VERSION "created by canmatrix"

NS_ :

BS_:

BU_: IPD

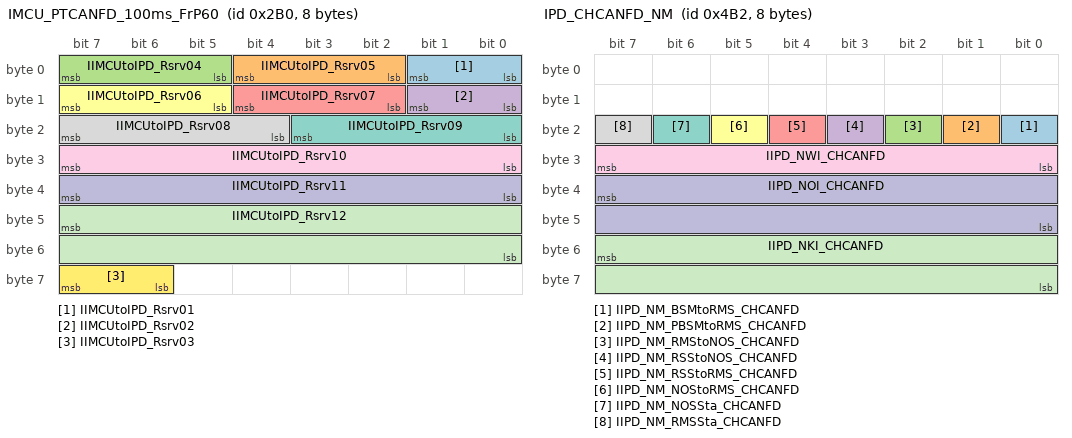
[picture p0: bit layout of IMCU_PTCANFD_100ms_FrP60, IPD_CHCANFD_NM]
BO_ 688 IMCU_PTCANFD_100ms_FrP60: 8 Vector__XXX
 SG_ IIMCUtoIPD_Rsrv01 : 1|2@0+ (1,0) [0|3] "null" IPD
 SG_ IIMCUtoIPD_Rsrv05 : 4|3@0+ (1,0) [0|7] "null" IPD
 SG_ IIMCUtoIPD_Rsrv04 : 7|3@0+ (1,0) [0|7] "null" IPD
 SG_ IIMCUtoIPD_Rsrv02 : 9|2@0+ (1,0) [0|3] "null" IPD
 SG_ IIMCUtoIPD_Rsrv07 : 12|3@0+ (1,0) [0|7] "null" IPD
 SG_ IIMCUtoIPD_Rsrv06 : 15|3@0+ (1,0) [0|7] "null" IPD
 SG_ IIMCUtoIPD_Rsrv09 : 19|4@0+ (1,0) [0|15] "null" IPD
 SG_ IIMCUtoIPD_Rsrv08 : 23|4@0+ (1,0) [0|15] "null" IPD
 SG_ IIMCUtoIPD_Rsrv10 : 31|8@0+ (1,0) [0|255] "null" IPD
 SG_ IIMCUtoIPD_Rsrv11 : 39|8@0+ (1,0) [0|255] "null" IPD
 SG_ IIMCUtoIPD_Rsrv12 : 47|16@0+ (1,0) [0|65535] "null" IPD
 SG_ IIMCUtoIPD_Rsrv03 : 63|2@0+ (1,0) [0|3] "null" IPD

BO_ 337 IPD_BKPCANFD_20ms_FrP60: 20 IPD
 SG_ IIPD_20ms_Group60_CRC : 7|8@0+ (1,0) [0|255] "null" Vector__XXX
 SG_ IIPD_20ms_Group60_RC : 11|4@0+ (1,0) [0|15] "null" Vector__XXX
 SG_ IAutoLaneChngRLaneSts : 15|4@0+ (1,0) [0|15] "null" Vector__XXX
 SG_ IIPD_20ms_Group60_Reserved1 : 23|8@0+ (1,0) [0|255] "null" Vector__XXX
 SG_ IIPD_20ms_Group60_Reserved2 : 31|8@0+ (1,0) [0|255] "null" Vector__XXX
 SG_ IAPASCSToqReqVal : 39|16@0+ (1,0) [0|65535] "Nm" Vector__XXX
 SG_ IAPAVehCrdnatPosY : 55|10@0+ (1,-512) [-512|511] "cm" Vector__XXX
 SG_ IAPAVehCrdnatAzmth : 56|9@0+ (1,0) [0|511] "degree" Vector__XXX
 SG_ IESSDirInd : 58|2@0+ (1,0) [0|3] "null" Vector__XXX
 SG_ IIPD_20ms_Group60_Reserved3 : 61|3@0+ (1,0) [0|7] "null" Vector__XXX
 SG_ IPilotTkovMsgReq : 75|4@0+ (1,0) [0|15] "null" Vector__XXX
 SG_ INOPSysSts_ZPD : 79|4@0+ (1,0) [0|15] "null" Vector__XXX
 SG_ IPrkgDstCtrlSwResp : 81|2@0+ (1,0) [0|3] "null" Vector__XXX
 SG_ IALCSysSts : 84|3@0+ (1,0) [0|7] "null" Vector__XXX
 SG_ IALCSysFltSts : 87|3@0+ (1,0) [0|7] "null" Vector__XXX
 SG_ IAPAVehCrdnatPosX : 95|12@0+ (1,-2048) [-2048|2047] "cm" Vector__XXX
 SG_ IAutoLaneChngLLaneSts : 99|4@0+ (1,0) [0|15] "null" Vector__XXX
 SG_ IIPD_20ms_Group60_Reserved4 : 105|2@0+ (1,0) [0|3] "null" Vector__XXX
 SG_ IESSSysSts : 108|3@0+ (1,0) [0|7] "null" Vector__XXX
 SG_ IESSSysFltSts : 111|3@0+ (1,0) [0|7] "null" Vector__XXX
 SG_ IIPD_20ms_Group60_Reserved5 : 112|1@0+ (1,0) [0|1] "null" Vector__XXX
 SG_ IESSDrvrTkovReq : 113|1@0+ (1,0) [0|1] "null" Vector__XXX
 SG_ ISLIFSysFltSts : 116|3@0+ (1,0) [0|7] "null" Vector__XXX
 SG_ IParkngslottype : 119|3@0+ (1,0) [0|7] "null" Vector__XXX
 SG_ IIPD_20ms_Group60_Reserved6 : 124|5@0+ (1,0) [0|31] "null" Vector__XXX
 SG_ INOPSysFltSts : 127|3@0+ (1,0) [0|7] "null" Vector__XXX
 SG_ IIPD_20ms_Group60_Reserved7 : 135|8@0+ (1,0) [0|255] "null" Vector__XXX
 SG_ IIPD_20ms_Group60_Reserved8 : 143|8@0+ (1,0) [0|255] "null" Vector__XXX
 SG_ IIPD_20ms_Group60_Reserved9 : 151|8@0+ (1,0) [0|255] "null" Vector__XXX
 SG_ IIPD_20ms_Group60_Reserved10 : 159|8@0+ (1,0) [0|255] "null" Vector__XXX

BO_ 590 IPD_BKPCANFD_50ms_FrP62: 32 IPD
 SG_ IRoadProfileShockDistL1 : 23|10@0+ (0.05,0) [0.00|51.15] "null" Vector__XXX
 SG_ IRoadProfileShockDistL2 : 25|10@0+ (0.05,0) [0.00|51.15] "null" Vector__XXX
 SG_ IRoadProfileShockDetectedL1 : 29|4@0+ (1,0) [0|15] "null" Vector__XXX
 SG_ IRoadProfileShockDistL3 : 47|10@0+ (0.05,0) [0.00|51.15] "null" Vector__XXX
 SG_ IRoadProfileShockDistR1 : 49|10@0+ (0.05,0) [0.00|51.15] "null" Vector__XXX
 SG_ IRoadProfileShockDetectedL2 : 53|4@0+ (1,0) [0|15] "null" Vector__XXX
 SG_ IRoadProfileShockDistR2 : 71|10@0+ (0.05,0) [0.00|51.15] "null" Vector__XXX
 SG_ IRoadProfileShockDistR3 : 73|10@0+ (0.05,0) [0.00|51.15] "null" Vector__XXX
 SG_ IRoadProfileShockDetectedL3 : 77|4@0+ (1,0) [0|15] "null" Vector__XXX
 SG_ IRoadProfileShockHeightL1 : 95|9@0- (0.002,0) [-0.512|0.510] "null" Vector__XXX
 SG_ IRoadProfileShockConfidenceL1 : 102|7@0+ (0.01,0) [0.00|1.27] "null" Vector__XXX
 SG_ IRoadProfileShockHeightL2 : 111|9@0- (0.002,0) [-0.512|0.510] "null" Vector__XXX
 SG_ IRoadProfileShockConfidenceL2 : 118|7@0+ (0.01,0) [0.00|1.27] "null" Vector__XXX
 SG_ IRoadProfileShockHeightL3 : 127|9@0- (0.002,0) [-0.512|0.510] "null" Vector__XXX
 SG_ IRoadProfileShockConfidenceL3 : 134|7@0+ (0.01,0) [0.00|1.27] "null" Vector__XXX
 SG_ IRoadProfileShockHeightR1 : 143|9@0- (0.002,0) [-0.512|0.510] "null" Vector__XXX
 SG_ IRoadProfileShockConfidenceR1 : 150|7@0+ (0.01,0) [0.00|1.27] "null" Vector__XXX
 SG_ IRoadProfileShockHeightR2 : 159|9@0- (0.002,0) [-0.512|0.510] "null" Vector__XXX
 SG_ IRoadProfileShockConfidenceR2 : 166|7@0+ (0.01,0) [0.00|1.27] "null" Vector__XXX
 SG_ IRoadProfileShockHeightR3 : 175|9@0- (0.002,0) [-0.512|0.510] "null" Vector__XXX
 SG_ IRoadProfileShockConfidenceR3 : 182|7@0+ (0.01,0) [0.00|1.27] "null" Vector__XXX
 SG_ IRoadHeightL : 191|9@0- (0.002,0) [-0.512|0.510] "null" Vector__XXX
 SG_ IPrvOutSts : 194|2@0+ (1,0) [0|3] "null" Vector__XXX
 SG_ IRoadProfileShockDetectedR1 : 198|4@0+ (1,0) [0|15] "null" Vector__XXX
 SG_ IRoadHeightR : 207|9@0- (0.002,0) [-0.512|0.510] "null" Vector__XXX
 SG_ IRoadProfileShockDetectedR3 : 219|4@0+ (1,0) [0|15] "null" Vector__XXX
 SG_ IRoadProfileShockDetectedR2 : 223|4@0+ (1,0) [0|15] "null" Vector__XXX

BO_ 1202 IPD_CHCANFD_NM: 8 IPD
 SG_ IIPD_NM_BSMtoRMS_CHCANFD : 16|1@0+ (1,0) [0|1] "null" Vector__XXX
 SG_ IIPD_NM_PBSMtoRMS_CHCANFD : 17|1@0+ (1,0) [0|1] "null" Vector__XXX
 SG_ IIPD_NM_RMStoNOS_CHCANFD : 18|1@0+ (1,0) [0|1] "null" Vector__XXX
 SG_ IIPD_NM_RSStoNOS_CHCANFD : 19|1@0+ (1,0) [0|1] "null" Vector__XXX
 SG_ IIPD_NM_RSStoRMS_CHCANFD : 20|1@0+ (1,0) [0|1] "null" Vector__XXX
 SG_ IIPD_NM_NOStoRMS_CHCANFD : 21|1@0+ (1,0) [0|1] "null" Vector__XXX
 SG_ IIPD_NM_NOSSta_CHCANFD : 22|1@0+ (1,0) [0|1] "null" Vector__XXX
 SG_ IIPD_NM_RMSSta_CHCANFD : 23|1@0+ (1,0) [0|1] "null" Vector__XXX
 SG_ IIPD_NWI_CHCANFD : 31|8@0+ (1,0) [0|255] "null" Vector__XXX
 SG_ IIPD_NOI_CHCANFD : 39|16@0+ (1,0) [0|65535] "null" Vector__XXX
 SG_ IIPD_NKI_CHCANFD : 55|16@0+ (1,0) [0|65535] "null" Vector__XXX

BO_ 157 LHZCU_LHBKBCANFD_10ms_FrP01: 8 Vector__XXX
 SG_ ILHZCU_10ms_Group01_CRC : 7|8@0+ (1,0) [0|255] "null" IPD
 SG_ ILHZCU_10ms_Group01_RC : 11|4@0+ (1,0) [0|15] "null" IPD
 SG_ ISCUFltLvlWarn : 13|2@0+ (1,0) [0|3] "null" IPD
 SG_ ISCUDrvMd : 15|2@0+ (1,0) [0|3] "null" IPD
 SG_ ISCUExtdShiftrFlr : 19|4@0+ (1,0) [0|15] "null" IPD
 SG_ ISCUShiftrOpngRmndr : 23|4@0+ (1,0) [0|15] "null" IPD
 SG_ IKeyAuthResp : 24|1@0+ (1,0) [0|1] "null" IPD
 SG_ ISCUParkLckReq : 26|2@0+ (1,0) [0|3] "null" IPD
 SG_ ISCUParkLckReqV : 27|1@0+ (1,0) [0|1] "null" IPD
 SG_ ILHZCU_10ms_Group01_Reserved1 : 30|3@0+ (1,0) [0|7] "null" IPD
 SG_ IDigKeyAuthReq : 31|1@0+ (1,0) [0|1] "null" IPD
 SG_ ISCUShiftrLvrRawPosn : 34|3@0+ (1,0) [0|7] "null" IPD
 SG_ ISCUParkLckReqVEPMCU : 35|1@0+ (1,0) [0|1] "null" IPD
 SG_ IScurtKeyInvd : 36|1@0+ (1,0) [0|1] "null" IPD
 SG_ ILHZCU_10ms_Group01_Reserved2 : 37|1@0+ (1,0) [0|1] "null" IPD
 SG_ ISCUParkLckReqEPMCU : 39|2@0+ (1,0) [0|3] "null" IPD
 SG_ ISCUShiftrPosnInvsn : 43|4@0+ (1,0) [0|15] "null" IPD
 SG_ ISCUShiftrLvrPosn : 47|4@0+ (1,0) [0|15] "null" IPD
 SG_ IDrvrReqParkBtn : 49|2@0+ (1,0) [0|3] "null" IPD
 SG_ ISCUShiftrLvrPosnLtchActv : 50|1@0+ (1,0) [0|1] "null" IPD
 SG_ ISecuKeyVldSts : 51|1@0+ (1,0) [0|1] "null" IPD
 SG_ ISCUDrvrIntrvnActv : 52|1@0+ (1,0) [0|1] "null" IPD
 SG_ ISCUAPAUnderCtrlActv : 55|3@0+ (1,0) [0|7] "null" IPD
 SG_ IDigKeyPEValidReq : 63|8@0+ (1,0) [0|255] "null" IPD

BO_ 546 LHZCU_LHBKBCANFD_50ms_FrP07: 16 Vector__XXX
 SG_ ILHZCU_50ms_Group07_CRC : 7|8@0+ (1,0) [0|255] "null" IPD
 SG_ ILHZCU_50ms_Group07_RC : 11|4@0+ (1,0) [0|15] "null" IPD
 SG_ ILHZCU_50ms_Group07_Reserved1 : 15|4@0+ (1,0) [0|15] "null" IPD
 SG_ IHODTchZone3Val : 23|8@0+ (1,0) [0|255] "null" IPD
 SG_ IHODTchZone1Val : 31|8@0+ (1,0) [0|255] "null" IPD
 SG_ IHODdiagSts : 35|4@0+ (1,0) [0|15] "null" IPD
 SG_ ILHZCU_50ms_Group07_Reserved2 : 39|4@0+ (1,0) [0|15] "null" IPD
 SG_ IHODDetnSts : 41|4@0+ (1,0) [0|15] "null" IPD
 SG_ IHODTchZone1Sts : 44|3@0+ (1,0) [0|7] "null" IPD
 SG_ IHODSysSts : 47|3@0+ (1,0) [0|7] "null" IPD
 SG_ IHODTchZone3Sts : 50|3@0+ (1,0) [0|7] "null" IPD
 SG_ IHODTchZone2Sts : 53|3@0+ (1,0) [0|7] "null" IPD
 SG_ IHODTchZone2Val : 63|8@0+ (1,0) [0|255] "null" IPD
 SG_ ILHZCU_50ms_Group07_Reserved3 : 71|8@0+ (1,0) [0|255] "null" IPD
 SG_ ILHZCU_50ms_Group07_Reserved4 : 79|8@0+ (1,0) [0|255] "null" IPD
 SG_ ILHZCU_50ms_Group07_Reserved5 : 87|8@0+ (1,0) [0|255] "null" IPD
 SG_ ILHZCU_50ms_Group07_Reserved6 : 95|8@0+ (1,0) [0|255] "null" IPD

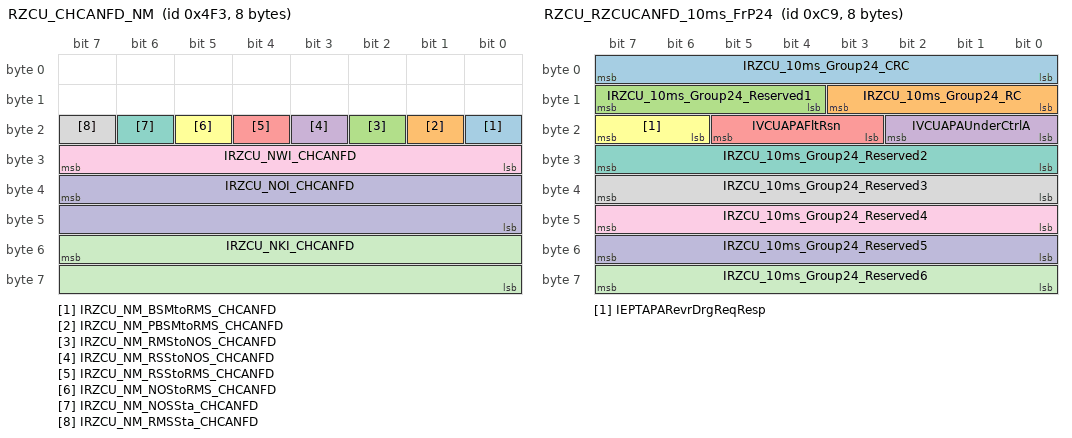
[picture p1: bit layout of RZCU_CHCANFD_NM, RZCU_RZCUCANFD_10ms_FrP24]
BO_ 1267 RZCU_CHCANFD_NM: 8 Vector__XXX
 SG_ IRZCU_NM_BSMtoRMS_CHCANFD : 16|1@0+ (1,0) [0|1] "null" Vector__XXX
 SG_ IRZCU_NM_PBSMtoRMS_CHCANFD : 17|1@0+ (1,0) [0|1] "null" Vector__XXX
 SG_ IRZCU_NM_RMStoNOS_CHCANFD : 18|1@0+ (1,0) [0|1] "null" Vector__XXX
 SG_ IRZCU_NM_RSStoNOS_CHCANFD : 19|1@0+ (1,0) [0|1] "null" Vector__XXX
 SG_ IRZCU_NM_RSStoRMS_CHCANFD : 20|1@0+ (1,0) [0|1] "null" Vector__XXX
 SG_ IRZCU_NM_NOStoRMS_CHCANFD : 21|1@0+ (1,0) [0|1] "null" Vector__XXX
 SG_ IRZCU_NM_NOSSta_CHCANFD : 22|1@0+ (1,0) [0|1] "null" Vector__XXX
 SG_ IRZCU_NM_RMSSta_CHCANFD : 23|1@0+ (1,0) [0|1] "null" Vector__XXX
 SG_ IRZCU_NWI_CHCANFD : 31|8@0+ (1,0) [0|255] "null" Vector__XXX
 SG_ IRZCU_NOI_CHCANFD : 39|16@0+ (1,0) [0|65535] "null" Vector__XXX
 SG_ IRZCU_NKI_CHCANFD : 55|16@0+ (1,0) [0|65535] "null" Vector__XXX

BO_ 1611 RZCU_RZCUCANFD_1000ms_FrP67: 16 Vector__XXX
 SG_ IIMU_SN : 16|96@1- (1,0) [-3.961408125713216879677197517E+028|3.961408125713216879677197517E+028] "null" IPD

BO_ 247 RZCU_RZCUCANFD_10ms_FrP22: 16 Vector__XXX
 SG_ IRZCU_10ms_Group22_CRC : 7|8@0+ (1,0) [0|255] "null" IPD
 SG_ IRZCU_10ms_Group22_RC : 11|4@0+ (1,0) [0|15] "null" IPD
 SG_ IRZCU_10ms_Group22_Reserved1 : 13|2@0+ (1,0) [0|3] "null" IPD
 SG_ IEPTTrOtptShaftTotMinAvlblToqV : 14|1@0+ (1,0) [0|1] "null" IPD
 SG_ IEPTTrOtptShaftTotMaxAvlblToqV : 15|1@0+ (1,0) [0|1] "null" IPD
 SG_ IEPTTrOtptShaftTotMaxAvlblToq : 23|12@0+ (0.5,-848) [-848|1199.5] "Nm" IPD
 SG_ IEPTTrOtptShaftTotMinAvlblToq : 27|12@0+ (0.5,-848) [-848|1199.5] "Nm" IPD
 SG_ IEPTTrOtptShaftTotToq : 43|12@0+ (0.5,-848) [-848|1199.5] "Nm" IPD
 SG_ IEPTTrOtptShaftTotToqV : 44|1@0+ (1,0) [0|1] "null" IPD
 SG_ IRZCU_10ms_Group22_Reserved2 : 47|3@0+ (1,0) [0|7] "null" IPD
 SG_ IRZCU_10ms_Group22_Reserved3 : 63|8@0+ (1,0) [0|255] "null" IPD
 SG_ IRZCU_10ms_Group22_Reserved4 : 71|8@0+ (1,0) [0|255] "null" IPD
 SG_ IRZCU_10ms_Group22_Reserved5 : 79|8@0+ (1,0) [0|255] "null" IPD
 SG_ IRZCU_10ms_Group22_Reserved6 : 87|8@0+ (1,0) [0|255] "null" IPD
 SG_ IRZCU_10ms_Group22_Reserved7 : 95|8@0+ (1,0) [0|255] "null" IPD

BO_ 201 RZCU_RZCUCANFD_10ms_FrP24: 8 Vector__XXX
 SG_ IRZCU_10ms_Group24_CRC : 7|8@0+ (1,0) [0|255] "null" IPD
 SG_ IRZCU_10ms_Group24_RC : 11|4@0+ (1,0) [0|15] "null" IPD
 SG_ IRZCU_10ms_Group24_Reserved1 : 15|4@0+ (1,0) [0|15] "null" IPD
 SG_ IVCUAPAUnderCtrlA : 18|3@0+ (1,0) [0|7] "null" IPD
 SG_ IVCUAPAFltRsn : 21|3@0+ (1,0) [0|7] "null" IPD
 SG_ IEPTAPARevrDrgReqResp : 23|2@0+ (1,0) [0|3] "null" IPD
 SG_ IRZCU_10ms_Group24_Reserved2 : 31|8@0+ (1,0) [0|255] "null" IPD
 SG_ IRZCU_10ms_Group24_Reserved3 : 39|8@0+ (1,0) [0|255] "null" IPD
 SG_ IRZCU_10ms_Group24_Reserved4 : 47|8@0+ (1,0) [0|255] "null" IPD
 SG_ IRZCU_10ms_Group24_Reserved5 : 55|8@0+ (1,0) [0|255] "null" IPD
 SG_ IRZCU_10ms_Group24_Reserved6 : 63|8@0+ (1,0) [0|255] "null" IPD

BO_ 143 RZCU_RZCUCANFD_10ms_FrP64: 32 Vector__XXX
 SG_ IRZCU_ZONE_10ms_Group64_CRC : 7|8@0+ (1,0) [0|255] "null" IPD
 SG_ IRZCU_ZONE_10ms_Group64_RC : 11|4@0+ (1,0) [0|15] "null" IPD
 SG_ IAngularRateXsecinfoV : 12|1@0+ (1,0) [0|1] "null" IPD
 SG_ IAccelerationZsecinfoV : 13|1@0+ (1,0) [0|1] "null" IPD
 SG_ IAccelerationYsecinfoV : 14|1@0+ (1,0) [0|1] "null" IPD
 SG_ IAccelerationXsecinfoV : 15|1@0+ (1,0) [0|1] "null" IPD
 SG_ IAccelerationXsecinfo : 23|24@0- (0.00010,0) [-838.86080|838.86070] "m/s2" IPD
 SG_ IAccelerationYsecinfo : 47|24@0- (0.00010,0) [-838.86080|838.86070] "m/s2" IPD
 SG_ IAccelerationZsecinfo : 71|24@0- (0.00010,0) [-838.86080|838.86070] "m/s2" IPD
 SG_ IAngularRateXsecinfo : 95|24@0- (0.000010,0) [-83.886080|83.886070] "°/s" IPD
 SG_ IAngularRateYsecinfo : 119|24@0- (0.000010,0) [-83.886080|83.886070] "°/s" IPD
 SG_ IAngularRateZsecinfo : 143|24@0- (0.000010,0) [-83.886080|83.886070] "°/s" IPD
 SG_ IIMUTmp : 163|12@0- (0.1,0) [-204.8|204.7] "degreecelslus" IPD
 SG_ IRZCU_ZONE_10ms_Group64_Reserved0 : 164|1@0+ (1,0) [0|1] "null" IPD
 SG_ ITireBlowoutStabCtrlSts : 165|1@0+ (1,0) [0|1] "null" IPD
 SG_ IAngularRateZsecinfoV : 166|1@0+ (1,0) [0|1] "null" IPD
 SG_ IAngularRateYsecinfoV : 167|1@0+ (1,0) [0|1] "null" IPD
 SG_ IIMUseq : 183|32@0+ (1,0) [0|4294967295] "/" IPD
 SG_ IRZCU_ZONE_10ms_Group64_Reserved1 : 211|4@0+ (1,0) [0|15] "null" IPD
 SG_ ITireBlowoutPos : 215|4@0+ (1,0) [0|15] "null" IPD
 SG_ IRZCU_ZONE_10ms_Group64_Reserved2 : 223|8@0+ (1,0) [0|255] "null" IPD
 SG_ IRZCU_ZONE_10ms_Group64_Reserved3 : 231|8@0+ (1,0) [0|255] "null" IPD
 SG_ IRZCU_ZONE_10ms_Group64_Reserved4 : 239|8@0+ (1,0) [0|255] "null" IPD
 SG_ IRZCU_ZONE_10ms_Group64_Reserved5 : 247|8@0+ (1,0) [0|255] "null" IPD
 SG_ IRZCU_ZONE_10ms_Group64_Reserved6 : 255|8@0+ (1,0) [0|255] "null" IPD

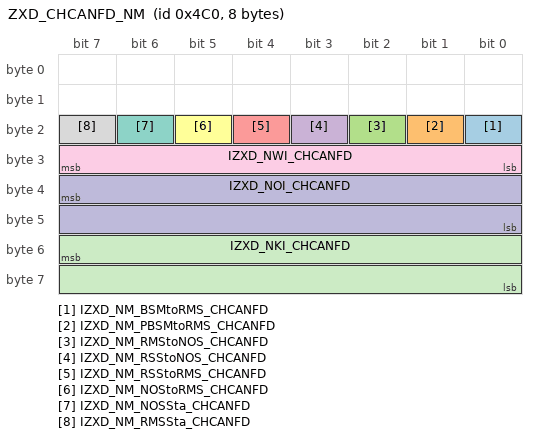
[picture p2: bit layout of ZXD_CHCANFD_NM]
BO_ 1216 ZXD_CHCANFD_NM: 8 Vector__XXX
 SG_ IZXD_NM_BSMtoRMS_CHCANFD : 16|1@0+ (1,0) [0|1] "null" Vector__XXX
 SG_ IZXD_NM_PBSMtoRMS_CHCANFD : 17|1@0+ (1,0) [0|1] "null" Vector__XXX
 SG_ IZXD_NM_RMStoNOS_CHCANFD : 18|1@0+ (1,0) [0|1] "null" Vector__XXX
 SG_ IZXD_NM_RSStoNOS_CHCANFD : 19|1@0+ (1,0) [0|1] "null" Vector__XXX
 SG_ IZXD_NM_RSStoRMS_CHCANFD : 20|1@0+ (1,0) [0|1] "null" Vector__XXX
 SG_ IZXD_NM_NOStoRMS_CHCANFD : 21|1@0+ (1,0) [0|1] "null" Vector__XXX
 SG_ IZXD_NM_NOSSta_CHCANFD : 22|1@0+ (1,0) [0|1] "null" Vector__XXX
 SG_ IZXD_NM_RMSSta_CHCANFD : 23|1@0+ (1,0) [0|1] "null" Vector__XXX
 SG_ IZXD_NWI_CHCANFD : 31|8@0+ (1,0) [0|255] "null" Vector__XXX
 SG_ IZXD_NOI_CHCANFD : 39|16@0+ (1,0) [0|65535] "null" Vector__XXX
 SG_ IZXD_NKI_CHCANFD : 55|16@0+ (1,0) [0|65535] "null" Vector__XXX

BO_ 308 ZXD_PTCANFD_20ms_FrP07: 8 IPD
 SG_ IZXD_20ms_Group07_CRC : 7|8@0+ (1,0) [0|255] "null" Vector__XXX
 SG_ IZXD_20ms_Group07_RC : 11|4@0+ (1,0) [0|15] "null" Vector__XXX
 SG_ IZXD_20ms_Group07_Reserved1 : 15|4@0+ (1,0) [0|15] "null" Vector__XXX
 SG_ IZXD_20ms_Group07_Reserved3 : 18|3@0+ (1,0) [0|7] "null" Vector__XXX
 SG_ IAPAEPBOPReq : 20|2@0+ (1,0) [0|3] "null" Vector__XXX
 SG_ IZXD_20ms_Group07_Reserved2 : 23|3@0+ (1,0) [0|7] "null" Vector__XXX
 SG_ IZXD_20ms_Group07_Reserved4 : 31|8@0+ (1,0) [0|255] "null" Vector__XXX
 SG_ IAIPkgAPASCSAcclReqVal : 34|11@0+ (0.005,-9.22) [-9.220|1.015] "m/s^2" Vector__XXX
 SG_ IZXD_20ms_Group07_Reserved5 : 37|3@0+ (1,0) [0|7] "null" Vector__XXX
 SG_ IAPASCSAcclReqSts : 38|1@0+ (1,0) [0|1] "null" Vector__XXX
 SG_ IAPAEPBOPReqV : 39|1@0+ (1,0) [0|1] "null" Vector__XXX
 SG_ IAutodDrvngSysSCSSdslReqV : 48|1@0+ (1,0) [0|1] "null" Vector__XXX
 SG_ IAutodDrvngSysSCSSdslReq : 49|1@0+ (1,0) [0|1] "null" Vector__XXX
 SG_ IZXD_20ms_Group07_Reserved6 : 55|6@0+ (1,0) [0|63] "null" Vector__XXX
 SG_ IAutodDrvngSysSCSDrvOffReqV : 56|1@0+ (1,0) [0|1] "null" Vector__XXX
 SG_ IAutodDrvngSysSCSDrvOffReq : 57|1@0+ (1,0) [0|1] "null" Vector__XXX
 SG_ IAutodDrvngSysMdReqV : 58|1@0+ (1,0) [0|1] "null" Vector__XXX
 SG_ IAutodDrvngSysMdReq : 59|1@0+ (1,0) [0|1] "null" Vector__XXX
 SG_ IAutodDrvngSysFlrStsV : 60|1@0+ (1,0) [0|1] "null" Vector__XXX
 SG_ IAutodDrvngSysFlrSts : 63|3@0+ (1,0) [0|7] "null" Vector__XXX

BO_ 429 EPS_CHCANFD_10ms_ConFrP01: 64 Vector__XXX
 SG_ Header_ID M : 7|24@0- (1,0) [-8388608|8388607] "" Vector__XXX
 SG_ Header_DLC : 31|8@0- (1,0) [-128|127] "" Vector__XXX
 SG_ IEPS_010ms_Group03_CRC m200707 : 39|8@0+ (1,0) [0|255] "null" IPD
 SG_ IEPS_010ms_Group03_RC m200707 : 43|4@0+ (1,0) [0|15] "null" IPD
 SG_ IEPSAESReqResp m200707 : 47|4@0+ (1,0) [0|15] "null" IPD
 SG_ IEPSAESStsInh m200707 : 55|8@0+ (1,0) [0|255] "null" IPD
 SG_ IEPSAESReqTorResp m200707 : 63|11@0+ (0.01,-10.24) [-10.24|10.23] "Nm" IPD
 SG_ IEPS_010ms_Group03_Reserved1 m200707 : 64|1@0+ (1,0) [0|1] "null" IPD
 SG_ IEPSVMCAngRespSts m200707 : 67|3@0+ (1,0) [0|7] "null" IPD
 SG_ IEPSAESReqTorRespV m200707 : 68|1@0+ (1,0) [0|1] "null" IPD
 SG_ IEPSVMCRespStsInh m200707 : 79|8@0+ (1,0) [0|255] "null" IPD
 SG_ IEPS_010ms_Group03_Reserved2 m200707 : 85|6@0+ (1,0) [0|63] "null" IPD
 SG_ IEPSVMCCodrivingSts m200707 : 87|2@0+ (1,0) [0|3] "null" IPD
 SG_ IEPS_010ms_Group03_Reserved3 m200707 : 95|8@0+ (1,0) [0|255] "null" IPD
 SG_ IEPS_10ms_Group01_CRC m468229 : 39|8@0+ (1,0) [0|255] "null" IPD
 SG_ IEPS_10ms_Group01_RC m468229 : 43|4@0+ (1,0) [0|15] "null" IPD
 SG_ IActuRoadWhlAngV m468229 : 44|1@0+ (1,0) [0|1] "percent" IPD
 SG_ IADASStrgDlvrdToqV m468229 : 45|1@0+ (1,0) [0|1] "percent" IPD
 SG_ IEPSDrvngMdCtrlInh m468229 : 46|1@0+ (1,0) [0|1] "percent" IPD
 SG_ IDrvrStrgDlvrdToqV m468229 : 47|1@0+ (1,0) [0|1] "percent" IPD
 SG_ IActuPnonAng m468229 : 55|16@0+ (0.0625,-2048) [-2048.0000|2047.9375] "degree
Degr" IPD
 SG_ IActuRoadWhlAng m468229 : 71|16@0+ (0.005,-163) [-163.000|164.675] "degree
Degr" IPD
 SG_ IStrgCustSetngDspCmd m468229 : 81|2@0+ (1,0) [0|3] "percent" IPD
 SG_ IEPSPriyChnlFlrSts m468229 : 83|2@0+ (1,0) [0|3] "null" IPD
 SG_ IEPSFlrSts m468229 : 85|2@0+ (1,0) [0|3] "percent" IPD
 SG_ IEPSCurntDrvMd m468229 : 87|2@0+ (1,0) [0|3] "percent" IPD
 SG_ IActuPnonAngV m468229 : 88|1@0+ (1,0) [0|1] "percent" IPD
 SG_ IEPSToqValAldMaxV m468229 : 89|1@0+ (1,0) [0|1] "percent" IPD
 SG_ IEPSLimMotToqV m468229 : 90|1@0+ (1,0) [0|1] "null" IPD
 SG_ IEPSActRetMotToqV m468229 : 91|1@0+ (1,0) [0|1] "null" IPD
 SG_ IEPS_10ms_Group01_Reserved1 m468229 : 92|1@0+ (1,0) [0|1] "null" IPD
 SG_ IChLKAAngReqResp m468229 : 95|3@0+ (1,0) [0|7] "null" IPD
 SG_ IEPS_10ms_Group01_Reserved2 m468229 : 99|4@0+ (1,0) [0|15] "null" IPD
 SG_ IEPSToqValAldMinV m468229 : 100|1@0+ (1,0) [0|1] "percent" IPD
 SG_ ICHLKAHptResp m468229 : 103|3@0+ (1,0) [0|7] "percent" IPD
 SG_ IEPS_10ms_Group01_Reserved3 m468229 : 111|8@0+ (1,0) [0|255] "null" IPD
 SG_ IADASStrgDlvrdToq m468229 : 114|11@0+ (0.01,-10.24) [-10.24|10.23] "Nm" IPD
 SG_ IEPS_10ms_Group01_Reserved4 m468229 : 116|2@0+ (1,0) [0|3] "null" IPD
 SG_ IChLKAToqReqResp m468229 : 119|3@0+ (1,0) [0|7] "null" IPD
 SG_ IEPSToqValAldMax m468229 : 130|11@0+ (0.01,-10.24) [-10.24|10.23] "Nm" IPD
 SG_ IEPSCoDrivingSts m468229 : 132|2@0+ (1,0) [0|3] "null" IPD
 SG_ IEPS_10ms_Group01_Reserved5 m468229 : 135|3@0+ (1,0) [0|7] "null" IPD
 SG_ IEPSToqValAldMin m468229 : 146|11@0+ (0.01,-10.24) [-10.24|10.23] "Nm" IPD
 SG_ IEPS_10ms_Group01_Reserved6 m468229 : 151|5@0+ (1,0) [0|31] "null" IPD
 SG_ IEPSActRetMotToq m468229 : 167|16@0+ (0.00097656,-32) [-32.00000000|31.99885960] "Nm" IPD
 SG_ IEPS_10ms_Group01_Reserved9 m468229 : 183|8@0+ (1,0) [0|255] "null" IPD
 SG_ IDrvrStrgDlvrdToq m468229 : 191|12@0+ (0.01,-20.48) [-20.48|20.47] "Nm" IPD
 SG_ IEPS_10ms_Group01_Reserved10 m468229 : 195|4@0+ (1,0) [0|15] "null" IPD
 SG_ IEPS_10ms_Group01_Reserved11 m468229 : 207|8@0+ (1,0) [0|255] "null" IPD
 SG_ IEPSLimMotToq m468229 : 215|16@0+ (0.00097656,-32) [-32.00000000|31.99885960] "Nm" IPD
 SG_ IEPS_10ms_Group02_CRC m468230 : 39|8@0+ (1,0) [0|255] "null" IPD
 SG_ IEPS_10ms_Group02_RC m468230 : 43|4@0+ (1,0) [0|15] "null" IPD
 SG_ IEPSAIPkgAngReqResp m468230 : 47|4@0+ (1,0) [0|15] "percent" IPD
 SG_ IEPSAIPkgAngReqRespInh m468230 : 55|8@0+ (1,0) [0|255] "percent" IPD
 SG_ IEPSAIPltAngRespStsInh m468230 : 63|8@0+ (1,0) [0|255] "null" IPD
 SG_ IEPS_10ms_Group02_Reserved1 m468230 : 66|3@0+ (1,0) [0|7] "null" IPD
 SG_ IEPSAIPltAvlLvl m468230 : 68|2@0+ (1,0) [0|3] "null" IPD
 SG_ IEPSAIPltAngRespSts m468230 : 71|3@0+ (1,0) [0|7] "null" IPD
 SG_ IActuRoadWhlAngGrdV m468230 : 72|1@0+ (1,0) [0|1] "null" IPD
 SG_ IEPS_10ms_Group02_Reserved2 m468230 : 78|6@0+ (1,0) [0|63] "null" IPD
 SG_ IEPSAIPltCtrlChannel m468230 : 79|1@0+ (1,0) [0|1] "null" IPD
 SG_ IActuRoadWhlAngGrd m468230 : 87|16@0+ (0.005,-163) [-163.000|164.675] "deg_s" IPD

BO_ 173 EPS_CHCANFD_10ms_ConFrP05: 64 Vector__XXX
 SG_ Header_ID M : 7|24@0- (1,0) [-8388608|8388607] "" Vector__XXX
 SG_ Header_DLC : 31|8@0- (1,0) [-128|127] "" Vector__XXX
 SG_ IEPS_10ms_Group05_CRC m468244 : 39|8@0+ (1,0) [0|255] "null" IPD
 SG_ IEPS_10ms_Group05_RC m468244 : 43|4@0+ (1,0) [0|15] "null" IPD
 SG_ IStrgWhlAngSnsrFlt m468244 : 44|1@0+ (1,0) [0|1] "null" IPD
 SG_ IStrgWhlAngV m468244 : 45|1@0+ (1,0) [0|1] "null" IPD
 SG_ IStrgWhlAngSnsrMultCapb m468244 : 46|1@0+ (1,0) [0|1] "null" IPD
 SG_ IStrgWhlAngSnsrInid m468244 : 47|1@0+ (1,0) [0|1] "null" IPD
 SG_ IStrgWhlAng m468244 : 55|16@0+ (0.0625,-2048) [-2048.0000|2047.9375] "degreeDegr" IPD
 SG_ IStrgWhlAngGrd m468244 : 71|12@0+ (1,-2048) [-2048|2047] "degree/s" IPD
 SG_ IEPS_10ms_Group05_Reserved1 m468244 : 73|2@0+ (1,0) [0|3] "null" IPD
 SG_ IStrgWhlAngSnsrCalSts m468244 : 75|2@0+ (1,0) [0|3] "null" IPD
 SG_ IEPS_10ms_Group05_Reserved2 m468244 : 87|8@0+ (1,0) [0|255] "null" IPD
 SG_ IEPS_10ms_Group05_Reserved3 m468244 : 95|8@0+ (1,0) [0|255] "null" IPD

BO_ 184 IBS_CHCANFD_10ms_ConFrP04: 64 Vector__XXX
 SG_ Header_ID M : 7|24@0- (1,0) [-8388608|8388607] "" Vector__XXX
 SG_ Header_DLC : 31|8@0- (1,0) [-128|127] "" Vector__XXX
 SG_ IIBS_10ms_Group04_CRC m468231 : 39|8@0+ (1,0) [0|255] "null" IPD
 SG_ IIBS_10ms_Group04_RC m468231 : 43|4@0+ (1,0) [0|15] "null" IPD
 SG_ IIBS_10ms_Group04_Reserved1 m468231 : 47|4@0+ (1,0) [0|15] "null" IPD
 SG_ IBrkPdlPos m468231 : 55|8@0+ (0.392157,0) [0.000000|100.000035] "Percent" IPD
 SG_ IIBS_10ms_Group04_Reserved2 m468231 : 61|6@0+ (1,0) [0|63] "null" IPD
 SG_ IBrkSysBrkLghtsReqd m468231 : 62|1@0+ (1,0) [0|1] "null" IPD
 SG_ IBrkPdlPosV m468231 : 63|1@0+ (1,0) [0|1] "null" IPD
 SG_ IIBS_10ms_Group04_Reserved3 m468231 : 71|8@0+ (1,0) [0|255] "null" IPD
 SG_ IIBS_10ms_Group04_Reserved4 m468231 : 79|8@0+ (1,0) [0|255] "null" IPD
 SG_ IIBS_10ms_Group04_Reserved5 m468231 : 87|8@0+ (1,0) [0|255] "null" IPD
 SG_ IIBS_10ms_Group04_Reserved6 m468231 : 95|8@0+ (1,0) [0|255] "null" IPD
 SG_ IActuOtptRodTrvlSts m468232 : 33|2@0+ (1,0) [0|3] "null" Vector__XXX
 SG_ IActuOtptRodTrvl m468232 : 71|12@0+ (0.015625,-5) [-5.000000|58.984375] "null" Vector__XXX

BO_ 394 IBS_CHCANFD_20ms_ConFrP10: 64 Vector__XXX
 SG_ Header_ID M : 7|24@0- (1,0) [-8388608|8388607] "" Vector__XXX
 SG_ Header_DLC : 31|8@0- (1,0) [-128|127] "" Vector__XXX
 SG_ IIBS_20ms_Group10_CRC m468233 : 39|8@0+ (1,0) [0|255] "null" IPD
 SG_ IIBS_20ms_Group10_RC m468233 : 43|4@0+ (1,0) [0|15] "null" IPD
 SG_ IBrkPdlDrvrAppdPrsV m468233 : 44|1@0+ (1,0) [0|1] "null" IPD
 SG_ IBrkPdlDrvrAppdPrsDetV m468233 : 45|1@0+ (1,0) [0|1] "null" IPD
 SG_ IBrkPdlDrvrAppdPrsDet m468233 : 46|1@0+ (1,0) [0|1] "null" IPD
 SG_ IBrkDiscTemSts m468233 : 47|1@0+ (1,0) [0|1] "null" IPD
 SG_ IBrkPdlDrvrAppdPrs m468233 : 55|8@0+ (75,0) [0|19125] "kPa" IPD
 SG_ IBrkPdlMdlSts m468233 : 57|2@0+ (1,0) [0|3] "null" IPD
 SG_ IDrvrReqOtptRodTrvlSts m468233 : 59|2@0+ (1,0) [0|3] "null" IPD
 SG_ IBrkPdlSimltdPrsV m468233 : 60|1@0+ (1,0) [0|1] "null" IPD
 SG_ IBrkPdlAppd m468233 : 61|1@0+ (1,0) [0|1] "null" IPD
 SG_ IBrkPdlAppdV m468233 : 63|2@0+ (1,0) [0|3] "null" IPD
 SG_ IBrkPdlSimltdPrs m468233 : 71|8@0+ (75,0) [0|19125] "kPa" IPD
 SG_ IBrkFludLvlLowV m468233 : 72|1@0+ (1,0) [0|1] "null" IPD
 SG_ IBrkFludLvlLow m468233 : 73|1@0+ (1,0) [0|1] "null" IPD
 SG_ IBrkPdlMdlActSts m468233 : 75|2@0+ (1,0) [0|3] "null" IPD
 SG_ IIBS_20ms_Group10_Reserved1 m468233 : 79|4@0+ (1,0) [0|15] "null" IPD
 SG_ IDrvrReqOtptRodTrvl m468233 : 83|12@0+ (0.015625,-5) [-5.000000|58.984375] "mm" IPD
 SG_ IIBS_20ms_Group10_Reserved2 m468233 : 87|4@0+ (1,0) [0|15] "null" IPD
 SG_ IIBS_20ms_Group13_CRC m468240 : 39|8@0+ (1,0) [0|255] "null" IPD
 SG_ IIBS_20ms_Group13_RC m468240 : 43|4@0+ (1,0) [0|15] "null" IPD
 SG_ IACCBrkngA m468240 : 44|1@0+ (1,0) [0|1] "null" IPD
 SG_ IChAEBDclReqResp m468240 : 47|3@0+ (1,0) [0|7] "null" IPD
 SG_ IChACCReqFlrSts m468240 : 49|2@0+ (1,0) [0|3] "null" IPD
 SG_ IChACCAccReqResp m468240 : 52|3@0+ (1,0) [0|7] "null" IPD
 SG_ IChAEBPrflReqResp m468240 : 55|3@0+ (1,0) [0|7] "null" IPD
 SG_ IAutodDrvngSysMdReqRespV m468240 : 56|1@0+ (1,0) [0|1] "null" IPD
 SG_ IAutodDrvngSysMdReqResp m468240 : 57|1@0+ (1,0) [0|1] "null" IPD
 SG_ IChAEBHydBrkAstReqResp m468240 : 60|3@0+ (1,0) [0|7] "null" IPD
 SG_ IChAEBBrkJerkReqResp m468240 : 63|3@0+ (1,0) [0|7] "null" IPD
 SG_ ISCSAutodDrvngSysSts m468240 : 66|3@0+ (1,0) [0|7] "null" IPD
 SG_ ISCSAPAAcclAV m468240 : 67|1@0+ (1,0) [0|1] "null" IPD
 SG_ ISCSAPAAcclA m468240 : 68|1@0+ (1,0) [0|1] "null" IPD
 SG_ IExtnlBrkPrioV m468240 : 69|1@0+ (1,0) [0|1] "null" IPD
 SG_ IExtnlBrkPrio m468240 : 70|1@0+ (1,0) [0|1] "null" IPD
 SG_ IEmgcBrkReqdByIECUSts m468240 : 71|1@0+ (1,0) [0|1] "null" IPD
 SG_ ITCSDrvrItnt m468240 : 72|1@0+ (1,0) [0|1] "null" IPD
 SG_ IMultColBrkAvlblySts m468240 : 73|1@0+ (1,0) [0|1] "null" IPD
 SG_ IChRCTBDclReqResp m468240 : 76|3@0+ (1,0) [0|7] "null" IPD
 SG_ ISCSVehHoldAV m468240 : 77|1@0+ (1,0) [0|1] "null" IPD
 SG_ ISCSVehHoldA m468240 : 78|1@0+ (1,0) [0|1] "null" IPD
 SG_ ISCSAutodDrvngSysStsV m468240 : 79|1@0+ (1,0) [0|1] "null" IPD
 SG_ IVehSdslStsV m468240 : 80|1@0+ (1,0) [0|1] "null" IPD
 SG_ IChRCTBPrflReqResp m468240 : 83|3@0+ (1,0) [0|7] "null" IPD
 SG_ IWhlBrkPrsSts m468240 : 84|1@0+ (1,0) [0|1] "null" IPD
 SG_ IBrkSysRddySysSts m468240 : 85|1@0+ (1,0) [0|1] "null" IPD
 SG_ IVehSdslSts m468240 : 87|2@0+ (1,0) [0|3] "null" IPD
 SG_ IIBS_20ms_Group13_Reserved1 m468240 : 92|5@0+ (1,0) [0|31] "null" IPD
 SG_ IIBSAPASysFltSts m468240 : 95|3@0+ (1,0) [0|7] "null" IPD

BO_ 222 ICBAD_CHCANFD_10ms_ConFrP01: 64 IPD
 SG_ Header_ID M : 7|24@0- (1,0) [-8388608|8388607] "" Vector__XXX
 SG_ Header_DLC : 31|8@0- (1,0) [-128|127] "" Vector__XXX
 SG_ IICBAD_10ms_Group01_CRC m468242 : 39|8@0+ (1,0) [0|255] "null" Vector__XXX
 SG_ IICBAD_10ms_Group01_RC m468242 : 43|4@0+ (1,0) [0|15] "null" Vector__XXX
 SG_ IICBAD_10ms_Group01_Reserved1 m468242 : 46|3@0+ (1,0) [0|7] "null" Vector__XXX
 SG_ IAIPltEPSReqRdWhlAngV m468242 : 47|1@0+ (1,0) [0|1] "null" Vector__XXX
 SG_ IPltEPSRdWhlAngReqStsV m468242 : 48|1@0+ (1,0) [0|1] "null" Vector__XXX
 SG_ IPltEPSRdWhlAngReqSts m468242 : 51|3@0+ (1,0) [0|7] "null" Vector__XXX
 SG_ IICBAD_10ms_Group01_Reserved2 m468242 : 55|4@0+ (1,0) [0|15] "null" Vector__XXX
 SG_ IICBAD_10ms_Group01_Reserved3 m468242 : 63|8@0+ (1,0) [0|255] "null" Vector__XXX
 SG_ IICBAD_10ms_Group01_Reserved4 m468242 : 71|8@0+ (1,0) [0|255] "null" Vector__XXX
 SG_ IAIPltEPSReqRdWhlAng m468242 : 79|16@0+ (0.005,-163) [-163.000|164.675] "DegreeDegr" Vector__XXX
 SG_ IICBAD_10ms_Group01_Reserved5 m468242 : 88|1@0+ (1,0) [0|1] "null" Vector__XXX
 SG_ IEPSToqAppdCoefnt m468242 : 95|7@0+ (0.01,0) [0.00|1.27] "ms" Vector__XXX

BA_DEF_ BO_ "FrameTriggeringName" STRING;
BA_DEF_ BO_ "GenMsgCycleTime" INT 0 65535;
BA_DEF_ BO_ "GenMsgDelayTime" INT 0 65535;
BA_DEF_ BO_ "GenMsgSendType" ENUM  "cyclicX","spontanX","cyclicIfActiveX","spontanWithDelay","cyclicAndSpontanX","cyclicAndSpontanWithDelay","spontanWithRepitition","cyclicIfActiveAndSpontanWD","cyclicIfActiveFast","cyclicWithRepeatOnDemand","none";
BA_DEF_ BO_ "GenMsgStartValue" STRING;
BA_DEF_ BO_ "PduName" STRING;
BA_DEF_ BO_ "SystemMessageLongSymbol" STRING;
BA_DEF_ BO_ "VFrameFormat" ENUM  "StandardCAN","ExtendedCAN","reserved","reserved","reserved","reserved","reserved","reserved","reserved","reserved","reserved","reserved","reserved","reserved","StandardCAN_FD","ExtendedCAN_FD";
BA_DEF_ SG_ "CompuMethodName" STRING;
BA_DEF_ SG_ "GenSigStartValue" FLOAT 0 100000000000;
BA_DEF_ SG_ "ISignalName" STRING;
BA_DEF_ SG_ "LongName" STRING;
BA_DEF_ SG_ "SysSignalName" STRING;
BA_DEF_ SG_ "SystemSignalLongSymbol" STRING;
BA_ "FrameTriggeringName" BO_ 688 "IMCU_PTCANFD_100ms_FrP60";
BA_ "GenMsgCycleTime" BO_ 688 100;
BA_ "GenMsgSendType" BO_ 688 0;
BA_ "GenMsgStartValue" BO_ 688 "0000000000000000";
BA_ "PduName" BO_ 688 "IMCU_100ms_PDU60";
BA_ "VFrameFormat" BO_ 688 14;
BA_ "FrameTriggeringName" BO_ 337 "IPD_BKPCANFD_20ms_FrP60";
BA_ "GenMsgCycleTime" BO_ 337 20;
BA_ "GenMsgSendType" BO_ 337 0;
BA_ "GenMsgStartValue" BO_ 337 "0000ffff0000003c000001000007011fffffffff";
BA_ "PduName" BO_ 337 "IPD_20ms_PDU60";
BA_ "VFrameFormat" BO_ 337 14;
BA_ "FrameTriggeringName" BO_ 590 "IPD_BKPCANFD_50ms_FrP62";
BA_ "GenMsgCycleTime" BO_ 590 50;
BA_ "GenMsgSendType" BO_ 590 0;
BA_ "GenMsgStartValue" BO_ 590 "0000000000000000000000000000000000000000000000000000000000000000";
BA_ "PduName" BO_ 590 "IPD_50ms_PDU62";
BA_ "VFrameFormat" BO_ 590 14;
BA_ "FrameTriggeringName" BO_ 1202 "IPD_CHCANFD_NM";
BA_ "GenMsgSendType" BO_ 1202 1;
BA_ "GenMsgStartValue" BO_ 1202 "0000000000000000";
BA_ "PduName" BO_ 1202 "NmPDU_CHCANFD_IPD";
BA_ "VFrameFormat" BO_ 1202 14;
BA_ "FrameTriggeringName" BO_ 157 "LHZCU_LHBKBCANFD_10ms_FrP01";
BA_ "GenMsgCycleTime" BO_ 157 10;
BA_ "GenMsgSendType" BO_ 157 0;
BA_ "GenMsgStartValue" BO_ 157 "000000783a0f0800";
BA_ "PduName" BO_ 157 "LHZCU_10ms_PDU01";
BA_ "VFrameFormat" BO_ 157 14;
BA_ "FrameTriggeringName" BO_ 546 "LHZCU_LHBKBCANFD_50ms_FrP07";
BA_ "GenMsgCycleTime" BO_ 546 50;
BA_ "GenMsgSendType" BO_ 546 0;
BA_ "GenMsgStartValue" BO_ 546 "00f00000f0008000ffffffff00000000";
BA_ "PduName" BO_ 546 "LHZCU_50ms_PDU07";
BA_ "VFrameFormat" BO_ 546 14;
BA_ "FrameTriggeringName" BO_ 1267 "RZCU_CHCANFD_NM";
BA_ "GenMsgSendType" BO_ 1267 1;
BA_ "GenMsgStartValue" BO_ 1267 "0000000000000000";
BA_ "PduName" BO_ 1267 "NmPDU_CHCANFD_RZCU";
BA_ "VFrameFormat" BO_ 1267 14;
BA_ "FrameTriggeringName" BO_ 1611 "RZCU_RZCUCANFD_1000ms_FrP67";
BA_ "GenMsgCycleTime" BO_ 1611 1000;
BA_ "GenMsgSendType" BO_ 1611 0;
BA_ "GenMsgStartValue" BO_ 1611 "00000000000000000000000000000000";
BA_ "PduName" BO_ 1611 "RZCU_1000ms_PDU67";
BA_ "VFrameFormat" BO_ 1611 14;
BA_ "FrameTriggeringName" BO_ 247 "RZCU_RZCUCANFD_10ms_FrP22";
BA_ "GenMsgCycleTime" BO_ 247 10;
BA_ "GenMsgSendType" BO_ 247 0;
BA_ "GenMsgStartValue" BO_ 247 "00306a0000f000ffffffffff00000000";
BA_ "PduName" BO_ 247 "RZCU_10ms_PDU22";
BA_ "VFrameFormat" BO_ 247 14;
BA_ "FrameTriggeringName" BO_ 201 "RZCU_RZCUCANFD_10ms_FrP24";
BA_ "GenMsgCycleTime" BO_ 201 10;
BA_ "GenMsgSendType" BO_ 201 0;
BA_ "GenMsgStartValue" BO_ 201 "00f000ffffffffff";
BA_ "PduName" BO_ 201 "RZCU_10ms_PDU24";
BA_ "VFrameFormat" BO_ 201 14;
BA_ "FrameTriggeringName" BO_ 143 "RZCU_RZCUCANFD_10ms_FrP64";
BA_ "GenMsgCycleTime" BO_ 143 10;
BA_ "GenMsgSendType" BO_ 143 0;
BA_ "GenMsgStartValue" BO_ 143 "00000000000000000000000000000000000000001000000000000fffffffffff";
BA_ "PduName" BO_ 143 "RZCU_10ms_PDU64";
BA_ "VFrameFormat" BO_ 143 14;
BA_ "FrameTriggeringName" BO_ 1216 "ZXD_CHCANFD_NM";
BA_ "GenMsgSendType" BO_ 1216 1;
BA_ "GenMsgStartValue" BO_ 1216 "0000000000000000";
BA_ "PduName" BO_ 1216 "NmPDU_CHCANFD_ZXD";
BA_ "VFrameFormat" BO_ 1216 14;
BA_ "FrameTriggeringName" BO_ 308 "ZXD_PTCANFD_20ms_FrP07";
BA_ "GenMsgCycleTime" BO_ 308 20;
BA_ "GenMsgSendType" BO_ 308 0;
BA_ "GenMsgStartValue" BO_ 308 "00f0e7ff3800fc00";
BA_ "PduName" BO_ 308 "ZXD_20ms_PDU07";
BA_ "VFrameFormat" BO_ 308 14;
BA_ "FrameTriggeringName" BO_ 429 "EPS_CHCANFD_10ms_ConFrP01";
BA_ "GenMsgCycleTime" BO_ 429 10;
BA_ "GenMsgSendType" BO_ 429 1;
BA_ "PduName" BO_ 429 "EPS_ZONE_CHCANFD_10ms_Container01";
BA_ "VFrameFormat" BO_ 429 14;
BA_ "FrameTriggeringName" BO_ 173 "EPS_CHCANFD_10ms_ConFrP05";
BA_ "GenMsgCycleTime" BO_ 173 10;
BA_ "GenMsgSendType" BO_ 173 1;
BA_ "PduName" BO_ 173 "SAS_ZONE_CHCANFD_10ms_Container01";
BA_ "VFrameFormat" BO_ 173 14;
BA_ "FrameTriggeringName" BO_ 184 "IBS_CHCANFD_10ms_ConFrP04";
BA_ "GenMsgCycleTime" BO_ 184 10;
BA_ "GenMsgSendType" BO_ 184 1;
BA_ "PduName" BO_ 184 "IBS_CHCANFD_10ms_Container01";
BA_ "VFrameFormat" BO_ 184 14;
BA_ "FrameTriggeringName" BO_ 394 "IBS_CHCANFD_20ms_ConFrP10";
BA_ "GenMsgCycleTime" BO_ 394 20;
BA_ "GenMsgSendType" BO_ 394 1;
BA_ "PduName" BO_ 394 "IBS_CHCANFD_20ms_Container01";
BA_ "VFrameFormat" BO_ 394 14;
BA_ "FrameTriggeringName" BO_ 222 "ICBAD_CHCANFD_10ms_ConFrP01";
BA_ "GenMsgCycleTime" BO_ 222 10;
BA_ "GenMsgSendType" BO_ 222 1;
BA_ "PduName" BO_ 222 "ICBAD_CHCANFD_10ms_Container01";
BA_ "VFrameFormat" BO_ 222 14;
BA_ "CompuMethodName" SG_ 688 IIMCUtoIPD_Rsrv01 "IMCUtoIPD_Rsrv01";
BA_ "ISignalName" SG_ 688 IIMCUtoIPD_Rsrv01 "IIMCUtoIPD_Rsrv01";
BA_ "LongName" SG_ 688 IIMCUtoIPD_Rsrv01 "IMCU_to_IPD_Reserved01";
BA_ "SysSignalName" SG_ 688 IIMCUtoIPD_Rsrv01 "IMCUtoIPD_Rsrv01";
BA_ "CompuMethodName" SG_ 688 IIMCUtoIPD_Rsrv05 "IMCUtoIPD_Rsrv05";
BA_ "ISignalName" SG_ 688 IIMCUtoIPD_Rsrv05 "IIMCUtoIPD_Rsrv05";
BA_ "LongName" SG_ 688 IIMCUtoIPD_Rsrv05 "IMCU_to_IPD_Reserved05";
BA_ "SysSignalName" SG_ 688 IIMCUtoIPD_Rsrv05 "IMCUtoIPD_Rsrv05";
BA_ "CompuMethodName" SG_ 688 IIMCUtoIPD_Rsrv04 "IMCUtoIPD_Rsrv04";
BA_ "ISignalName" SG_ 688 IIMCUtoIPD_Rsrv04 "IIMCUtoIPD_Rsrv04";
BA_ "LongName" SG_ 688 IIMCUtoIPD_Rsrv04 "IMCU_to_IPD_Reserved04";
BA_ "SysSignalName" SG_ 688 IIMCUtoIPD_Rsrv04 "IMCUtoIPD_Rsrv04";
BA_ "CompuMethodName" SG_ 688 IIMCUtoIPD_Rsrv02 "IMCUtoIPD_Rsrv02";
BA_ "ISignalName" SG_ 688 IIMCUtoIPD_Rsrv02 "IIMCUtoIPD_Rsrv02";
BA_ "LongName" SG_ 688 IIMCUtoIPD_Rsrv02 "IMCU_to_IPD_Reserved02";
BA_ "SysSignalName" SG_ 688 IIMCUtoIPD_Rsrv02 "IMCUtoIPD_Rsrv02";
BA_ "CompuMethodName" SG_ 688 IIMCUtoIPD_Rsrv07 "IMCUtoIPD_Rsrv07";
BA_ "ISignalName" SG_ 688 IIMCUtoIPD_Rsrv07 "IIMCUtoIPD_Rsrv07";
BA_ "LongName" SG_ 688 IIMCUtoIPD_Rsrv07 "IMCU_to_IPD_Reserved07";
BA_ "SysSignalName" SG_ 688 IIMCUtoIPD_Rsrv07 "IMCUtoIPD_Rsrv07";
BA_ "CompuMethodName" SG_ 688 IIMCUtoIPD_Rsrv06 "IMCUtoIPD_Rsrv06";
BA_ "ISignalName" SG_ 688 IIMCUtoIPD_Rsrv06 "IIMCUtoIPD_Rsrv06";
BA_ "LongName" SG_ 688 IIMCUtoIPD_Rsrv06 "IMCU_to_IPD_Reserved06";
BA_ "SysSignalName" SG_ 688 IIMCUtoIPD_Rsrv06 "IMCUtoIPD_Rsrv06";
BA_ "CompuMethodName" SG_ 688 IIMCUtoIPD_Rsrv09 "IMCUtoIPD_Rsrv09";
BA_ "ISignalName" SG_ 688 IIMCUtoIPD_Rsrv09 "IIMCUtoIPD_Rsrv09";
BA_ "LongName" SG_ 688 IIMCUtoIPD_Rsrv09 "IMCU_to_IPD_Reserved09";
BA_ "SysSignalName" SG_ 688 IIMCUtoIPD_Rsrv09 "IMCUtoIPD_Rsrv09";
BA_ "CompuMethodName" SG_ 688 IIMCUtoIPD_Rsrv08 "IMCUtoIPD_Rsrv08";
BA_ "ISignalName" SG_ 688 IIMCUtoIPD_Rsrv08 "IIMCUtoIPD_Rsrv08";
BA_ "LongName" SG_ 688 IIMCUtoIPD_Rsrv08 "IMCU_to_IPD_Reserved08";
BA_ "SysSignalName" SG_ 688 IIMCUtoIPD_Rsrv08 "IMCUtoIPD_Rsrv08";
BA_ "CompuMethodName" SG_ 688 IIMCUtoIPD_Rsrv10 "IMCUtoIPD_Rsrv10";
BA_ "ISignalName" SG_ 688 IIMCUtoIPD_Rsrv10 "IIMCUtoIPD_Rsrv10";
BA_ "LongName" SG_ 688 IIMCUtoIPD_Rsrv10 "IMCU_to_IPD_Reserved10";
BA_ "SysSignalName" SG_ 688 IIMCUtoIPD_Rsrv10 "IMCUtoIPD_Rsrv10";
BA_ "CompuMethodName" SG_ 688 IIMCUtoIPD_Rsrv11 "IMCUtoIPD_Rsrv11";
BA_ "ISignalName" SG_ 688 IIMCUtoIPD_Rsrv11 "IIMCUtoIPD_Rsrv11";
BA_ "LongName" SG_ 688 IIMCUtoIPD_Rsrv11 "IMCU_to_IPD_Reserved11";
BA_ "SysSignalName" SG_ 688 IIMCUtoIPD_Rsrv11 "IMCUtoIPD_Rsrv11";
BA_ "CompuMethodName" SG_ 688 IIMCUtoIPD_Rsrv12 "IMCUtoIPD_Rsrv12";
BA_ "ISignalName" SG_ 688 IIMCUtoIPD_Rsrv12 "IIMCUtoIPD_Rsrv12";
BA_ "LongName" SG_ 688 IIMCUtoIPD_Rsrv12 "IMCU_to_IPD_Reserved12";
BA_ "SysSignalName" SG_ 688 IIMCUtoIPD_Rsrv12 "IMCUtoIPD_Rsrv12";
BA_ "CompuMethodName" SG_ 688 IIMCUtoIPD_Rsrv03 "IMCUtoIPD_Rsrv03";
BA_ "ISignalName" SG_ 688 IIMCUtoIPD_Rsrv03 "IIMCUtoIPD_Rsrv03";
BA_ "LongName" SG_ 688 IIMCUtoIPD_Rsrv03 "IMCU_to_IPD_Reserved03";
BA_ "SysSignalName" SG_ 688 IIMCUtoIPD_Rsrv03 "IMCUtoIPD_Rsrv03";
BA_ "CompuMethodName" SG_ 337 IIPD_20ms_Group60_CRC "IPD_20ms_Group60_CRC";
BA_ "ISignalName" SG_ 337 IIPD_20ms_Group60_CRC "IIPD_20ms_Group60_CRC";
BA_ "SysSignalName" SG_ 337 IIPD_20ms_Group60_CRC "IPD_20ms_Group60_CRC";
BA_ "CompuMethodName" SG_ 337 IIPD_20ms_Group60_RC "IPD_20ms_Group60_RC";
BA_ "ISignalName" SG_ 337 IIPD_20ms_Group60_RC "IIPD_20ms_Group60_RC";
BA_ "SysSignalName" SG_ 337 IIPD_20ms_Group60_RC "IPD_20ms_Group60_RC";
BA_ "CompuMethodName" SG_ 337 IAutoLaneChngRLaneSts "AutoLaneChngRLaneSts";
BA_ "ISignalName" SG_ 337 IAutoLaneChngRLaneSts "IAutoLaneChngRLaneSts";
BA_ "LongName" SG_ 337 IAutoLaneChngRLaneSts "Auto_Lane_Change_Right_Lane_Status";
BA_ "SysSignalName" SG_ 337 IAutoLaneChngRLaneSts "AutoLaneChngRLaneSts";
BA_ "CompuMethodName" SG_ 337 IIPD_20ms_Group60_Reserved1 "IPD_20ms_Group60_Reserved1";
BA_ "GenSigStartValue" SG_ 337 IIPD_20ms_Group60_Reserved1 255;
BA_ "ISignalName" SG_ 337 IIPD_20ms_Group60_Reserved1 "IIPD_20ms_Group60_Reserved1";
BA_ "SysSignalName" SG_ 337 IIPD_20ms_Group60_Reserved1 "IPD_20ms_Group60_Reserved1";
BA_ "CompuMethodName" SG_ 337 IIPD_20ms_Group60_Reserved2 "IPD_20ms_Group60_Reserved2";
BA_ "GenSigStartValue" SG_ 337 IIPD_20ms_Group60_Reserved2 255;
BA_ "ISignalName" SG_ 337 IIPD_20ms_Group60_Reserved2 "IIPD_20ms_Group60_Reserved2";
BA_ "SysSignalName" SG_ 337 IIPD_20ms_Group60_Reserved2 "IPD_20ms_Group60_Reserved2";
BA_ "CompuMethodName" SG_ 337 IAPASCSToqReqVal "APASCSToqReqVal";
BA_ "ISignalName" SG_ 337 IAPASCSToqReqVal "IAPASCSToqReqVal";
BA_ "LongName" SG_ 337 IAPASCSToqReqVal "Advance Park Assist Stability Control System Torque Request Value";
BA_ "SysSignalName" SG_ 337 IAPASCSToqReqVal "APASCSToqReqVal";
BA_ "CompuMethodName" SG_ 337 IAPAVehCrdnatPosY "APAVehCrdnatPosY";
BA_ "ISignalName" SG_ 337 IAPAVehCrdnatPosY "IAPAVehCrdnatPosY";
BA_ "LongName" SG_ 337 IAPAVehCrdnatPosY "Advanced_Park_Assist_Vehicle_Coordinate_Position_Y";
BA_ "SysSignalName" SG_ 337 IAPAVehCrdnatPosY "APAVehCrdnatPosY";
BA_ "CompuMethodName" SG_ 337 IAPAVehCrdnatAzmth "APAVehCrdnatAzmth";
BA_ "ISignalName" SG_ 337 IAPAVehCrdnatAzmth "IAPAVehCrdnatAzmth";
BA_ "LongName" SG_ 337 IAPAVehCrdnatAzmth "Advanced_Park_Assist_Vehicle_Coordinate_Azimuth";
BA_ "SysSignalName" SG_ 337 IAPAVehCrdnatAzmth "APAVehCrdnatAzmth";
BA_ "CompuMethodName" SG_ 337 IESSDirInd "ESSDirInd";
BA_ "GenSigStartValue" SG_ 337 IESSDirInd 2;
BA_ "ISignalName" SG_ 337 IESSDirInd "IESSDirInd";
BA_ "LongName" SG_ 337 IESSDirInd "Emergency_Steering_System _Direction_Indication";
BA_ "SysSignalName" SG_ 337 IESSDirInd "ESSDirInd";
BA_ "CompuMethodName" SG_ 337 IIPD_20ms_Group60_Reserved3 "IPD_20ms_Group60_Reserved3";
BA_ "GenSigStartValue" SG_ 337 IIPD_20ms_Group60_Reserved3 7;
BA_ "ISignalName" SG_ 337 IIPD_20ms_Group60_Reserved3 "IIPD_20ms_Group60_Reserved3";
BA_ "SysSignalName" SG_ 337 IIPD_20ms_Group60_Reserved3 "IPD_20ms_Group60_Reserved3";
BA_ "CompuMethodName" SG_ 337 IPilotTkovMsgReq "PilotTkovMsgReq";
BA_ "ISignalName" SG_ 337 IPilotTkovMsgReq "IPilotTkovMsgReq";
BA_ "LongName" SG_ 337 IPilotTkovMsgReq "Pilot Take Over Message Request";
BA_ "SysSignalName" SG_ 337 IPilotTkovMsgReq "PilotTkovMsgReq";
BA_ "CompuMethodName" SG_ 337 INOPSysSts_ZPD "NOPSysSts_ZPD";
BA_ "ISignalName" SG_ 337 INOPSysSts_ZPD "INOPSysSts_ZPD";
BA_ "LongName" SG_ 337 INOPSysSts_ZPD "Navigation On Pilot System Status";
BA_ "SysSignalName" SG_ 337 INOPSysSts_ZPD "NOPSysSts_ZPD";
BA_ "CompuMethodName" SG_ 337 IPrkgDstCtrlSwResp "PrkgDstCtrlSwResp";
BA_ "GenSigStartValue" SG_ 337 IPrkgDstCtrlSwResp 1;
BA_ "ISignalName" SG_ 337 IPrkgDstCtrlSwResp "IPrkgDstCtrlSwResp";
BA_ "LongName" SG_ 337 IPrkgDstCtrlSwResp "Parking Distance Ctrl Switch Response";
BA_ "SysSignalName" SG_ 337 IPrkgDstCtrlSwResp "PrkgDstCtrlSwResp";
BA_ "CompuMethodName" SG_ 337 IALCSysSts "ALCSysSts";
BA_ "ISignalName" SG_ 337 IALCSysSts "IALCSysSts";
BA_ "LongName" SG_ 337 IALCSysSts "Auto_Lane_Change_System_Status";
BA_ "SysSignalName" SG_ 337 IALCSysSts "ALCSysSts";
BA_ "CompuMethodName" SG_ 337 IALCSysFltSts "ALCSysFltSts";
BA_ "ISignalName" SG_ 337 IALCSysFltSts "IALCSysFltSts";
BA_ "LongName" SG_ 337 IALCSysFltSts "ALC System Failure Status";
BA_ "SysSignalName" SG_ 337 IALCSysFltSts "ALCSysFltSts";
BA_ "CompuMethodName" SG_ 337 IAPAVehCrdnatPosX "APAVehCrdnatPosX";
BA_ "ISignalName" SG_ 337 IAPAVehCrdnatPosX "IAPAVehCrdnatPosX";
BA_ "LongName" SG_ 337 IAPAVehCrdnatPosX "Advanced_Park_Assist_Vehicle_Coordinate_Position_X";
BA_ "SysSignalName" SG_ 337 IAPAVehCrdnatPosX "APAVehCrdnatPosX";
BA_ "CompuMethodName" SG_ 337 IAutoLaneChngLLaneSts "AutoLaneChngLLaneSts";
BA_ "ISignalName" SG_ 337 IAutoLaneChngLLaneSts "IAutoLaneChngLLaneSts";
BA_ "LongName" SG_ 337 IAutoLaneChngLLaneSts "Auto_Lane_Change_Left_Lane_Status";
BA_ "SysSignalName" SG_ 337 IAutoLaneChngLLaneSts "AutoLaneChngLLaneSts";
BA_ "CompuMethodName" SG_ 337 IIPD_20ms_Group60_Reserved4 "IPD_20ms_Group60_Reserved4";
BA_ "GenSigStartValue" SG_ 337 IIPD_20ms_Group60_Reserved4 3;
BA_ "ISignalName" SG_ 337 IIPD_20ms_Group60_Reserved4 "IIPD_20ms_Group60_Reserved4";
BA_ "SysSignalName" SG_ 337 IIPD_20ms_Group60_Reserved4 "IPD_20ms_Group60_Reserved4";
BA_ "CompuMethodName" SG_ 337 IESSSysSts "ESSSysSts";
BA_ "GenSigStartValue" SG_ 337 IESSSysSts 1;
BA_ "ISignalName" SG_ 337 IESSSysSts "IESSSysSts";
BA_ "LongName" SG_ 337 IESSSysSts "Emergency_Steering_System_Status";
BA_ "SysSignalName" SG_ 337 IESSSysSts "ESSSysSts";
BA_ "CompuMethodName" SG_ 337 IESSSysFltSts "ESSSysFltSts";
BA_ "ISignalName" SG_ 337 IESSSysFltSts "IESSSysFltSts";
BA_ "LongName" SG_ 337 IESSSysFltSts "Emergency_Steering_System_Fault_Status";
BA_ "SysSignalName" SG_ 337 IESSSysFltSts "ESSSysFltSts";
BA_ "CompuMethodName" SG_ 337 IIPD_20ms_Group60_Reserved5 "IPD_20ms_Group60_Reserved5";
BA_ "GenSigStartValue" SG_ 337 IIPD_20ms_Group60_Reserved5 1;
BA_ "ISignalName" SG_ 337 IIPD_20ms_Group60_Reserved5 "IIPD_20ms_Group60_Reserved5";
BA_ "SysSignalName" SG_ 337 IIPD_20ms_Group60_Reserved5 "IPD_20ms_Group60_Reserved5";
BA_ "CompuMethodName" SG_ 337 IESSDrvrTkovReq "ESSDrvrTkovReq";
BA_ "ISignalName" SG_ 337 IESSDrvrTkovReq "IESSDrvrTkovReq";
BA_ "LongName" SG_ 337 IESSDrvrTkovReq "Emergency_Steering_System_Takeover_Request";
BA_ "SysSignalName" SG_ 337 IESSDrvrTkovReq "ESSDrvrTkovReq";
BA_ "CompuMethodName" SG_ 337 ISLIFSysFltSts "SLIFSysFltSts";
BA_ "ISignalName" SG_ 337 ISLIFSysFltSts "ISLIFSysFltSts";
BA_ "LongName" SG_ 337 ISLIFSysFltSts "Speed_Limit_Information_Function_System_Fault_Status";
BA_ "SysSignalName" SG_ 337 ISLIFSysFltSts "SLIFSysFltSts";
BA_ "CompuMethodName" SG_ 337 IParkngslottype "Parkngslottype";
BA_ "ISignalName" SG_ 337 IParkngslottype "IParkngslottype";
BA_ "LongName" SG_ 337 IParkngslottype "Parking Slot Type";
BA_ "SysSignalName" SG_ 337 IParkngslottype "Parkngslottype";
BA_ "CompuMethodName" SG_ 337 IIPD_20ms_Group60_Reserved6 "IPD_20ms_Group60_Reserved6";
BA_ "GenSigStartValue" SG_ 337 IIPD_20ms_Group60_Reserved6 31;
BA_ "ISignalName" SG_ 337 IIPD_20ms_Group60_Reserved6 "IIPD_20ms_Group60_Reserved6";
BA_ "SysSignalName" SG_ 337 IIPD_20ms_Group60_Reserved6 "IPD_20ms_Group60_Reserved6";
BA_ "CompuMethodName" SG_ 337 INOPSysFltSts "NOPSysFltSts";
BA_ "ISignalName" SG_ 337 INOPSysFltSts "INOPSysFltSts";
BA_ "LongName" SG_ 337 INOPSysFltSts "Nop System Failure Status";
BA_ "SysSignalName" SG_ 337 INOPSysFltSts "NOPSysFltSts";
BA_ "CompuMethodName" SG_ 337 IIPD_20ms_Group60_Reserved7 "IPD_20ms_Group60_Reserved7";
BA_ "GenSigStartValue" SG_ 337 IIPD_20ms_Group60_Reserved7 255;
BA_ "ISignalName" SG_ 337 IIPD_20ms_Group60_Reserved7 "IIPD_20ms_Group60_Reserved7";
BA_ "SysSignalName" SG_ 337 IIPD_20ms_Group60_Reserved7 "IPD_20ms_Group60_Reserved7";
BA_ "CompuMethodName" SG_ 337 IIPD_20ms_Group60_Reserved8 "IPD_20ms_Group60_Reserved8";
BA_ "GenSigStartValue" SG_ 337 IIPD_20ms_Group60_Reserved8 255;
BA_ "ISignalName" SG_ 337 IIPD_20ms_Group60_Reserved8 "IIPD_20ms_Group60_Reserved8";
BA_ "SysSignalName" SG_ 337 IIPD_20ms_Group60_Reserved8 "IPD_20ms_Group60_Reserved8";
BA_ "CompuMethodName" SG_ 337 IIPD_20ms_Group60_Reserved9 "IPD_20ms_Group60_Reserved9";
BA_ "GenSigStartValue" SG_ 337 IIPD_20ms_Group60_Reserved9 255;
BA_ "ISignalName" SG_ 337 IIPD_20ms_Group60_Reserved9 "IIPD_20ms_Group60_Reserved9";
BA_ "SysSignalName" SG_ 337 IIPD_20ms_Group60_Reserved9 "IPD_20ms_Group60_Reserved9";
BA_ "CompuMethodName" SG_ 337 IIPD_20ms_Group60_Reserved10 "IPD_20ms_Group60_Reserved10";
BA_ "GenSigStartValue" SG_ 337 IIPD_20ms_Group60_Reserved10 255;
BA_ "ISignalName" SG_ 337 IIPD_20ms_Group60_Reserved10 "IIPD_20ms_Group60_Reserved10";
BA_ "SysSignalName" SG_ 337 IIPD_20ms_Group60_Reserved10 "IPD_20ms_Group60_Reserved10";
BA_ "CompuMethodName" SG_ 590 IRoadProfileShockDistL1 "RoadProfileShockDistL1";
BA_ "ISignalName" SG_ 590 IRoadProfileShockDistL1 "IRoadProfileShockDistL1";
BA_ "LongName" SG_ 590 IRoadProfileShockDistL1 "Distance To The Leading Edge Of The First Shock Feature Along The Rolling Path L";
BA_ "SysSignalName" SG_ 590 IRoadProfileShockDistL1 "RoadProfileShockDistL1";
BA_ "CompuMethodName" SG_ 590 IRoadProfileShockDistL2 "RoadProfileShockDistL2";
BA_ "ISignalName" SG_ 590 IRoadProfileShockDistL2 "IRoadProfileShockDistL2";
BA_ "LongName" SG_ 590 IRoadProfileShockDistL2 "Distance To The Leading Edge Of The Second Shock Feature Along The Rolling Path L";
BA_ "SysSignalName" SG_ 590 IRoadProfileShockDistL2 "RoadProfileShockDistL2";
BA_ "CompuMethodName" SG_ 590 IRoadProfileShockDetectedL1 "RoadProfileShockDetectedL1";
BA_ "ISignalName" SG_ 590 IRoadProfileShockDetectedL1 "IRoadProfileShockDetectedL1";
BA_ "LongName" SG_ 590 IRoadProfileShockDetectedL1 "An Indication That A Shock Feature Has Been Detected_L_1";
BA_ "SysSignalName" SG_ 590 IRoadProfileShockDetectedL1 "RoadProfileShockDetectedL1";
BA_ "CompuMethodName" SG_ 590 IRoadProfileShockDistL3 "RoadProfileShockDistL3";
BA_ "ISignalName" SG_ 590 IRoadProfileShockDistL3 "IRoadProfileShockDistL3";
BA_ "LongName" SG_ 590 IRoadProfileShockDistL3 "Distance To The Leading Edge Of The Third Shock Feature Along The Rolling Path L";
BA_ "SysSignalName" SG_ 590 IRoadProfileShockDistL3 "RoadProfileShockDistL3";
BA_ "CompuMethodName" SG_ 590 IRoadProfileShockDistR1 "RoadProfileShockDistR1";
BA_ "ISignalName" SG_ 590 IRoadProfileShockDistR1 "IRoadProfileShockDistR1";
BA_ "LongName" SG_ 590 IRoadProfileShockDistR1 "Distance To The Leading Edge Of The First Shock Feature Along The Rolling Path R";
BA_ "SysSignalName" SG_ 590 IRoadProfileShockDistR1 "RoadProfileShockDistR1";
BA_ "CompuMethodName" SG_ 590 IRoadProfileShockDetectedL2 "RoadProfileShockDetectedL2";
BA_ "ISignalName" SG_ 590 IRoadProfileShockDetectedL2 "IRoadProfileShockDetectedL2";
BA_ "LongName" SG_ 590 IRoadProfileShockDetectedL2 "An Indication That A Shock Feature Has Been Detected_L_2";
BA_ "SysSignalName" SG_ 590 IRoadProfileShockDetectedL2 "RoadProfileShockDetectedL2";
BA_ "CompuMethodName" SG_ 590 IRoadProfileShockDistR2 "RoadProfileShockDistR2";
BA_ "ISignalName" SG_ 590 IRoadProfileShockDistR2 "IRoadProfileShockDistR2";
BA_ "LongName" SG_ 590 IRoadProfileShockDistR2 "Distance To The Leading Edge Of The Second Shock Feature Along The Rolling Path R";
BA_ "SysSignalName" SG_ 590 IRoadProfileShockDistR2 "RoadProfileShockDistR2";
BA_ "CompuMethodName" SG_ 590 IRoadProfileShockDistR3 "RoadProfileShockDistR3";
BA_ "ISignalName" SG_ 590 IRoadProfileShockDistR3 "IRoadProfileShockDistR3";
BA_ "LongName" SG_ 590 IRoadProfileShockDistR3 "Distance To The Leading Edge Of The Third Shock Feature Along The Rolling Path R";
BA_ "SysSignalName" SG_ 590 IRoadProfileShockDistR3 "RoadProfileShockDistR3";
BA_ "CompuMethodName" SG_ 590 IRoadProfileShockDetectedL3 "RoadProfileShockDetectedL3";
BA_ "ISignalName" SG_ 590 IRoadProfileShockDetectedL3 "IRoadProfileShockDetectedL3";
BA_ "LongName" SG_ 590 IRoadProfileShockDetectedL3 "An Indication That A Shock Feature Has Been Detected_L_3";
BA_ "SysSignalName" SG_ 590 IRoadProfileShockDetectedL3 "RoadProfileShockDetectedL3";
BA_ "CompuMethodName" SG_ 590 IRoadProfileShockHeightL1 "RoadProfileShockHeightL1";
BA_ "ISignalName" SG_ 590 IRoadProfileShockHeightL1 "IRoadProfileShockHeightL1";
BA_ "LongName" SG_ 590 IRoadProfileShockHeightL1 "The Height Of The Shock Feature_L_1";
BA_ "SysSignalName" SG_ 590 IRoadProfileShockHeightL1 "RoadProfileShockHeightL1";
BA_ "CompuMethodName" SG_ 590 IRoadProfileShockConfidenceL1 "RoadProfileShockConfidenceL1";
BA_ "ISignalName" SG_ 590 IRoadProfileShockConfidenceL1 "IRoadProfileShockConfidenceL1";
BA_ "LongName" SG_ 590 IRoadProfileShockConfidenceL1 "The Confidence Of The Shock Detection_L_1";
BA_ "SysSignalName" SG_ 590 IRoadProfileShockConfidenceL1 "RoadProfileShockConfidenceL1";
BA_ "CompuMethodName" SG_ 590 IRoadProfileShockHeightL2 "RoadProfileShockHeightL2";
BA_ "ISignalName" SG_ 590 IRoadProfileShockHeightL2 "IRoadProfileShockHeightL2";
BA_ "LongName" SG_ 590 IRoadProfileShockHeightL2 "The Height Of The Shock Feature_L_2";
BA_ "SysSignalName" SG_ 590 IRoadProfileShockHeightL2 "RoadProfileShockHeightL2";
BA_ "CompuMethodName" SG_ 590 IRoadProfileShockConfidenceL2 "RoadProfileShockConfidenceL2";
BA_ "ISignalName" SG_ 590 IRoadProfileShockConfidenceL2 "IRoadProfileShockConfidenceL2";
BA_ "LongName" SG_ 590 IRoadProfileShockConfidenceL2 "The Confidence Of The Shock Detection_L_2";
BA_ "SysSignalName" SG_ 590 IRoadProfileShockConfidenceL2 "RoadProfileShockConfidenceL2";
BA_ "CompuMethodName" SG_ 590 IRoadProfileShockHeightL3 "RoadProfileShockHeightL3";
BA_ "ISignalName" SG_ 590 IRoadProfileShockHeightL3 "IRoadProfileShockHeightL3";
BA_ "LongName" SG_ 590 IRoadProfileShockHeightL3 "The Height Of The Shock Feature_L_3";
BA_ "SysSignalName" SG_ 590 IRoadProfileShockHeightL3 "RoadProfileShockHeightL3";
BA_ "CompuMethodName" SG_ 590 IRoadProfileShockConfidenceL3 "RoadProfileShockConfidenceL3";
BA_ "ISignalName" SG_ 590 IRoadProfileShockConfidenceL3 "IRoadProfileShockConfidenceL3";
BA_ "LongName" SG_ 590 IRoadProfileShockConfidenceL3 "The Confidence Of The Shock Detection_L_3";
BA_ "SysSignalName" SG_ 590 IRoadProfileShockConfidenceL3 "RoadProfileShockConfidenceL3";
BA_ "CompuMethodName" SG_ 590 IRoadProfileShockHeightR1 "RoadProfileShockHeightR1";
BA_ "ISignalName" SG_ 590 IRoadProfileShockHeightR1 "IRoadProfileShockHeightR1";
BA_ "LongName" SG_ 590 IRoadProfileShockHeightR1 "The Height Of The Shock Feature_R_1";
BA_ "SysSignalName" SG_ 590 IRoadProfileShockHeightR1 "RoadProfileShockHeightR1";
BA_ "CompuMethodName" SG_ 590 IRoadProfileShockConfidenceR1 "RoadProfileShockConfidenceR1";
BA_ "ISignalName" SG_ 590 IRoadProfileShockConfidenceR1 "IRoadProfileShockConfidenceR1";
BA_ "LongName" SG_ 590 IRoadProfileShockConfidenceR1 "The Confidence Of The Shock Detection_R_1";
BA_ "SysSignalName" SG_ 590 IRoadProfileShockConfidenceR1 "RoadProfileShockConfidenceR1";
BA_ "CompuMethodName" SG_ 590 IRoadProfileShockHeightR2 "RoadProfileShockHeightR2";
BA_ "ISignalName" SG_ 590 IRoadProfileShockHeightR2 "IRoadProfileShockHeightR2";
BA_ "LongName" SG_ 590 IRoadProfileShockHeightR2 "The Height Of The Shock Feature_R_2";
BA_ "SysSignalName" SG_ 590 IRoadProfileShockHeightR2 "RoadProfileShockHeightR2";
BA_ "CompuMethodName" SG_ 590 IRoadProfileShockConfidenceR2 "RoadProfileShockConfidenceR2";
BA_ "ISignalName" SG_ 590 IRoadProfileShockConfidenceR2 "IRoadProfileShockConfidenceR2";
BA_ "LongName" SG_ 590 IRoadProfileShockConfidenceR2 "The Confidence Of The Shock Detection_R_2";
BA_ "SysSignalName" SG_ 590 IRoadProfileShockConfidenceR2 "RoadProfileShockConfidenceR2";
BA_ "CompuMethodName" SG_ 590 IRoadProfileShockHeightR3 "RoadProfileShockHeightR3";
BA_ "ISignalName" SG_ 590 IRoadProfileShockHeightR3 "IRoadProfileShockHeightR3";
BA_ "LongName" SG_ 590 IRoadProfileShockHeightR3 "The Height Of The Shock Feature_R_3";
BA_ "SysSignalName" SG_ 590 IRoadProfileShockHeightR3 "RoadProfileShockHeightR3";
BA_ "CompuMethodName" SG_ 590 IRoadProfileShockConfidenceR3 "RoadProfileShockConfidenceR3";
BA_ "ISignalName" SG_ 590 IRoadProfileShockConfidenceR3 "IRoadProfileShockConfidenceR3";
BA_ "LongName" SG_ 590 IRoadProfileShockConfidenceR3 "The Confidence Of The Shock Detection_R_3";
BA_ "SysSignalName" SG_ 590 IRoadProfileShockConfidenceR3 "RoadProfileShockConfidenceR3";
BA_ "CompuMethodName" SG_ 590 IRoadHeightL "RoadHeightL";
BA_ "ISignalName" SG_ 590 IRoadHeightL "IRoadHeightL";
BA_ "LongName" SG_ 590 IRoadHeightL "The Height Of road Feature L";
BA_ "SysSignalName" SG_ 590 IRoadHeightL "RoadHeightL";
BA_ "CompuMethodName" SG_ 590 IPrvOutSts "PrvOutSts";
BA_ "ISignalName" SG_ 590 IPrvOutSts "IPrvOutSts";
BA_ "LongName" SG_ 590 IPrvOutSts "Preview_Output_status";
BA_ "SysSignalName" SG_ 590 IPrvOutSts "PrvOutSts";
BA_ "CompuMethodName" SG_ 590 IRoadProfileShockDetectedR1 "RoadProfileShockDetectedR1";
BA_ "ISignalName" SG_ 590 IRoadProfileShockDetectedR1 "IRoadProfileShockDetectedR1";
BA_ "LongName" SG_ 590 IRoadProfileShockDetectedR1 "An Indication That A Shock Feature Has Been Detected_R_1";
BA_ "SysSignalName" SG_ 590 IRoadProfileShockDetectedR1 "RoadProfileShockDetectedR1";
BA_ "CompuMethodName" SG_ 590 IRoadHeightR "RoadHeightR";
BA_ "ISignalName" SG_ 590 IRoadHeightR "IRoadHeightR";
BA_ "LongName" SG_ 590 IRoadHeightR "The Height Of road Feature R";
BA_ "SysSignalName" SG_ 590 IRoadHeightR "RoadHeightR";
BA_ "CompuMethodName" SG_ 590 IRoadProfileShockDetectedR3 "RoadProfileShockDetectedR3";
BA_ "ISignalName" SG_ 590 IRoadProfileShockDetectedR3 "IRoadProfileShockDetectedR3";
BA_ "LongName" SG_ 590 IRoadProfileShockDetectedR3 "An Indication That A Shock Feature Has Been Detected_R_3";
BA_ "SysSignalName" SG_ 590 IRoadProfileShockDetectedR3 "RoadProfileShockDetectedR3";
BA_ "CompuMethodName" SG_ 590 IRoadProfileShockDetectedR2 "RoadProfileShockDetectedR2";
BA_ "ISignalName" SG_ 590 IRoadProfileShockDetectedR2 "IRoadProfileShockDetectedR2";
BA_ "LongName" SG_ 590 IRoadProfileShockDetectedR2 "An Indication That A Shock Feature Has Been Detected_R_2";
BA_ "SysSignalName" SG_ 590 IRoadProfileShockDetectedR2 "RoadProfileShockDetectedR2";
BA_ "CompuMethodName" SG_ 1202 IIPD_NM_BSMtoRMS_CHCANFD "IPD_NM_BSMtoRMS_CHCANFD";
BA_ "ISignalName" SG_ 1202 IIPD_NM_BSMtoRMS_CHCANFD "IIPD_NM_BSMtoRMS_CHCANFD";
BA_ "LongName" SG_ 1202 IIPD_NM_BSMtoRMS_CHCANFD "IPD_NM_BSMtoRMS_CHCANFD";
BA_ "SysSignalName" SG_ 1202 IIPD_NM_BSMtoRMS_CHCANFD "IPD_NM_BSMtoRMS_CHCANFD";
BA_ "CompuMethodName" SG_ 1202 IIPD_NM_PBSMtoRMS_CHCANFD "IPD_NM_PBSMtoRMS_CHCANFD";
BA_ "ISignalName" SG_ 1202 IIPD_NM_PBSMtoRMS_CHCANFD "IIPD_NM_PBSMtoRMS_CHCANFD";
BA_ "LongName" SG_ 1202 IIPD_NM_PBSMtoRMS_CHCANFD "IPD_NM_PBSMtoRMS_CHCANFD";
BA_ "SysSignalName" SG_ 1202 IIPD_NM_PBSMtoRMS_CHCANFD "IPD_NM_PBSMtoRMS_CHCANFD";
BA_ "CompuMethodName" SG_ 1202 IIPD_NM_RMStoNOS_CHCANFD "IPD_NM_RMStoNOS_CHCANFD";
BA_ "ISignalName" SG_ 1202 IIPD_NM_RMStoNOS_CHCANFD "IIPD_NM_RMStoNOS_CHCANFD";
BA_ "LongName" SG_ 1202 IIPD_NM_RMStoNOS_CHCANFD "IPD_NM_RMStoNOS_CHCANFD";
BA_ "SysSignalName" SG_ 1202 IIPD_NM_RMStoNOS_CHCANFD "IPD_NM_RMStoNOS_CHCANFD";
BA_ "CompuMethodName" SG_ 1202 IIPD_NM_RSStoNOS_CHCANFD "IPD_NM_RSStoNOS_CHCANFD";
BA_ "ISignalName" SG_ 1202 IIPD_NM_RSStoNOS_CHCANFD "IIPD_NM_RSStoNOS_CHCANFD";
BA_ "LongName" SG_ 1202 IIPD_NM_RSStoNOS_CHCANFD "IPD_NM_RSStoNOS_CHCANFD";
BA_ "SysSignalName" SG_ 1202 IIPD_NM_RSStoNOS_CHCANFD "IPD_NM_RSStoNOS_CHCANFD";
BA_ "CompuMethodName" SG_ 1202 IIPD_NM_RSStoRMS_CHCANFD "IPD_NM_RSStoRMS_CHCANFD";
BA_ "ISignalName" SG_ 1202 IIPD_NM_RSStoRMS_CHCANFD "IIPD_NM_RSStoRMS_CHCANFD";
BA_ "LongName" SG_ 1202 IIPD_NM_RSStoRMS_CHCANFD "IPD_NM_RSStoRMS_CHCANFD";
BA_ "SysSignalName" SG_ 1202 IIPD_NM_RSStoRMS_CHCANFD "IPD_NM_RSStoRMS_CHCANFD";
BA_ "CompuMethodName" SG_ 1202 IIPD_NM_NOStoRMS_CHCANFD "IPD_NM_NOStoRMS_CHCANFD";
BA_ "ISignalName" SG_ 1202 IIPD_NM_NOStoRMS_CHCANFD "IIPD_NM_NOStoRMS_CHCANFD";
BA_ "LongName" SG_ 1202 IIPD_NM_NOStoRMS_CHCANFD "IPD_NM_NOStoRMS_CHCANFD";
BA_ "SysSignalName" SG_ 1202 IIPD_NM_NOStoRMS_CHCANFD "IPD_NM_NOStoRMS_CHCANFD";
BA_ "CompuMethodName" SG_ 1202 IIPD_NM_NOSSta_CHCANFD "IPD_NM_NOSSta_CHCANFD";
BA_ "ISignalName" SG_ 1202 IIPD_NM_NOSSta_CHCANFD "IIPD_NM_NOSSta_CHCANFD";
BA_ "LongName" SG_ 1202 IIPD_NM_NOSSta_CHCANFD "IPD_NM_NOSSta_CHCANFD";
BA_ "SysSignalName" SG_ 1202 IIPD_NM_NOSSta_CHCANFD "IPD_NM_NOSSta_CHCANFD";
BA_ "CompuMethodName" SG_ 1202 IIPD_NM_RMSSta_CHCANFD "IPD_NM_RMSSta_CHCANFD";
BA_ "ISignalName" SG_ 1202 IIPD_NM_RMSSta_CHCANFD "IIPD_NM_RMSSta_CHCANFD";
BA_ "LongName" SG_ 1202 IIPD_NM_RMSSta_CHCANFD "IPD_NM_RMSSta_CHCANFD";
BA_ "SysSignalName" SG_ 1202 IIPD_NM_RMSSta_CHCANFD "IPD_NM_RMSSta_CHCANFD";
BA_ "CompuMethodName" SG_ 1202 IIPD_NWI_CHCANFD "IPD_NWI_CHCANFD";
BA_ "ISignalName" SG_ 1202 IIPD_NWI_CHCANFD "IIPD_NWI_CHCANFD";
BA_ "LongName" SG_ 1202 IIPD_NWI_CHCANFD "IPD CHCANFD Network_Wakeup_Indication";
BA_ "SysSignalName" SG_ 1202 IIPD_NWI_CHCANFD "IPD_NWI_CHCANFD";
BA_ "CompuMethodName" SG_ 1202 IIPD_NOI_CHCANFD "IPD_NOI_CHCANFD";
BA_ "ISignalName" SG_ 1202 IIPD_NOI_CHCANFD "IIPD_NOI_CHCANFD";
BA_ "LongName" SG_ 1202 IIPD_NOI_CHCANFD "IPD CHCANFD Network Operation Indication";
BA_ "SysSignalName" SG_ 1202 IIPD_NOI_CHCANFD "IPD_NOI_CHCANFD";
BA_ "CompuMethodName" SG_ 1202 IIPD_NKI_CHCANFD "IPD_NKI_CHCANFD";
BA_ "ISignalName" SG_ 1202 IIPD_NKI_CHCANFD "IIPD_NKI_CHCANFD";
BA_ "LongName" SG_ 1202 IIPD_NKI_CHCANFD "IPD CHCANFD Network Keep Indication";
BA_ "SysSignalName" SG_ 1202 IIPD_NKI_CHCANFD "IPD_NKI_CHCANFD";
BA_ "CompuMethodName" SG_ 157 ILHZCU_10ms_Group01_CRC "LHZCU_10ms_Group01_CRC";
BA_ "ISignalName" SG_ 157 ILHZCU_10ms_Group01_CRC "ILHZCU_10ms_Group01_CRC";
BA_ "SysSignalName" SG_ 157 ILHZCU_10ms_Group01_CRC "LHZCU_10ms_Group01_CRC";
BA_ "CompuMethodName" SG_ 157 ILHZCU_10ms_Group01_RC "LHZCU_10ms_Group01_RC";
BA_ "ISignalName" SG_ 157 ILHZCU_10ms_Group01_RC "ILHZCU_10ms_Group01_RC";
BA_ "SysSignalName" SG_ 157 ILHZCU_10ms_Group01_RC "LHZCU_10ms_Group01_RC";
BA_ "CompuMethodName" SG_ 157 ISCUFltLvlWarn "SCUFltLvlWarn";
BA_ "ISignalName" SG_ 157 ISCUFltLvlWarn "ISCUFltLvlWarn";
BA_ "LongName" SG_ 157 ISCUFltLvlWarn "Shifter Control Unit Fault Level Warning";
BA_ "SysSignalName" SG_ 157 ISCUFltLvlWarn "SCUFltLvlWarn";
BA_ "CompuMethodName" SG_ 157 ISCUDrvMd "SCUDrvMd";
BA_ "ISignalName" SG_ 157 ISCUDrvMd "ISCUDrvMd";
BA_ "LongName" SG_ 157 ISCUDrvMd "Shifter Control Unit Drive Mode";
BA_ "SysSignalName" SG_ 157 ISCUDrvMd "SCUDrvMd";
BA_ "CompuMethodName" SG_ 157 ISCUExtdShiftrFlr "SCUExtdShiftrFlr";
BA_ "ISignalName" SG_ 157 ISCUExtdShiftrFlr "ISCUExtdShiftrFlr";
BA_ "LongName" SG_ 157 ISCUExtdShiftrFlr "Shifter Control Unit Extended Shifter Failure";
BA_ "SysSignalName" SG_ 157 ISCUExtdShiftrFlr "SCUExtdShiftrFlr";
BA_ "CompuMethodName" SG_ 157 ISCUShiftrOpngRmndr "SCUShiftrOpngRmndr";
BA_ "ISignalName" SG_ 157 ISCUShiftrOpngRmndr "ISCUShiftrOpngRmndr";
BA_ "LongName" SG_ 157 ISCUShiftrOpngRmndr "Shifter Control Unit Shifter Operating Reminder";
BA_ "SysSignalName" SG_ 157 ISCUShiftrOpngRmndr "SCUShiftrOpngRmndr";
BA_ "CompuMethodName" SG_ 157 IKeyAuthResp "KeyAuthResp";
BA_ "ISignalName" SG_ 157 IKeyAuthResp "IKeyAuthResp";
BA_ "LongName" SG_ 157 IKeyAuthResp "Key Authentication Response";
BA_ "SysSignalName" SG_ 157 IKeyAuthResp "KeyAuthResp";
BA_ "CompuMethodName" SG_ 157 ISCUParkLckReq "SCUParkLckReq";
BA_ "ISignalName" SG_ 157 ISCUParkLckReq "ISCUParkLckReq";
BA_ "LongName" SG_ 157 ISCUParkLckReq "Shifter Control Unit Park Lock Request";
BA_ "SysSignalName" SG_ 157 ISCUParkLckReq "SCUParkLckReq";
BA_ "CompuMethodName" SG_ 157 ISCUParkLckReqV "SCUParkLckReqV";
BA_ "GenSigStartValue" SG_ 157 ISCUParkLckReqV 1;
BA_ "ISignalName" SG_ 157 ISCUParkLckReqV "ISCUParkLckReqV";
BA_ "LongName" SG_ 157 ISCUParkLckReqV "Shifter Control Unit Park Lock Request Validity";
BA_ "SysSignalName" SG_ 157 ISCUParkLckReqV "SCUParkLckReqV";
BA_ "CompuMethodName" SG_ 157 ILHZCU_10ms_Group01_Reserved1 "LHZCU_10ms_Group01_Reserved1";
BA_ "GenSigStartValue" SG_ 157 ILHZCU_10ms_Group01_Reserved1 7;
BA_ "ISignalName" SG_ 157 ILHZCU_10ms_Group01_Reserved1 "ILHZCU_10ms_Group01_Reserved1";
BA_ "SysSignalName" SG_ 157 ILHZCU_10ms_Group01_Reserved1 "LHZCU_10ms_Group01_Reserved1";
BA_ "CompuMethodName" SG_ 157 IDigKeyAuthReq "DigKeyAuthReq";
BA_ "ISignalName" SG_ 157 IDigKeyAuthReq "IDigKeyAuthReq";
BA_ "LongName" SG_ 157 IDigKeyAuthReq "Digtial Key Authentication  Request";
BA_ "SysSignalName" SG_ 157 IDigKeyAuthReq "DigKeyAuthReq";
BA_ "CompuMethodName" SG_ 157 ISCUShiftrLvrRawPosn "SCUShiftrLvrRawPosn";
BA_ "GenSigStartValue" SG_ 157 ISCUShiftrLvrRawPosn 2;
BA_ "ISignalName" SG_ 157 ISCUShiftrLvrRawPosn "ISCUShiftrLvrRawPosn";
BA_ "LongName" SG_ 157 ISCUShiftrLvrRawPosn "Shifter Control Unit Shifter Lever Raw Position";
BA_ "SysSignalName" SG_ 157 ISCUShiftrLvrRawPosn "SCUShiftrLvrRawPosn";
BA_ "CompuMethodName" SG_ 157 ISCUParkLckReqVEPMCU "SCUParkLckReqVEPMCU";
BA_ "GenSigStartValue" SG_ 157 ISCUParkLckReqVEPMCU 1;
BA_ "ISignalName" SG_ 157 ISCUParkLckReqVEPMCU "ISCUParkLckReqVEPMCU";
BA_ "LongName" SG_ 157 ISCUParkLckReqVEPMCU "Shifter Control Unit Park Lock Request Validity Electrical Parking Motor Control Unit";
BA_ "SysSignalName" SG_ 157 ISCUParkLckReqVEPMCU "SCUParkLckReqVEPMCU";
BA_ "CompuMethodName" SG_ 157 IScurtKeyInvd "ScurtKeyInvd";
BA_ "GenSigStartValue" SG_ 157 IScurtKeyInvd 1;
BA_ "ISignalName" SG_ 157 IScurtKeyInvd "IScurtKeyInvd";
BA_ "LongName" SG_ 157 IScurtKeyInvd "Security Key Invalid";
BA_ "SysSignalName" SG_ 157 IScurtKeyInvd "ScurtKeyInvd";
BA_ "CompuMethodName" SG_ 157 ILHZCU_10ms_Group01_Reserved2 "LHZCU_10ms_Group01_Reserved2";
BA_ "GenSigStartValue" SG_ 157 ILHZCU_10ms_Group01_Reserved2 1;
BA_ "ISignalName" SG_ 157 ILHZCU_10ms_Group01_Reserved2 "ILHZCU_10ms_Group01_Reserved2";
BA_ "SysSignalName" SG_ 157 ILHZCU_10ms_Group01_Reserved2 "LHZCU_10ms_Group01_Reserved2";
BA_ "CompuMethodName" SG_ 157 ISCUParkLckReqEPMCU "SCUParkLckReqEPMCU";
BA_ "ISignalName" SG_ 157 ISCUParkLckReqEPMCU "ISCUParkLckReqEPMCU";
BA_ "LongName" SG_ 157 ISCUParkLckReqEPMCU "Shifter Control Unit Park Lock Request Electrical Parking Motor Control Unit";
BA_ "SysSignalName" SG_ 157 ISCUParkLckReqEPMCU "SCUParkLckReqEPMCU";
BA_ "CompuMethodName" SG_ 157 ISCUShiftrPosnInvsn "SCUShiftrPosnInvsn";
BA_ "GenSigStartValue" SG_ 157 ISCUShiftrPosnInvsn 15;
BA_ "ISignalName" SG_ 157 ISCUShiftrPosnInvsn "ISCUShiftrPosnInvsn";
BA_ "LongName" SG_ 157 ISCUShiftrPosnInvsn "Shifter Control Unit Shifter Position Inversion";
BA_ "SysSignalName" SG_ 157 ISCUShiftrPosnInvsn "SCUShiftrPosnInvsn";
BA_ "CompuMethodName" SG_ 157 ISCUShiftrLvrPosn "SCUShiftrLvrPosn";
BA_ "ISignalName" SG_ 157 ISCUShiftrLvrPosn "ISCUShiftrLvrPosn";
BA_ "LongName" SG_ 157 ISCUShiftrLvrPosn "Shifter Control Unit Shifter Lever Position";
BA_ "SysSignalName" SG_ 157 ISCUShiftrLvrPosn "SCUShiftrLvrPosn";
BA_ "CompuMethodName" SG_ 157 IDrvrReqParkBtn "DrvrReqParkBtn";
BA_ "ISignalName" SG_ 157 IDrvrReqParkBtn "IDrvrReqParkBtn";
BA_ "LongName" SG_ 157 IDrvrReqParkBtn "Driver Request Park Button";
BA_ "SysSignalName" SG_ 157 IDrvrReqParkBtn "DrvrReqParkBtn";
BA_ "CompuMethodName" SG_ 157 ISCUShiftrLvrPosnLtchActv "SCUShiftrLvrPosnLtchActv";
BA_ "ISignalName" SG_ 157 ISCUShiftrLvrPosnLtchActv "ISCUShiftrLvrPosnLtchActv";
BA_ "LongName" SG_ 157 ISCUShiftrLvrPosnLtchActv "Shifter Control Unit Shifter Lever Position Latch Active";
BA_ "SysSignalName" SG_ 157 ISCUShiftrLvrPosnLtchActv "SCUShiftrLvrPosnLtchActv";
BA_ "CompuMethodName" SG_ 157 ISecuKeyVldSts "SecuKeyVldSts";
BA_ "GenSigStartValue" SG_ 157 ISecuKeyVldSts 1;
BA_ "ISignalName" SG_ 157 ISecuKeyVldSts "ISecuKeyVldSts";
BA_ "LongName" SG_ 157 ISecuKeyVldSts "Security Key Valid Status";
BA_ "SysSignalName" SG_ 157 ISecuKeyVldSts "SecuKeyVldSts";
BA_ "CompuMethodName" SG_ 157 ISCUDrvrIntrvnActv "SCUDrvrIntrvnActv";
BA_ "ISignalName" SG_ 157 ISCUDrvrIntrvnActv "ISCUDrvrIntrvnActv";
BA_ "LongName" SG_ 157 ISCUDrvrIntrvnActv "Shifter Control Unit Driver Intervention Active";
BA_ "SysSignalName" SG_ 157 ISCUDrvrIntrvnActv "SCUDrvrIntrvnActv";
BA_ "CompuMethodName" SG_ 157 ISCUAPAUnderCtrlActv "SCUAPAUnderCtrlActv";
BA_ "ISignalName" SG_ 157 ISCUAPAUnderCtrlActv "ISCUAPAUnderCtrlActv";
BA_ "LongName" SG_ 157 ISCUAPAUnderCtrlActv "Shifter Control Unit Auto Parking Assist Under Control Active";
BA_ "SysSignalName" SG_ 157 ISCUAPAUnderCtrlActv "SCUAPAUnderCtrlActv";
BA_ "CompuMethodName" SG_ 157 IDigKeyPEValidReq "DigKeyPEValidReq";
BA_ "ISignalName" SG_ 157 IDigKeyPEValidReq "IDigKeyPEValidReq";
BA_ "LongName" SG_ 157 IDigKeyPEValidReq "Digital Key  Passive enter Valid  Request";
BA_ "SysSignalName" SG_ 157 IDigKeyPEValidReq "DigKeyPEValidReq";
BA_ "CompuMethodName" SG_ 546 ILHZCU_50ms_Group07_CRC "LHZCU_50ms_Group07_CRC";
BA_ "ISignalName" SG_ 546 ILHZCU_50ms_Group07_CRC "ILHZCU_50ms_Group07_CRC";
BA_ "SysSignalName" SG_ 546 ILHZCU_50ms_Group07_CRC "LHZCU_50ms_Group07_CRC";
BA_ "CompuMethodName" SG_ 546 ILHZCU_50ms_Group07_RC "LHZCU_50ms_Group07_RC";
BA_ "ISignalName" SG_ 546 ILHZCU_50ms_Group07_RC "ILHZCU_50ms_Group07_RC";
BA_ "SysSignalName" SG_ 546 ILHZCU_50ms_Group07_RC "LHZCU_50ms_Group07_RC";
BA_ "CompuMethodName" SG_ 546 ILHZCU_50ms_Group07_Reserved1 "LHZCU_50ms_Group07_Reserved1";
BA_ "GenSigStartValue" SG_ 546 ILHZCU_50ms_Group07_Reserved1 15;
BA_ "ISignalName" SG_ 546 ILHZCU_50ms_Group07_Reserved1 "ILHZCU_50ms_Group07_Reserved1";
BA_ "SysSignalName" SG_ 546 ILHZCU_50ms_Group07_Reserved1 "LHZCU_50ms_Group07_Reserved1";
BA_ "CompuMethodName" SG_ 546 IHODTchZone3Val "HODTchZone3Val";
BA_ "ISignalName" SG_ 546 IHODTchZone3Val "IHODTchZone3Val";
BA_ "LongName" SG_ 546 IHODTchZone3Val "Hands_Off_Detection_Touch_Zone_3_Value";
BA_ "SysSignalName" SG_ 546 IHODTchZone3Val "HODTchZone3Val";
BA_ "CompuMethodName" SG_ 546 IHODTchZone1Val "HODTchZone1Val";
BA_ "ISignalName" SG_ 546 IHODTchZone1Val "IHODTchZone1Val";
BA_ "LongName" SG_ 546 IHODTchZone1Val "Hands_Off_Detection_Touch_Zone_1_Value";
BA_ "SysSignalName" SG_ 546 IHODTchZone1Val "HODTchZone1Val";
BA_ "CompuMethodName" SG_ 546 IHODdiagSts "HODdiagSts";
BA_ "ISignalName" SG_ 546 IHODdiagSts "IHODdiagSts";
BA_ "LongName" SG_ 546 IHODdiagSts "Hands_Off_Detection_Diagnose_Status";
BA_ "SysSignalName" SG_ 546 IHODdiagSts "HODdiagSts";
BA_ "CompuMethodName" SG_ 546 ILHZCU_50ms_Group07_Reserved2 "LHZCU_50ms_Group07_Reserved2";
BA_ "GenSigStartValue" SG_ 546 ILHZCU_50ms_Group07_Reserved2 15;
BA_ "ISignalName" SG_ 546 ILHZCU_50ms_Group07_Reserved2 "ILHZCU_50ms_Group07_Reserved2";
BA_ "SysSignalName" SG_ 546 ILHZCU_50ms_Group07_Reserved2 "LHZCU_50ms_Group07_Reserved2";
BA_ "CompuMethodName" SG_ 546 IHODDetnSts "HODDetnSts";
BA_ "GenSigStartValue" SG_ 546 IHODDetnSts 2;
BA_ "ISignalName" SG_ 546 IHODDetnSts "IHODDetnSts";
BA_ "LongName" SG_ 546 IHODDetnSts "Hands_Off_Detection_Detection_Status";
BA_ "SysSignalName" SG_ 546 IHODDetnSts "HODDetnSts";
BA_ "CompuMethodName" SG_ 546 IHODTchZone1Sts "HODTchZone1Sts";
BA_ "ISignalName" SG_ 546 IHODTchZone1Sts "IHODTchZone1Sts";
BA_ "LongName" SG_ 546 IHODTchZone1Sts "Hands_Off_Detection_Touch_Zone_1_Status";
BA_ "SysSignalName" SG_ 546 IHODTchZone1Sts "HODTchZone1Sts";
BA_ "CompuMethodName" SG_ 546 IHODSysSts "HODSysSts";
BA_ "ISignalName" SG_ 546 IHODSysSts "IHODSysSts";
BA_ "LongName" SG_ 546 IHODSysSts "Hands_Off_Detection_System_Status";
BA_ "SysSignalName" SG_ 546 IHODSysSts "HODSysSts";
BA_ "CompuMethodName" SG_ 546 IHODTchZone3Sts "HODTchZone3Sts";
BA_ "ISignalName" SG_ 546 IHODTchZone3Sts "IHODTchZone3Sts";
BA_ "LongName" SG_ 546 IHODTchZone3Sts "Hands_Off_Detection_Touch_Zone_3_Status";
BA_ "SysSignalName" SG_ 546 IHODTchZone3Sts "HODTchZone3Sts";
BA_ "CompuMethodName" SG_ 546 IHODTchZone2Sts "HODTchZone2Sts";
BA_ "ISignalName" SG_ 546 IHODTchZone2Sts "IHODTchZone2Sts";
BA_ "LongName" SG_ 546 IHODTchZone2Sts "Hands_Off_Detection_Touch_Zone_2_Status";
BA_ "SysSignalName" SG_ 546 IHODTchZone2Sts "HODTchZone2Sts";
BA_ "CompuMethodName" SG_ 546 IHODTchZone2Val "HODTchZone2Val";
BA_ "ISignalName" SG_ 546 IHODTchZone2Val "IHODTchZone2Val";
BA_ "LongName" SG_ 546 IHODTchZone2Val "Hands_Off_Detection_Touch_Zone_2_Value";
BA_ "SysSignalName" SG_ 546 IHODTchZone2Val "HODTchZone2Val";
BA_ "CompuMethodName" SG_ 546 ILHZCU_50ms_Group07_Reserved3 "LHZCU_50ms_Group07_Reserved3";
BA_ "GenSigStartValue" SG_ 546 ILHZCU_50ms_Group07_Reserved3 255;
BA_ "ISignalName" SG_ 546 ILHZCU_50ms_Group07_Reserved3 "ILHZCU_50ms_Group07_Reserved3";
BA_ "SysSignalName" SG_ 546 ILHZCU_50ms_Group07_Reserved3 "LHZCU_50ms_Group07_Reserved3";
BA_ "CompuMethodName" SG_ 546 ILHZCU_50ms_Group07_Reserved4 "LHZCU_50ms_Group07_Reserved4";
BA_ "GenSigStartValue" SG_ 546 ILHZCU_50ms_Group07_Reserved4 255;
BA_ "ISignalName" SG_ 546 ILHZCU_50ms_Group07_Reserved4 "ILHZCU_50ms_Group07_Reserved4";
BA_ "SysSignalName" SG_ 546 ILHZCU_50ms_Group07_Reserved4 "LHZCU_50ms_Group07_Reserved4";
BA_ "CompuMethodName" SG_ 546 ILHZCU_50ms_Group07_Reserved5 "LHZCU_50ms_Group07_Reserved5";
BA_ "GenSigStartValue" SG_ 546 ILHZCU_50ms_Group07_Reserved5 255;
BA_ "ISignalName" SG_ 546 ILHZCU_50ms_Group07_Reserved5 "ILHZCU_50ms_Group07_Reserved5";
BA_ "SysSignalName" SG_ 546 ILHZCU_50ms_Group07_Reserved5 "LHZCU_50ms_Group07_Reserved5";
BA_ "CompuMethodName" SG_ 546 ILHZCU_50ms_Group07_Reserved6 "LHZCU_50ms_Group07_Reserved6";
BA_ "GenSigStartValue" SG_ 546 ILHZCU_50ms_Group07_Reserved6 255;
BA_ "ISignalName" SG_ 546 ILHZCU_50ms_Group07_Reserved6 "ILHZCU_50ms_Group07_Reserved6";
BA_ "SysSignalName" SG_ 546 ILHZCU_50ms_Group07_Reserved6 "LHZCU_50ms_Group07_Reserved6";
BA_ "CompuMethodName" SG_ 1267 IRZCU_NM_BSMtoRMS_CHCANFD "RZCU_NM_BSMtoRMS_CHCANFD";
BA_ "ISignalName" SG_ 1267 IRZCU_NM_BSMtoRMS_CHCANFD "IRZCU_NM_BSMtoRMS_CHCANFD";
BA_ "LongName" SG_ 1267 IRZCU_NM_BSMtoRMS_CHCANFD "RZCU NM BSMtoRMS CHCANFD";
BA_ "SysSignalName" SG_ 1267 IRZCU_NM_BSMtoRMS_CHCANFD "RZCU_NM_BSMtoRMS_CHCANFD";
BA_ "CompuMethodName" SG_ 1267 IRZCU_NM_PBSMtoRMS_CHCANFD "RZCU_NM_PBSMtoRMS_CHCANFD";
BA_ "ISignalName" SG_ 1267 IRZCU_NM_PBSMtoRMS_CHCANFD "IRZCU_NM_PBSMtoRMS_CHCANFD";
BA_ "LongName" SG_ 1267 IRZCU_NM_PBSMtoRMS_CHCANFD "RZCU NM PBSMtoRMS CHCANFD";
BA_ "SysSignalName" SG_ 1267 IRZCU_NM_PBSMtoRMS_CHCANFD "RZCU_NM_PBSMtoRMS_CHCANFD";
BA_ "CompuMethodName" SG_ 1267 IRZCU_NM_RMStoNOS_CHCANFD "RZCU_NM_RMStoNOS_CHCANFD";
BA_ "ISignalName" SG_ 1267 IRZCU_NM_RMStoNOS_CHCANFD "IRZCU_NM_RMStoNOS_CHCANFD";
BA_ "LongName" SG_ 1267 IRZCU_NM_RMStoNOS_CHCANFD "RZCU NM RMStoNOS CHCANFD";
BA_ "SysSignalName" SG_ 1267 IRZCU_NM_RMStoNOS_CHCANFD "RZCU_NM_RMStoNOS_CHCANFD";
BA_ "CompuMethodName" SG_ 1267 IRZCU_NM_RSStoNOS_CHCANFD "RZCU_NM_RSStoNOS_CHCANFD";
BA_ "ISignalName" SG_ 1267 IRZCU_NM_RSStoNOS_CHCANFD "IRZCU_NM_RSStoNOS_CHCANFD";
BA_ "LongName" SG_ 1267 IRZCU_NM_RSStoNOS_CHCANFD "RZCU NM RSStoNOS CHCANFD";
BA_ "SysSignalName" SG_ 1267 IRZCU_NM_RSStoNOS_CHCANFD "RZCU_NM_RSStoNOS_CHCANFD";
BA_ "CompuMethodName" SG_ 1267 IRZCU_NM_RSStoRMS_CHCANFD "RZCU_NM_RSStoRMS_CHCANFD";
BA_ "ISignalName" SG_ 1267 IRZCU_NM_RSStoRMS_CHCANFD "IRZCU_NM_RSStoRMS_CHCANFD";
BA_ "LongName" SG_ 1267 IRZCU_NM_RSStoRMS_CHCANFD "RZCU NM RSStoRMS CHCANFD";
BA_ "SysSignalName" SG_ 1267 IRZCU_NM_RSStoRMS_CHCANFD "RZCU_NM_RSStoRMS_CHCANFD";
BA_ "CompuMethodName" SG_ 1267 IRZCU_NM_NOStoRMS_CHCANFD "RZCU_NM_NOStoRMS_CHCANFD";
BA_ "ISignalName" SG_ 1267 IRZCU_NM_NOStoRMS_CHCANFD "IRZCU_NM_NOStoRMS_CHCANFD";
BA_ "LongName" SG_ 1267 IRZCU_NM_NOStoRMS_CHCANFD "RZCU NM NOStoRMS CHCANFD";
BA_ "SysSignalName" SG_ 1267 IRZCU_NM_NOStoRMS_CHCANFD "RZCU_NM_NOStoRMS_CHCANFD";
BA_ "CompuMethodName" SG_ 1267 IRZCU_NM_NOSSta_CHCANFD "RZCU_NM_NOSSta_CHCANFD";
BA_ "ISignalName" SG_ 1267 IRZCU_NM_NOSSta_CHCANFD "IRZCU_NM_NOSSta_CHCANFD";
BA_ "LongName" SG_ 1267 IRZCU_NM_NOSSta_CHCANFD "RZCU NM NOSSta CHCANFD";
BA_ "SysSignalName" SG_ 1267 IRZCU_NM_NOSSta_CHCANFD "RZCU_NM_NOSSta_CHCANFD";
BA_ "CompuMethodName" SG_ 1267 IRZCU_NM_RMSSta_CHCANFD "RZCU_NM_RMSSta_CHCANFD";
BA_ "ISignalName" SG_ 1267 IRZCU_NM_RMSSta_CHCANFD "IRZCU_NM_RMSSta_CHCANFD";
BA_ "LongName" SG_ 1267 IRZCU_NM_RMSSta_CHCANFD "RZCU NM RMSSta CHCANFD";
BA_ "SysSignalName" SG_ 1267 IRZCU_NM_RMSSta_CHCANFD "RZCU_NM_RMSSta_CHCANFD";
BA_ "CompuMethodName" SG_ 1267 IRZCU_NWI_CHCANFD "RZCU_NWI_CHCANFD";
BA_ "ISignalName" SG_ 1267 IRZCU_NWI_CHCANFD "IRZCU_NWI_CHCANFD";
BA_ "LongName" SG_ 1267 IRZCU_NWI_CHCANFD "RZCU CHCANFD Network_Wakeup_Indication";
BA_ "SysSignalName" SG_ 1267 IRZCU_NWI_CHCANFD "RZCU_NWI_CHCANFD";
BA_ "CompuMethodName" SG_ 1267 IRZCU_NOI_CHCANFD "RZCU_NOI_CHCANFD";
BA_ "ISignalName" SG_ 1267 IRZCU_NOI_CHCANFD "IRZCU_NOI_CHCANFD";
BA_ "LongName" SG_ 1267 IRZCU_NOI_CHCANFD "RZCU CHCANFD Network Operation Indication";
BA_ "SysSignalName" SG_ 1267 IRZCU_NOI_CHCANFD "RZCU_NOI_CHCANFD";
BA_ "CompuMethodName" SG_ 1267 IRZCU_NKI_CHCANFD "RZCU_NKI_CHCANFD";
BA_ "ISignalName" SG_ 1267 IRZCU_NKI_CHCANFD "IRZCU_NKI_CHCANFD";
BA_ "LongName" SG_ 1267 IRZCU_NKI_CHCANFD "RZCU CHCANFD Network Keep Indication";
BA_ "SysSignalName" SG_ 1267 IRZCU_NKI_CHCANFD "RZCU_NKI_CHCANFD";
BA_ "CompuMethodName" SG_ 1611 IIMU_SN "IMU_SN";
BA_ "ISignalName" SG_ 1611 IIMU_SN "IIMU_SN";
BA_ "LongName" SG_ 1611 IIMU_SN "IMU Serial Number";
BA_ "SysSignalName" SG_ 1611 IIMU_SN "IMU_SN";
BA_ "CompuMethodName" SG_ 247 IRZCU_10ms_Group22_CRC "RZCU_10ms_Group22_CRC";
BA_ "ISignalName" SG_ 247 IRZCU_10ms_Group22_CRC "IRZCU_10ms_Group22_CRC";
BA_ "SysSignalName" SG_ 247 IRZCU_10ms_Group22_CRC "RZCU_10ms_Group22_CRC";
BA_ "CompuMethodName" SG_ 247 IRZCU_10ms_Group22_RC "RZCU_10ms_Group22_RC";
BA_ "ISignalName" SG_ 247 IRZCU_10ms_Group22_RC "IRZCU_10ms_Group22_RC";
BA_ "SysSignalName" SG_ 247 IRZCU_10ms_Group22_RC "RZCU_10ms_Group22_RC";
BA_ "CompuMethodName" SG_ 247 IRZCU_10ms_Group22_Reserved1 "RZCU_10ms_Group22_Reserved1";
BA_ "GenSigStartValue" SG_ 247 IRZCU_10ms_Group22_Reserved1 3;
BA_ "ISignalName" SG_ 247 IRZCU_10ms_Group22_Reserved1 "IRZCU_10ms_Group22_Reserved1";
BA_ "SysSignalName" SG_ 247 IRZCU_10ms_Group22_Reserved1 "RZCU_10ms_Group22_Reserved1";
BA_ "CompuMethodName" SG_ 247 IEPTTrOtptShaftTotMinAvlblToqV "EPTTrOtptShaftTotMinAvlblToqV";
BA_ "ISignalName" SG_ 247 IEPTTrOtptShaftTotMinAvlblToqV "IEPTTrOtptShaftTotMinAvlblToqV";
BA_ "LongName" SG_ 247 IEPTTrOtptShaftTotMinAvlblToqV "Electric_Powertrain_Transmission_Output_Shaft_Total_Minimum_Available_Torque_Validity";
BA_ "SysSignalName" SG_ 247 IEPTTrOtptShaftTotMinAvlblToqV "EPTTrOtptShaftTotMinAvlblToqV";
BA_ "CompuMethodName" SG_ 247 IEPTTrOtptShaftTotMaxAvlblToqV "EPTTrOtptShaftTotMaxAvlblToqV";
BA_ "ISignalName" SG_ 247 IEPTTrOtptShaftTotMaxAvlblToqV "IEPTTrOtptShaftTotMaxAvlblToqV";
BA_ "LongName" SG_ 247 IEPTTrOtptShaftTotMaxAvlblToqV "Electric_Powertrain_Transmission_Output_Shaft_Total_Maximum_Available_Torque_Validity";
BA_ "SysSignalName" SG_ 247 IEPTTrOtptShaftTotMaxAvlblToqV "EPTTrOtptShaftTotMaxAvlblToqV";
BA_ "CompuMethodName" SG_ 247 IEPTTrOtptShaftTotMaxAvlblToq "EPTTrOtptShaftTotMaxAvlblToq";
BA_ "GenSigStartValue" SG_ 247 IEPTTrOtptShaftTotMaxAvlblToq 1696;
BA_ "ISignalName" SG_ 247 IEPTTrOtptShaftTotMaxAvlblToq "IEPTTrOtptShaftTotMaxAvlblToq";
BA_ "LongName" SG_ 247 IEPTTrOtptShaftTotMaxAvlblToq "Electric_Powertrain_Transmission_Output_Shaft_Total_Maximum_Available_Torque";
BA_ "SysSignalName" SG_ 247 IEPTTrOtptShaftTotMaxAvlblToq "EPTTrOtptShaftTotMaxAvlblToq";
BA_ "CompuMethodName" SG_ 247 IEPTTrOtptShaftTotMinAvlblToq "EPTTrOtptShaftTotMinAvlblToq";
BA_ "ISignalName" SG_ 247 IEPTTrOtptShaftTotMinAvlblToq "IEPTTrOtptShaftTotMinAvlblToq";
BA_ "LongName" SG_ 247 IEPTTrOtptShaftTotMinAvlblToq "Electric_Powertrain_Transmission_Output_Shaft_Total_Minimum_Available_Torque";
BA_ "SysSignalName" SG_ 247 IEPTTrOtptShaftTotMinAvlblToq "EPTTrOtptShaftTotMinAvlblToq";
BA_ "CompuMethodName" SG_ 247 IEPTTrOtptShaftTotToq "EPTTrOtptShaftTotToq";
BA_ "ISignalName" SG_ 247 IEPTTrOtptShaftTotToq "IEPTTrOtptShaftTotToq";
BA_ "LongName" SG_ 247 IEPTTrOtptShaftTotToq "Electric_Powertrain_Transmission_Output_Shaft_Total_Torque";
BA_ "SysSignalName" SG_ 247 IEPTTrOtptShaftTotToq "EPTTrOtptShaftTotToq";
BA_ "CompuMethodName" SG_ 247 IEPTTrOtptShaftTotToqV "EPTTrOtptShaftTotToqV";
BA_ "GenSigStartValue" SG_ 247 IEPTTrOtptShaftTotToqV 1;
BA_ "ISignalName" SG_ 247 IEPTTrOtptShaftTotToqV "IEPTTrOtptShaftTotToqV";
BA_ "LongName" SG_ 247 IEPTTrOtptShaftTotToqV "Electric_Powertrain_Transmission_Output_Shaft_Total_Torque_Validity";
BA_ "SysSignalName" SG_ 247 IEPTTrOtptShaftTotToqV "EPTTrOtptShaftTotToqV";
BA_ "CompuMethodName" SG_ 247 IRZCU_10ms_Group22_Reserved2 "RZCU_10ms_Group22_Reserved2";
BA_ "GenSigStartValue" SG_ 247 IRZCU_10ms_Group22_Reserved2 7;
BA_ "ISignalName" SG_ 247 IRZCU_10ms_Group22_Reserved2 "IRZCU_10ms_Group22_Reserved2";
BA_ "SysSignalName" SG_ 247 IRZCU_10ms_Group22_Reserved2 "RZCU_10ms_Group22_Reserved2";
BA_ "CompuMethodName" SG_ 247 IRZCU_10ms_Group22_Reserved3 "RZCU_10ms_Group22_Reserved3";
BA_ "GenSigStartValue" SG_ 247 IRZCU_10ms_Group22_Reserved3 255;
BA_ "ISignalName" SG_ 247 IRZCU_10ms_Group22_Reserved3 "IRZCU_10ms_Group22_Reserved3";
BA_ "SysSignalName" SG_ 247 IRZCU_10ms_Group22_Reserved3 "RZCU_10ms_Group22_Reserved3";
BA_ "CompuMethodName" SG_ 247 IRZCU_10ms_Group22_Reserved4 "RZCU_10ms_Group22_Reserved4";
BA_ "GenSigStartValue" SG_ 247 IRZCU_10ms_Group22_Reserved4 255;
BA_ "ISignalName" SG_ 247 IRZCU_10ms_Group22_Reserved4 "IRZCU_10ms_Group22_Reserved4";
BA_ "SysSignalName" SG_ 247 IRZCU_10ms_Group22_Reserved4 "RZCU_10ms_Group22_Reserved4";
BA_ "CompuMethodName" SG_ 247 IRZCU_10ms_Group22_Reserved5 "RZCU_10ms_Group22_Reserved5";
BA_ "GenSigStartValue" SG_ 247 IRZCU_10ms_Group22_Reserved5 255;
BA_ "ISignalName" SG_ 247 IRZCU_10ms_Group22_Reserved5 "IRZCU_10ms_Group22_Reserved5";
BA_ "SysSignalName" SG_ 247 IRZCU_10ms_Group22_Reserved5 "RZCU_10ms_Group22_Reserved5";
BA_ "CompuMethodName" SG_ 247 IRZCU_10ms_Group22_Reserved6 "RZCU_10ms_Group22_Reserved6";
BA_ "GenSigStartValue" SG_ 247 IRZCU_10ms_Group22_Reserved6 255;
BA_ "ISignalName" SG_ 247 IRZCU_10ms_Group22_Reserved6 "IRZCU_10ms_Group22_Reserved6";
BA_ "SysSignalName" SG_ 247 IRZCU_10ms_Group22_Reserved6 "RZCU_10ms_Group22_Reserved6";
BA_ "CompuMethodName" SG_ 247 IRZCU_10ms_Group22_Reserved7 "RZCU_10ms_Group22_Reserved7";
BA_ "GenSigStartValue" SG_ 247 IRZCU_10ms_Group22_Reserved7 255;
BA_ "ISignalName" SG_ 247 IRZCU_10ms_Group22_Reserved7 "IRZCU_10ms_Group22_Reserved7";
BA_ "SysSignalName" SG_ 247 IRZCU_10ms_Group22_Reserved7 "RZCU_10ms_Group22_Reserved7";
BA_ "CompuMethodName" SG_ 201 IRZCU_10ms_Group24_CRC "RZCU_10ms_Group24_CRC";
BA_ "ISignalName" SG_ 201 IRZCU_10ms_Group24_CRC "IRZCU_10ms_Group24_CRC";
BA_ "SysSignalName" SG_ 201 IRZCU_10ms_Group24_CRC "RZCU_10ms_Group24_CRC";
BA_ "CompuMethodName" SG_ 201 IRZCU_10ms_Group24_RC "RZCU_10ms_Group24_RC";
BA_ "ISignalName" SG_ 201 IRZCU_10ms_Group24_RC "IRZCU_10ms_Group24_RC";
BA_ "SysSignalName" SG_ 201 IRZCU_10ms_Group24_RC "RZCU_10ms_Group24_RC";
BA_ "CompuMethodName" SG_ 201 IRZCU_10ms_Group24_Reserved1 "RZCU_10ms_Group24_Reserved1";
BA_ "GenSigStartValue" SG_ 201 IRZCU_10ms_Group24_Reserved1 15;
BA_ "ISignalName" SG_ 201 IRZCU_10ms_Group24_Reserved1 "IRZCU_10ms_Group24_Reserved1";
BA_ "SysSignalName" SG_ 201 IRZCU_10ms_Group24_Reserved1 "RZCU_10ms_Group24_Reserved1";
BA_ "CompuMethodName" SG_ 201 IVCUAPAUnderCtrlA "VCUAPAUnderCtrlA";
BA_ "ISignalName" SG_ 201 IVCUAPAUnderCtrlA "IVCUAPAUnderCtrlA";
BA_ "LongName" SG_ 201 IVCUAPAUnderCtrlA "Apa Vcu Under Control Active";
BA_ "SysSignalName" SG_ 201 IVCUAPAUnderCtrlA "VCUAPAUnderCtrlA";
BA_ "CompuMethodName" SG_ 201 IVCUAPAFltRsn "VCUAPAFltRsn";
BA_ "ISignalName" SG_ 201 IVCUAPAFltRsn "IVCUAPAFltRsn";
BA_ "LongName" SG_ 201 IVCUAPAFltRsn "VCU APA Fault Reason";
BA_ "SysSignalName" SG_ 201 IVCUAPAFltRsn "VCUAPAFltRsn";
BA_ "CompuMethodName" SG_ 201 IEPTAPARevrDrgReqResp "EPTAPARevrDrgReqResp";
BA_ "ISignalName" SG_ 201 IEPTAPARevrDrgReqResp "IEPTAPARevrDrgReqResp";
BA_ "LongName" SG_ 201 IEPTAPARevrDrgReqResp "EPT APA Reverse Drag Request Response";
BA_ "SysSignalName" SG_ 201 IEPTAPARevrDrgReqResp "EPTAPARevrDrgReqResp";
BA_ "CompuMethodName" SG_ 201 IRZCU_10ms_Group24_Reserved2 "RZCU_10ms_Group24_Reserved2";
BA_ "GenSigStartValue" SG_ 201 IRZCU_10ms_Group24_Reserved2 255;
BA_ "ISignalName" SG_ 201 IRZCU_10ms_Group24_Reserved2 "IRZCU_10ms_Group24_Reserved2";
BA_ "SysSignalName" SG_ 201 IRZCU_10ms_Group24_Reserved2 "RZCU_10ms_Group24_Reserved2";
BA_ "CompuMethodName" SG_ 201 IRZCU_10ms_Group24_Reserved3 "RZCU_10ms_Group24_Reserved3";
BA_ "GenSigStartValue" SG_ 201 IRZCU_10ms_Group24_Reserved3 255;
BA_ "ISignalName" SG_ 201 IRZCU_10ms_Group24_Reserved3 "IRZCU_10ms_Group24_Reserved3";
BA_ "SysSignalName" SG_ 201 IRZCU_10ms_Group24_Reserved3 "RZCU_10ms_Group24_Reserved3";
BA_ "CompuMethodName" SG_ 201 IRZCU_10ms_Group24_Reserved4 "RZCU_10ms_Group24_Reserved4";
BA_ "GenSigStartValue" SG_ 201 IRZCU_10ms_Group24_Reserved4 255;
BA_ "ISignalName" SG_ 201 IRZCU_10ms_Group24_Reserved4 "IRZCU_10ms_Group24_Reserved4";
BA_ "SysSignalName" SG_ 201 IRZCU_10ms_Group24_Reserved4 "RZCU_10ms_Group24_Reserved4";
BA_ "CompuMethodName" SG_ 201 IRZCU_10ms_Group24_Reserved5 "RZCU_10ms_Group24_Reserved5";
BA_ "GenSigStartValue" SG_ 201 IRZCU_10ms_Group24_Reserved5 255;
BA_ "ISignalName" SG_ 201 IRZCU_10ms_Group24_Reserved5 "IRZCU_10ms_Group24_Reserved5";
BA_ "SysSignalName" SG_ 201 IRZCU_10ms_Group24_Reserved5 "RZCU_10ms_Group24_Reserved5";
BA_ "CompuMethodName" SG_ 201 IRZCU_10ms_Group24_Reserved6 "RZCU_10ms_Group24_Reserved6";
BA_ "GenSigStartValue" SG_ 201 IRZCU_10ms_Group24_Reserved6 255;
BA_ "ISignalName" SG_ 201 IRZCU_10ms_Group24_Reserved6 "IRZCU_10ms_Group24_Reserved6";
BA_ "SysSignalName" SG_ 201 IRZCU_10ms_Group24_Reserved6 "RZCU_10ms_Group24_Reserved6";
BA_ "CompuMethodName" SG_ 143 IRZCU_ZONE_10ms_Group64_CRC "RZCU_ZONE_10ms_Group64_CRC";
BA_ "ISignalName" SG_ 143 IRZCU_ZONE_10ms_Group64_CRC "IRZCU_ZONE_10ms_Group64_CRC";
BA_ "SysSignalName" SG_ 143 IRZCU_ZONE_10ms_Group64_CRC "RZCU_ZONE_10ms_Group64_CRC";
BA_ "CompuMethodName" SG_ 143 IRZCU_ZONE_10ms_Group64_RC "RZCU_ZONE_10ms_Group64_RC";
BA_ "ISignalName" SG_ 143 IRZCU_ZONE_10ms_Group64_RC "IRZCU_ZONE_10ms_Group64_RC";
BA_ "SysSignalName" SG_ 143 IRZCU_ZONE_10ms_Group64_RC "RZCU_ZONE_10ms_Group64_RC";
BA_ "CompuMethodName" SG_ 143 IAngularRateXsecinfoV "AngularRateXsecinfoV";
BA_ "ISignalName" SG_ 143 IAngularRateXsecinfoV "IAngularRateXsecinfoV";
BA_ "LongName" SG_ 143 IAngularRateXsecinfoV "Angularrate_X Valid";
BA_ "SysSignalName" SG_ 143 IAngularRateXsecinfoV "AngularRateXsecinfoV";
BA_ "CompuMethodName" SG_ 143 IAccelerationZsecinfoV "AccelerationZsecinfoV";
BA_ "ISignalName" SG_ 143 IAccelerationZsecinfoV "IAccelerationZsecinfoV";
BA_ "LongName" SG_ 143 IAccelerationZsecinfoV "Acceleration_Z Valid";
BA_ "SysSignalName" SG_ 143 IAccelerationZsecinfoV "AccelerationZsecinfoV";
BA_ "CompuMethodName" SG_ 143 IAccelerationYsecinfoV "AccelerationYsecinfoV";
BA_ "ISignalName" SG_ 143 IAccelerationYsecinfoV "IAccelerationYsecinfoV";
BA_ "LongName" SG_ 143 IAccelerationYsecinfoV "Acceleration_Y Valid";
BA_ "SysSignalName" SG_ 143 IAccelerationYsecinfoV "AccelerationYsecinfoV";
BA_ "CompuMethodName" SG_ 143 IAccelerationXsecinfoV "AccelerationXsecinfoV";
BA_ "ISignalName" SG_ 143 IAccelerationXsecinfoV "IAccelerationXsecinfoV";
BA_ "LongName" SG_ 143 IAccelerationXsecinfoV "Acceleration_X Valid";
BA_ "SysSignalName" SG_ 143 IAccelerationXsecinfoV "AccelerationXsecinfoV";
BA_ "CompuMethodName" SG_ 143 IAccelerationXsecinfo "AccelerationXsecinfo";
BA_ "ISignalName" SG_ 143 IAccelerationXsecinfo "IAccelerationXsecinfo";
BA_ "LongName" SG_ 143 IAccelerationXsecinfo "Acceleration_X";
BA_ "SysSignalName" SG_ 143 IAccelerationXsecinfo "AccelerationXsecinfo";
BA_ "CompuMethodName" SG_ 143 IAccelerationYsecinfo "AccelerationYsecinfo";
BA_ "ISignalName" SG_ 143 IAccelerationYsecinfo "IAccelerationYsecinfo";
BA_ "LongName" SG_ 143 IAccelerationYsecinfo "Acceleration_Y";
BA_ "SysSignalName" SG_ 143 IAccelerationYsecinfo "AccelerationYsecinfo";
BA_ "CompuMethodName" SG_ 143 IAccelerationZsecinfo "AccelerationZsecinfo";
BA_ "ISignalName" SG_ 143 IAccelerationZsecinfo "IAccelerationZsecinfo";
BA_ "LongName" SG_ 143 IAccelerationZsecinfo "Acceleration_Z";
BA_ "SysSignalName" SG_ 143 IAccelerationZsecinfo "AccelerationZsecinfo";
BA_ "CompuMethodName" SG_ 143 IAngularRateXsecinfo "AngularRateXsecinfo";
BA_ "ISignalName" SG_ 143 IAngularRateXsecinfo "IAngularRateXsecinfo";
BA_ "LongName" SG_ 143 IAngularRateXsecinfo "Angularrate_X";
BA_ "SysSignalName" SG_ 143 IAngularRateXsecinfo "AngularRateXsecinfo";
BA_ "CompuMethodName" SG_ 143 IAngularRateYsecinfo "AngularRateYsecinfo";
BA_ "ISignalName" SG_ 143 IAngularRateYsecinfo "IAngularRateYsecinfo";
BA_ "LongName" SG_ 143 IAngularRateYsecinfo "Angularrate_Y";
BA_ "SysSignalName" SG_ 143 IAngularRateYsecinfo "AngularRateYsecinfo";
BA_ "CompuMethodName" SG_ 143 IAngularRateZsecinfo "AngularRateZsecinfo";
BA_ "ISignalName" SG_ 143 IAngularRateZsecinfo "IAngularRateZsecinfo";
BA_ "LongName" SG_ 143 IAngularRateZsecinfo "Angularrate_Z";
BA_ "SysSignalName" SG_ 143 IAngularRateZsecinfo "AngularRateZsecinfo";
BA_ "CompuMethodName" SG_ 143 IIMUTmp "IMUTmp";
BA_ "ISignalName" SG_ 143 IIMUTmp "IIMUTmp";
BA_ "LongName" SG_ 143 IIMUTmp "IMU Temperature";
BA_ "SysSignalName" SG_ 143 IIMUTmp "IMUTmp";
BA_ "CompuMethodName" SG_ 143 IRZCU_ZONE_10ms_Group64_Reserved0 "RZCU_ZONE_10ms_Group64_Reserved1";
BA_ "GenSigStartValue" SG_ 143 IRZCU_ZONE_10ms_Group64_Reserved0 1;
BA_ "ISignalName" SG_ 143 IRZCU_ZONE_10ms_Group64_Reserved0 "IRZCU_ZONE_10ms_Group64_Reserved1";
BA_ "SysSignalName" SG_ 143 IRZCU_ZONE_10ms_Group64_Reserved0 "RZCU_ZONE_10ms_Group64_Reserved1";
BA_ "SystemSignalLongSymbol" SG_ 143 IRZCU_ZONE_10ms_Group64_Reserved0 "IRZCU_ZONE_10ms_Group64_Reserved1";
BA_ "CompuMethodName" SG_ 143 ITireBlowoutStabCtrlSts "TireBlowoutStabCtrlSts";
BA_ "ISignalName" SG_ 143 ITireBlowoutStabCtrlSts "ITireBlowoutStabCtrlSts";
BA_ "LongName" SG_ 143 ITireBlowoutStabCtrlSts "Tire_Blowout_Stability_Control_Status";
BA_ "SysSignalName" SG_ 143 ITireBlowoutStabCtrlSts "TireBlowoutStabCtrlSts";
BA_ "CompuMethodName" SG_ 143 IAngularRateZsecinfoV "AngularRateZsecinfoV";
BA_ "ISignalName" SG_ 143 IAngularRateZsecinfoV "IAngularRateZsecinfoV";
BA_ "LongName" SG_ 143 IAngularRateZsecinfoV "Angularrate_Z Valid";
BA_ "SysSignalName" SG_ 143 IAngularRateZsecinfoV "AngularRateZsecinfoV";
BA_ "CompuMethodName" SG_ 143 IAngularRateYsecinfoV "AngularRateYsecinfoV";
BA_ "ISignalName" SG_ 143 IAngularRateYsecinfoV "IAngularRateYsecinfoV";
BA_ "LongName" SG_ 143 IAngularRateYsecinfoV "Angularrate_Y Valid";
BA_ "SysSignalName" SG_ 143 IAngularRateYsecinfoV "AngularRateYsecinfoV";
BA_ "CompuMethodName" SG_ 143 IIMUseq "IMUseq";
BA_ "ISignalName" SG_ 143 IIMUseq "IIMUseq";
BA_ "LongName" SG_ 143 IIMUseq "Imu Messages Sequence";
BA_ "SysSignalName" SG_ 143 IIMUseq "IMUseq";
BA_ "CompuMethodName" SG_ 143 IRZCU_ZONE_10ms_Group64_Reserved1 "RZCU_ZONE_10ms_Group64_Reserved2";
BA_ "GenSigStartValue" SG_ 143 IRZCU_ZONE_10ms_Group64_Reserved1 15;
BA_ "ISignalName" SG_ 143 IRZCU_ZONE_10ms_Group64_Reserved1 "IRZCU_ZONE_10ms_Group64_Reserved2";
BA_ "SysSignalName" SG_ 143 IRZCU_ZONE_10ms_Group64_Reserved1 "RZCU_ZONE_10ms_Group64_Reserved2";
BA_ "SystemSignalLongSymbol" SG_ 143 IRZCU_ZONE_10ms_Group64_Reserved1 "IRZCU_ZONE_10ms_Group64_Reserved2";
BA_ "CompuMethodName" SG_ 143 ITireBlowoutPos "TireBlowoutPos";
BA_ "ISignalName" SG_ 143 ITireBlowoutPos "ITireBlowoutPos";
BA_ "LongName" SG_ 143 ITireBlowoutPos "Tire_Blowout_Position";
BA_ "SysSignalName" SG_ 143 ITireBlowoutPos "TireBlowoutPos";
BA_ "CompuMethodName" SG_ 143 IRZCU_ZONE_10ms_Group64_Reserved2 "RZCU_ZONE_10ms_Group64_Reserved3";
BA_ "GenSigStartValue" SG_ 143 IRZCU_ZONE_10ms_Group64_Reserved2 255;
BA_ "ISignalName" SG_ 143 IRZCU_ZONE_10ms_Group64_Reserved2 "IRZCU_ZONE_10ms_Group64_Reserved3";
BA_ "SysSignalName" SG_ 143 IRZCU_ZONE_10ms_Group64_Reserved2 "RZCU_ZONE_10ms_Group64_Reserved3";
BA_ "SystemSignalLongSymbol" SG_ 143 IRZCU_ZONE_10ms_Group64_Reserved2 "IRZCU_ZONE_10ms_Group64_Reserved3";
BA_ "CompuMethodName" SG_ 143 IRZCU_ZONE_10ms_Group64_Reserved3 "RZCU_ZONE_10ms_Group64_Reserved4";
BA_ "GenSigStartValue" SG_ 143 IRZCU_ZONE_10ms_Group64_Reserved3 255;
BA_ "ISignalName" SG_ 143 IRZCU_ZONE_10ms_Group64_Reserved3 "IRZCU_ZONE_10ms_Group64_Reserved4";
BA_ "SysSignalName" SG_ 143 IRZCU_ZONE_10ms_Group64_Reserved3 "RZCU_ZONE_10ms_Group64_Reserved4";
BA_ "SystemSignalLongSymbol" SG_ 143 IRZCU_ZONE_10ms_Group64_Reserved3 "IRZCU_ZONE_10ms_Group64_Reserved4";
BA_ "CompuMethodName" SG_ 143 IRZCU_ZONE_10ms_Group64_Reserved4 "RZCU_ZONE_10ms_Group64_Reserved5";
BA_ "GenSigStartValue" SG_ 143 IRZCU_ZONE_10ms_Group64_Reserved4 255;
BA_ "ISignalName" SG_ 143 IRZCU_ZONE_10ms_Group64_Reserved4 "IRZCU_ZONE_10ms_Group64_Reserved5";
BA_ "SysSignalName" SG_ 143 IRZCU_ZONE_10ms_Group64_Reserved4 "RZCU_ZONE_10ms_Group64_Reserved5";
BA_ "SystemSignalLongSymbol" SG_ 143 IRZCU_ZONE_10ms_Group64_Reserved4 "IRZCU_ZONE_10ms_Group64_Reserved5";
BA_ "CompuMethodName" SG_ 143 IRZCU_ZONE_10ms_Group64_Reserved5 "RZCU_ZONE_10ms_Group64_Reserved6";
BA_ "GenSigStartValue" SG_ 143 IRZCU_ZONE_10ms_Group64_Reserved5 255;
BA_ "ISignalName" SG_ 143 IRZCU_ZONE_10ms_Group64_Reserved5 "IRZCU_ZONE_10ms_Group64_Reserved6";
BA_ "SysSignalName" SG_ 143 IRZCU_ZONE_10ms_Group64_Reserved5 "RZCU_ZONE_10ms_Group64_Reserved6";
BA_ "SystemSignalLongSymbol" SG_ 143 IRZCU_ZONE_10ms_Group64_Reserved5 "IRZCU_ZONE_10ms_Group64_Reserved6";
BA_ "CompuMethodName" SG_ 143 IRZCU_ZONE_10ms_Group64_Reserved6 "RZCU_ZONE_10ms_Group64_Reserved7";
BA_ "GenSigStartValue" SG_ 143 IRZCU_ZONE_10ms_Group64_Reserved6 255;
BA_ "ISignalName" SG_ 143 IRZCU_ZONE_10ms_Group64_Reserved6 "IRZCU_ZONE_10ms_Group64_Reserved7";
BA_ "SysSignalName" SG_ 143 IRZCU_ZONE_10ms_Group64_Reserved6 "RZCU_ZONE_10ms_Group64_Reserved7";
BA_ "SystemSignalLongSymbol" SG_ 143 IRZCU_ZONE_10ms_Group64_Reserved6 "IRZCU_ZONE_10ms_Group64_Reserved7";
BA_ "CompuMethodName" SG_ 1216 IZXD_NM_BSMtoRMS_CHCANFD "ZXD_NM_BSMtoRMS_CHCANFD";
BA_ "ISignalName" SG_ 1216 IZXD_NM_BSMtoRMS_CHCANFD "IZXD_NM_BSMtoRMS_CHCANFD";
BA_ "LongName" SG_ 1216 IZXD_NM_BSMtoRMS_CHCANFD "ZXD_NM_BSMtoRMS_CHCANFD";
BA_ "SysSignalName" SG_ 1216 IZXD_NM_BSMtoRMS_CHCANFD "ZXD_NM_BSMtoRMS_CHCANFD";
BA_ "CompuMethodName" SG_ 1216 IZXD_NM_PBSMtoRMS_CHCANFD "ZXD_NM_PBSMtoRMS_CHCANFD";
BA_ "ISignalName" SG_ 1216 IZXD_NM_PBSMtoRMS_CHCANFD "IZXD_NM_PBSMtoRMS_CHCANFD";
BA_ "LongName" SG_ 1216 IZXD_NM_PBSMtoRMS_CHCANFD "ZXD_NM_PBSMtoRMS_CHCANFD";
BA_ "SysSignalName" SG_ 1216 IZXD_NM_PBSMtoRMS_CHCANFD "ZXD_NM_PBSMtoRMS_CHCANFD";
BA_ "CompuMethodName" SG_ 1216 IZXD_NM_RMStoNOS_CHCANFD "ZXD_NM_RMStoNOS_CHCANFD";
BA_ "ISignalName" SG_ 1216 IZXD_NM_RMStoNOS_CHCANFD "IZXD_NM_RMStoNOS_CHCANFD";
BA_ "LongName" SG_ 1216 IZXD_NM_RMStoNOS_CHCANFD "ZXD_NM_RMStoNOS_CHCANFD";
BA_ "SysSignalName" SG_ 1216 IZXD_NM_RMStoNOS_CHCANFD "ZXD_NM_RMStoNOS_CHCANFD";
BA_ "CompuMethodName" SG_ 1216 IZXD_NM_RSStoNOS_CHCANFD "ZXD_NM_RSStoNOS_CHCANFD";
BA_ "ISignalName" SG_ 1216 IZXD_NM_RSStoNOS_CHCANFD "IZXD_NM_RSStoNOS_CHCANFD";
BA_ "LongName" SG_ 1216 IZXD_NM_RSStoNOS_CHCANFD "ZXD_NM_RSStoNOS_CHCANFD";
BA_ "SysSignalName" SG_ 1216 IZXD_NM_RSStoNOS_CHCANFD "ZXD_NM_RSStoNOS_CHCANFD";
BA_ "CompuMethodName" SG_ 1216 IZXD_NM_RSStoRMS_CHCANFD "ZXD_NM_RSStoRMS_CHCANFD";
BA_ "ISignalName" SG_ 1216 IZXD_NM_RSStoRMS_CHCANFD "IZXD_NM_RSStoRMS_CHCANFD";
BA_ "LongName" SG_ 1216 IZXD_NM_RSStoRMS_CHCANFD "ZXD_NM_RSStoRMS_CHCANFD";
BA_ "SysSignalName" SG_ 1216 IZXD_NM_RSStoRMS_CHCANFD "ZXD_NM_RSStoRMS_CHCANFD";
BA_ "CompuMethodName" SG_ 1216 IZXD_NM_NOStoRMS_CHCANFD "ZXD_NM_NOStoRMS_CHCANFD";
BA_ "ISignalName" SG_ 1216 IZXD_NM_NOStoRMS_CHCANFD "IZXD_NM_NOStoRMS_CHCANFD";
BA_ "LongName" SG_ 1216 IZXD_NM_NOStoRMS_CHCANFD "ZXD_NM_NOStoRMS_CHCANFD";
BA_ "SysSignalName" SG_ 1216 IZXD_NM_NOStoRMS_CHCANFD "ZXD_NM_NOStoRMS_CHCANFD";
BA_ "CompuMethodName" SG_ 1216 IZXD_NM_NOSSta_CHCANFD "ZXD_NM_NOSSta_CHCANFD";
BA_ "ISignalName" SG_ 1216 IZXD_NM_NOSSta_CHCANFD "IZXD_NM_NOSSta_CHCANFD";
BA_ "LongName" SG_ 1216 IZXD_NM_NOSSta_CHCANFD "ZXD_NM_NOSSta_CHCANFD";
BA_ "SysSignalName" SG_ 1216 IZXD_NM_NOSSta_CHCANFD "ZXD_NM_NOSSta_CHCANFD";
BA_ "CompuMethodName" SG_ 1216 IZXD_NM_RMSSta_CHCANFD "ZXD_NM_RMSSta_CHCANFD";
BA_ "ISignalName" SG_ 1216 IZXD_NM_RMSSta_CHCANFD "IZXD_NM_RMSSta_CHCANFD";
BA_ "LongName" SG_ 1216 IZXD_NM_RMSSta_CHCANFD "ZXD_NM_RMSSta_CHCANFD";
BA_ "SysSignalName" SG_ 1216 IZXD_NM_RMSSta_CHCANFD "ZXD_NM_RMSSta_CHCANFD";
BA_ "CompuMethodName" SG_ 1216 IZXD_NWI_CHCANFD "ZXD_NWI_CHCANFD";
BA_ "ISignalName" SG_ 1216 IZXD_NWI_CHCANFD "IZXD_NWI_CHCANFD";
BA_ "LongName" SG_ 1216 IZXD_NWI_CHCANFD "ZXD CHCANFD Network_Wakeup_Indication";
BA_ "SysSignalName" SG_ 1216 IZXD_NWI_CHCANFD "ZXD_NWI_CHCANFD";
BA_ "CompuMethodName" SG_ 1216 IZXD_NOI_CHCANFD "ZXD_NOI_CHCANFD";
BA_ "ISignalName" SG_ 1216 IZXD_NOI_CHCANFD "IZXD_NOI_CHCANFD";
BA_ "LongName" SG_ 1216 IZXD_NOI_CHCANFD "ZXD CHCANFD Network Operation Indication";
BA_ "SysSignalName" SG_ 1216 IZXD_NOI_CHCANFD "ZXD_NOI_CHCANFD";
BA_ "CompuMethodName" SG_ 1216 IZXD_NKI_CHCANFD "ZXD_NKI_CHCANFD";
BA_ "ISignalName" SG_ 1216 IZXD_NKI_CHCANFD "IZXD_NKI_CHCANFD";
BA_ "LongName" SG_ 1216 IZXD_NKI_CHCANFD "ZXD CHCANFD Network Keep Indication";
BA_ "SysSignalName" SG_ 1216 IZXD_NKI_CHCANFD "ZXD_NKI_CHCANFD";
BA_ "CompuMethodName" SG_ 308 IZXD_20ms_Group07_CRC "ZXD_20ms_Group07_CRC";
BA_ "ISignalName" SG_ 308 IZXD_20ms_Group07_CRC "IZXD_20ms_Group07_CRC";
BA_ "SysSignalName" SG_ 308 IZXD_20ms_Group07_CRC "ZXD_20ms_Group07_CRC";
BA_ "CompuMethodName" SG_ 308 IZXD_20ms_Group07_RC "ZXD_20ms_Group07_RC";
BA_ "ISignalName" SG_ 308 IZXD_20ms_Group07_RC "IZXD_20ms_Group07_RC";
BA_ "SysSignalName" SG_ 308 IZXD_20ms_Group07_RC "ZXD_20ms_Group07_RC";
BA_ "CompuMethodName" SG_ 308 IZXD_20ms_Group07_Reserved1 "ZXD_20ms_Group07_Reserved1";
BA_ "GenSigStartValue" SG_ 308 IZXD_20ms_Group07_Reserved1 15;
BA_ "ISignalName" SG_ 308 IZXD_20ms_Group07_Reserved1 "IZXD_20ms_Group07_Reserved1";
BA_ "SysSignalName" SG_ 308 IZXD_20ms_Group07_Reserved1 "ZXD_20ms_Group07_Reserved1";
BA_ "CompuMethodName" SG_ 308 IZXD_20ms_Group07_Reserved3 "ZXD_20ms_Group07_Reserved3";
BA_ "GenSigStartValue" SG_ 308 IZXD_20ms_Group07_Reserved3 7;
BA_ "ISignalName" SG_ 308 IZXD_20ms_Group07_Reserved3 "IZXD_20ms_Group07_Reserved3";
BA_ "SysSignalName" SG_ 308 IZXD_20ms_Group07_Reserved3 "ZXD_20ms_Group07_Reserved3";
BA_ "CompuMethodName" SG_ 308 IAPAEPBOPReq "APAEPBOPReq";
BA_ "ISignalName" SG_ 308 IAPAEPBOPReq "IAPAEPBOPReq";
BA_ "LongName" SG_ 308 IAPAEPBOPReq "Advanced Park Assist Electric Park Brake Operation Request";
BA_ "SysSignalName" SG_ 308 IAPAEPBOPReq "APAEPBOPReq";
BA_ "CompuMethodName" SG_ 308 IZXD_20ms_Group07_Reserved2 "ZXD_20ms_Group07_Reserved2";
BA_ "GenSigStartValue" SG_ 308 IZXD_20ms_Group07_Reserved2 7;
BA_ "ISignalName" SG_ 308 IZXD_20ms_Group07_Reserved2 "IZXD_20ms_Group07_Reserved2";
BA_ "SysSignalName" SG_ 308 IZXD_20ms_Group07_Reserved2 "ZXD_20ms_Group07_Reserved2";
BA_ "CompuMethodName" SG_ 308 IZXD_20ms_Group07_Reserved4 "ZXD_20ms_Group07_Reserved4";
BA_ "GenSigStartValue" SG_ 308 IZXD_20ms_Group07_Reserved4 255;
BA_ "ISignalName" SG_ 308 IZXD_20ms_Group07_Reserved4 "IZXD_20ms_Group07_Reserved4";
BA_ "SysSignalName" SG_ 308 IZXD_20ms_Group07_Reserved4 "ZXD_20ms_Group07_Reserved4";
BA_ "CompuMethodName" SG_ 308 IAIPkgAPASCSAcclReqVal "AIPkgAPASCSAcclReqVal";
BA_ "ISignalName" SG_ 308 IAIPkgAPASCSAcclReqVal "IAIPkgAPASCSAcclReqVal";
BA_ "LongName" SG_ 308 IAIPkgAPASCSAcclReqVal "Ai Parking APA Acceleration Request Value";
BA_ "SysSignalName" SG_ 308 IAIPkgAPASCSAcclReqVal "AIPkgAPASCSAcclReqVal";
BA_ "CompuMethodName" SG_ 308 IZXD_20ms_Group07_Reserved5 "ZXD_20ms_Group07_Reserved5";
BA_ "GenSigStartValue" SG_ 308 IZXD_20ms_Group07_Reserved5 7;
BA_ "ISignalName" SG_ 308 IZXD_20ms_Group07_Reserved5 "IZXD_20ms_Group07_Reserved5";
BA_ "SysSignalName" SG_ 308 IZXD_20ms_Group07_Reserved5 "ZXD_20ms_Group07_Reserved5";
BA_ "CompuMethodName" SG_ 308 IAPASCSAcclReqSts "APASCSAcclReqSts";
BA_ "ISignalName" SG_ 308 IAPASCSAcclReqSts "IAPASCSAcclReqSts";
BA_ "LongName" SG_ 308 IAPASCSAcclReqSts "Advanced Park Assist Stability Control System Acceleration Request Status";
BA_ "SysSignalName" SG_ 308 IAPASCSAcclReqSts "APASCSAcclReqSts";
BA_ "CompuMethodName" SG_ 308 IAPAEPBOPReqV "APAEPBOPReqV";
BA_ "ISignalName" SG_ 308 IAPAEPBOPReqV "IAPAEPBOPReqV";
BA_ "LongName" SG_ 308 IAPAEPBOPReqV "Advanced Park Assist Electric Park Brake Operation Request Validity";
BA_ "SysSignalName" SG_ 308 IAPAEPBOPReqV "APAEPBOPReqV";
BA_ "CompuMethodName" SG_ 308 IAutodDrvngSysSCSSdslReqV "AutodDrvngSysSCSSdslReqV";
BA_ "ISignalName" SG_ 308 IAutodDrvngSysSCSSdslReqV "IAutodDrvngSysSCSSdslReqV";
BA_ "LongName" SG_ 308 IAutodDrvngSysSCSSdslReqV "Automated Driving System Stability Control System Standstill Request Validity";
BA_ "SysSignalName" SG_ 308 IAutodDrvngSysSCSSdslReqV "AutodDrvngSysSCSSdslReqV";
BA_ "CompuMethodName" SG_ 308 IAutodDrvngSysSCSSdslReq "AutodDrvngSysSCSSdslReq";
BA_ "ISignalName" SG_ 308 IAutodDrvngSysSCSSdslReq "IAutodDrvngSysSCSSdslReq";
BA_ "LongName" SG_ 308 IAutodDrvngSysSCSSdslReq "Automated Driving System Stability Control System Standstill Request";
BA_ "SysSignalName" SG_ 308 IAutodDrvngSysSCSSdslReq "AutodDrvngSysSCSSdslReq";
BA_ "CompuMethodName" SG_ 308 IZXD_20ms_Group07_Reserved6 "ZXD_20ms_Group07_Reserved6";
BA_ "GenSigStartValue" SG_ 308 IZXD_20ms_Group07_Reserved6 63;
BA_ "ISignalName" SG_ 308 IZXD_20ms_Group07_Reserved6 "IZXD_20ms_Group07_Reserved6";
BA_ "SysSignalName" SG_ 308 IZXD_20ms_Group07_Reserved6 "ZXD_20ms_Group07_Reserved6";
BA_ "CompuMethodName" SG_ 308 IAutodDrvngSysSCSDrvOffReqV "AutodDrvngSysSCSDrvOffReqV";
BA_ "ISignalName" SG_ 308 IAutodDrvngSysSCSDrvOffReqV "IAutodDrvngSysSCSDrvOffReqV";
BA_ "LongName" SG_ 308 IAutodDrvngSysSCSDrvOffReqV "Automated Driving System Stability Control System Drive Off Request Validity";
BA_ "SysSignalName" SG_ 308 IAutodDrvngSysSCSDrvOffReqV "AutodDrvngSysSCSDrvOffReqV";
BA_ "CompuMethodName" SG_ 308 IAutodDrvngSysSCSDrvOffReq "AutodDrvngSysSCSDrvOffReq";
BA_ "ISignalName" SG_ 308 IAutodDrvngSysSCSDrvOffReq "IAutodDrvngSysSCSDrvOffReq";
BA_ "LongName" SG_ 308 IAutodDrvngSysSCSDrvOffReq "Automated Driving System Stability Control System Drive Off Request";
BA_ "SysSignalName" SG_ 308 IAutodDrvngSysSCSDrvOffReq "AutodDrvngSysSCSDrvOffReq";
BA_ "CompuMethodName" SG_ 308 IAutodDrvngSysMdReqV "AutodDrvngSysMdReqV";
BA_ "ISignalName" SG_ 308 IAutodDrvngSysMdReqV "IAutodDrvngSysMdReqV";
BA_ "LongName" SG_ 308 IAutodDrvngSysMdReqV "Automated Driving System Mode Request Validity";
BA_ "SysSignalName" SG_ 308 IAutodDrvngSysMdReqV "AutodDrvngSysMdReqV";
BA_ "CompuMethodName" SG_ 308 IAutodDrvngSysMdReq "AutodDrvngSysMdReq";
BA_ "ISignalName" SG_ 308 IAutodDrvngSysMdReq "IAutodDrvngSysMdReq";
BA_ "LongName" SG_ 308 IAutodDrvngSysMdReq "Automated Driving System Mode Request";
BA_ "SysSignalName" SG_ 308 IAutodDrvngSysMdReq "AutodDrvngSysMdReq";
BA_ "CompuMethodName" SG_ 308 IAutodDrvngSysFlrStsV "AutodDrvngSysFlrStsV";
BA_ "ISignalName" SG_ 308 IAutodDrvngSysFlrStsV "IAutodDrvngSysFlrStsV";
BA_ "LongName" SG_ 308 IAutodDrvngSysFlrStsV "Automated Driving System Failure Status Validity";
BA_ "SysSignalName" SG_ 308 IAutodDrvngSysFlrStsV "AutodDrvngSysFlrStsV";
BA_ "CompuMethodName" SG_ 308 IAutodDrvngSysFlrSts "AutodDrvngSysFlrSts";
BA_ "ISignalName" SG_ 308 IAutodDrvngSysFlrSts "IAutodDrvngSysFlrSts";
BA_ "LongName" SG_ 308 IAutodDrvngSysFlrSts "Automated Driving System Failure Status";
BA_ "SysSignalName" SG_ 308 IAutodDrvngSysFlrSts "AutodDrvngSysFlrSts";
BA_ "CompuMethodName" SG_ 429 IEPS_010ms_Group03_CRC "EPS_010ms_Group03_CRC";
BA_ "ISignalName" SG_ 429 IEPS_010ms_Group03_CRC "IEPS_010ms_Group03_CRC";
BA_ "SysSignalName" SG_ 429 IEPS_010ms_Group03_CRC "EPS_010ms_Group03_CRC";
BA_ "CompuMethodName" SG_ 429 IEPS_010ms_Group03_RC "EPS_010ms_Group03_RC";
BA_ "ISignalName" SG_ 429 IEPS_010ms_Group03_RC "IEPS_010ms_Group03_RC";
BA_ "SysSignalName" SG_ 429 IEPS_010ms_Group03_RC "EPS_010ms_Group03_RC";
BA_ "CompuMethodName" SG_ 429 IEPSAESReqResp "EPSAESReqResp";
BA_ "ISignalName" SG_ 429 IEPSAESReqResp "IEPSAESReqResp";
BA_ "LongName" SG_ 429 IEPSAESReqResp "Steering_AES_Request_Response";
BA_ "SysSignalName" SG_ 429 IEPSAESReqResp "EPSAESReqResp";
BA_ "CompuMethodName" SG_ 429 IEPSAESStsInh "EPSAESStsInh";
BA_ "ISignalName" SG_ 429 IEPSAESStsInh "IEPSAESStsInh";
BA_ "LongName" SG_ 429 IEPSAESStsInh "Electric_Power_Steering_AES_Request_Response_Inhibit_Reason";
BA_ "SysSignalName" SG_ 429 IEPSAESStsInh "EPSAESStsInh";
BA_ "CompuMethodName" SG_ 429 IEPSAESReqTorResp "EPSAESReqTorResp";
BA_ "GenSigStartValue" SG_ 429 IEPSAESReqTorResp 1024;
BA_ "ISignalName" SG_ 429 IEPSAESReqTorResp "IEPSAESReqTorResp";
BA_ "LongName" SG_ 429 IEPSAESReqTorResp "Electric_Power_Steering_AES_Request_Torque_Response";
BA_ "SysSignalName" SG_ 429 IEPSAESReqTorResp "EPSAESReqTorResp";
BA_ "CompuMethodName" SG_ 429 IEPS_010ms_Group03_Reserved1 "EPS_010ms_Group03_Reserved1";
BA_ "GenSigStartValue" SG_ 429 IEPS_010ms_Group03_Reserved1 1;
BA_ "ISignalName" SG_ 429 IEPS_010ms_Group03_Reserved1 "IEPS_010ms_Group03_Reserved1";
BA_ "SysSignalName" SG_ 429 IEPS_010ms_Group03_Reserved1 "EPS_010ms_Group03_Reserved1";
BA_ "CompuMethodName" SG_ 429 IEPSVMCAngRespSts "EPSVMCAngRespSts";
BA_ "ISignalName" SG_ 429 IEPSVMCAngRespSts "IEPSVMCAngRespSts";
BA_ "LongName" SG_ 429 IEPSVMCAngRespSts "Electric_Power_Steering_VMC_Angle_Response_Status";
BA_ "SysSignalName" SG_ 429 IEPSVMCAngRespSts "EPSVMCAngRespSts";
BA_ "CompuMethodName" SG_ 429 IEPSAESReqTorRespV "EPSAESReqTorRespV";
BA_ "ISignalName" SG_ 429 IEPSAESReqTorRespV "IEPSAESReqTorRespV";
BA_ "LongName" SG_ 429 IEPSAESReqTorRespV "Electric_Power_Steering_AES_Request_Torque_Response_Validity";
BA_ "SysSignalName" SG_ 429 IEPSAESReqTorRespV "EPSAESReqTorRespV";
BA_ "CompuMethodName" SG_ 429 IEPSVMCRespStsInh "EPSVMCRespStsInh";
BA_ "ISignalName" SG_ 429 IEPSVMCRespStsInh "IEPSVMCRespStsInh";
BA_ "LongName" SG_ 429 IEPSVMCRespStsInh "Electric_Power_Steering_VMC_Request_Response_Inhibit_Reason";
BA_ "SysSignalName" SG_ 429 IEPSVMCRespStsInh "EPSVMCRespStsInh";
BA_ "CompuMethodName" SG_ 429 IEPS_010ms_Group03_Reserved2 "EPS_010ms_Group03_Reserved2";
BA_ "GenSigStartValue" SG_ 429 IEPS_010ms_Group03_Reserved2 63;
BA_ "ISignalName" SG_ 429 IEPS_010ms_Group03_Reserved2 "IEPS_010ms_Group03_Reserved2";
BA_ "SysSignalName" SG_ 429 IEPS_010ms_Group03_Reserved2 "EPS_010ms_Group03_Reserved2";
BA_ "CompuMethodName" SG_ 429 IEPSVMCCodrivingSts "EPSVMCCodrivingSts";
BA_ "ISignalName" SG_ 429 IEPSVMCCodrivingSts "IEPSVMCCodrivingSts";
BA_ "LongName" SG_ 429 IEPSVMCCodrivingSts "Electric_Power_Steering_VMC_Codriving_Status";
BA_ "SysSignalName" SG_ 429 IEPSVMCCodrivingSts "EPSVMCCodrivingSts";
BA_ "CompuMethodName" SG_ 429 IEPS_010ms_Group03_Reserved3 "EPS_010ms_Group03_Reserved3";
BA_ "GenSigStartValue" SG_ 429 IEPS_010ms_Group03_Reserved3 255;
BA_ "ISignalName" SG_ 429 IEPS_010ms_Group03_Reserved3 "IEPS_010ms_Group03_Reserved3";
BA_ "SysSignalName" SG_ 429 IEPS_010ms_Group03_Reserved3 "EPS_010ms_Group03_Reserved3";
BA_ "CompuMethodName" SG_ 429 IEPS_10ms_Group01_CRC "EPS_10ms_Group01_CRC";
BA_ "ISignalName" SG_ 429 IEPS_10ms_Group01_CRC "IEPS_10ms_Group01_CRC";
BA_ "SysSignalName" SG_ 429 IEPS_10ms_Group01_CRC "EPS_10ms_Group01_CRC";
BA_ "CompuMethodName" SG_ 429 IEPS_10ms_Group01_RC "EPS_10ms_Group01_RC";
BA_ "ISignalName" SG_ 429 IEPS_10ms_Group01_RC "IEPS_10ms_Group01_RC";
BA_ "SysSignalName" SG_ 429 IEPS_10ms_Group01_RC "EPS_10ms_Group01_RC";
BA_ "CompuMethodName" SG_ 429 IActuRoadWhlAngV "ActuRoadWhlAngV";
BA_ "ISignalName" SG_ 429 IActuRoadWhlAngV "IActuRoadWhlAngV";
BA_ "LongName" SG_ 429 IActuRoadWhlAngV "Actual Road Wheel Angle Validity";
BA_ "SysSignalName" SG_ 429 IActuRoadWhlAngV "ActuRoadWhlAngV";
BA_ "CompuMethodName" SG_ 429 IADASStrgDlvrdToqV "ADASStrgDlvrdToqV";
BA_ "ISignalName" SG_ 429 IADASStrgDlvrdToqV "IADASStrgDlvrdToqV";
BA_ "LongName" SG_ 429 IADASStrgDlvrdToqV "Advanced Driver Assistance System Steering Delivered Torque Validity";
BA_ "SysSignalName" SG_ 429 IADASStrgDlvrdToqV "ADASStrgDlvrdToqV";
BA_ "CompuMethodName" SG_ 429 IEPSDrvngMdCtrlInh "EPSDrvngMdCtrlInh";
BA_ "GenSigStartValue" SG_ 429 IEPSDrvngMdCtrlInh 1;
BA_ "ISignalName" SG_ 429 IEPSDrvngMdCtrlInh "IEPSDrvngMdCtrlInh";
BA_ "LongName" SG_ 429 IEPSDrvngMdCtrlInh "Electric Power Steering Driving Mode Control Inhibit";
BA_ "SysSignalName" SG_ 429 IEPSDrvngMdCtrlInh "EPSDrvngMdCtrlInh";
BA_ "CompuMethodName" SG_ 429 IDrvrStrgDlvrdToqV "DrvrStrgDlvrdToqV";
BA_ "ISignalName" SG_ 429 IDrvrStrgDlvrdToqV "IDrvrStrgDlvrdToqV";
BA_ "LongName" SG_ 429 IDrvrStrgDlvrdToqV "Driver Steering Delivered Torque Validity";
BA_ "SysSignalName" SG_ 429 IDrvrStrgDlvrdToqV "DrvrStrgDlvrdToqV";
BA_ "CompuMethodName" SG_ 429 IActuPnonAng "ActuPnonAng";
BA_ "GenSigStartValue" SG_ 429 IActuPnonAng 32768;
BA_ "ISignalName" SG_ 429 IActuPnonAng "IActuPnonAng";
BA_ "LongName" SG_ 429 IActuPnonAng "Actual Pinion Angle";
BA_ "SysSignalName" SG_ 429 IActuPnonAng "ActuPnonAng";
BA_ "CompuMethodName" SG_ 429 IActuRoadWhlAng "ActuRoadWhlAng";
BA_ "GenSigStartValue" SG_ 429 IActuRoadWhlAng 32600;
BA_ "ISignalName" SG_ 429 IActuRoadWhlAng "IActuRoadWhlAng";
BA_ "LongName" SG_ 429 IActuRoadWhlAng "Actual Road Wheel Angle";
BA_ "SysSignalName" SG_ 429 IActuRoadWhlAng "ActuRoadWhlAng";
BA_ "CompuMethodName" SG_ 429 IStrgCustSetngDspCmd "StrgCustSetngDspCmd";
BA_ "ISignalName" SG_ 429 IStrgCustSetngDspCmd "IStrgCustSetngDspCmd";
BA_ "LongName" SG_ 429 IStrgCustSetngDspCmd "Steering Customization Setting Display Command";
BA_ "SysSignalName" SG_ 429 IStrgCustSetngDspCmd "StrgCustSetngDspCmd";
BA_ "CompuMethodName" SG_ 429 IEPSPriyChnlFlrSts "EPSPriyChnlFlrSts";
BA_ "ISignalName" SG_ 429 IEPSPriyChnlFlrSts "IEPSPriyChnlFlrSts";
BA_ "LongName" SG_ 429 IEPSPriyChnlFlrSts "Electric Power Steering Primary Channel Failure Status";
BA_ "SysSignalName" SG_ 429 IEPSPriyChnlFlrSts "EPSPriyChnlFlrSts";
BA_ "CompuMethodName" SG_ 429 IEPSFlrSts "EPSFlrSts";
BA_ "ISignalName" SG_ 429 IEPSFlrSts "IEPSFlrSts";
BA_ "LongName" SG_ 429 IEPSFlrSts "Electric Power Steering Failure Status";
BA_ "SysSignalName" SG_ 429 IEPSFlrSts "EPSFlrSts";
BA_ "CompuMethodName" SG_ 429 IEPSCurntDrvMd "EPSCurntDrvMd";
BA_ "ISignalName" SG_ 429 IEPSCurntDrvMd "IEPSCurntDrvMd";
BA_ "LongName" SG_ 429 IEPSCurntDrvMd "Eps Current Drive Mode";
BA_ "SysSignalName" SG_ 429 IEPSCurntDrvMd "EPSCurntDrvMd";
BA_ "CompuMethodName" SG_ 429 IActuPnonAngV "ActuPnonAngV";
BA_ "ISignalName" SG_ 429 IActuPnonAngV "IActuPnonAngV";
BA_ "LongName" SG_ 429 IActuPnonAngV "Actual Pinion Angle Validity";
BA_ "SysSignalName" SG_ 429 IActuPnonAngV "ActuPnonAngV";
BA_ "CompuMethodName" SG_ 429 IEPSToqValAldMaxV "EPSToqValAldMaxV";
BA_ "ISignalName" SG_ 429 IEPSToqValAldMaxV "IEPSToqValAldMaxV";
BA_ "LongName" SG_ 429 IEPSToqValAldMaxV "Electric Power Steering Torque Value Allowed Maximum Validity";
BA_ "SysSignalName" SG_ 429 IEPSToqValAldMaxV "EPSToqValAldMaxV";
BA_ "CompuMethodName" SG_ 429 IEPSLimMotToqV "EPSLimMotToqV";
BA_ "GenSigStartValue" SG_ 429 IEPSLimMotToqV 1;
BA_ "ISignalName" SG_ 429 IEPSLimMotToqV "IEPSLimMotToqV";
BA_ "LongName" SG_ 429 IEPSLimMotToqV "Electric_Power_Steering_Limited_Motor_Torque_Validity";
BA_ "SysSignalName" SG_ 429 IEPSLimMotToqV "EPSLimMotToqV";
BA_ "CompuMethodName" SG_ 429 IEPSActRetMotToqV "EPSActRetMotToqV";
BA_ "GenSigStartValue" SG_ 429 IEPSActRetMotToqV 1;
BA_ "ISignalName" SG_ 429 IEPSActRetMotToqV "IEPSActRetMotToqV";
BA_ "LongName" SG_ 429 IEPSActRetMotToqV "Electric_Power_Steering_Active_Return_Motor_Torque_Validity";
BA_ "SysSignalName" SG_ 429 IEPSActRetMotToqV "EPSActRetMotToqV";
BA_ "CompuMethodName" SG_ 429 IEPS_10ms_Group01_Reserved1 "EPS_10ms_Group01_Reserved1";
BA_ "GenSigStartValue" SG_ 429 IEPS_10ms_Group01_Reserved1 1;
BA_ "ISignalName" SG_ 429 IEPS_10ms_Group01_Reserved1 "IEPS_10ms_Group01_Reserved1";
BA_ "SysSignalName" SG_ 429 IEPS_10ms_Group01_Reserved1 "EPS_10ms_Group01_Reserved1";
BA_ "CompuMethodName" SG_ 429 IChLKAAngReqResp "ChLKAAngReqResp";
BA_ "ISignalName" SG_ 429 IChLKAAngReqResp "IChLKAAngReqResp";
BA_ "LongName" SG_ 429 IChLKAAngReqResp "Chassis Lane Keeping Assist Angle Request Response";
BA_ "SysSignalName" SG_ 429 IChLKAAngReqResp "ChLKAAngReqResp";
BA_ "CompuMethodName" SG_ 429 IEPS_10ms_Group01_Reserved2 "EPS_10ms_Group01_Reserved2";
BA_ "GenSigStartValue" SG_ 429 IEPS_10ms_Group01_Reserved2 15;
BA_ "ISignalName" SG_ 429 IEPS_10ms_Group01_Reserved2 "IEPS_10ms_Group01_Reserved2";
BA_ "SysSignalName" SG_ 429 IEPS_10ms_Group01_Reserved2 "EPS_10ms_Group01_Reserved2";
BA_ "CompuMethodName" SG_ 429 IEPSToqValAldMinV "EPSToqValAldMinV";
BA_ "ISignalName" SG_ 429 IEPSToqValAldMinV "IEPSToqValAldMinV";
BA_ "LongName" SG_ 429 IEPSToqValAldMinV "Electric Power Steering Torque Value Allowed Minimum Validity";
BA_ "SysSignalName" SG_ 429 IEPSToqValAldMinV "EPSToqValAldMinV";
BA_ "CompuMethodName" SG_ 429 ICHLKAHptResp "CHLKAHptResp";
BA_ "ISignalName" SG_ 429 ICHLKAHptResp "ICHLKAHptResp";
BA_ "LongName" SG_ 429 ICHLKAHptResp "Lane Keeping Assist Haptic Response";
BA_ "SysSignalName" SG_ 429 ICHLKAHptResp "CHLKAHptResp";
BA_ "CompuMethodName" SG_ 429 IEPS_10ms_Group01_Reserved3 "EPS_10ms_Group01_Reserved3";
BA_ "GenSigStartValue" SG_ 429 IEPS_10ms_Group01_Reserved3 255;
BA_ "ISignalName" SG_ 429 IEPS_10ms_Group01_Reserved3 "IEPS_10ms_Group01_Reserved3";
BA_ "SysSignalName" SG_ 429 IEPS_10ms_Group01_Reserved3 "EPS_10ms_Group01_Reserved3";
BA_ "CompuMethodName" SG_ 429 IADASStrgDlvrdToq "ADASStrgDlvrdToq";
BA_ "GenSigStartValue" SG_ 429 IADASStrgDlvrdToq 1024;
BA_ "ISignalName" SG_ 429 IADASStrgDlvrdToq "IADASStrgDlvrdToq";
BA_ "LongName" SG_ 429 IADASStrgDlvrdToq "Advanced Driver Assistance System Steering Delivered Torque";
BA_ "SysSignalName" SG_ 429 IADASStrgDlvrdToq "ADASStrgDlvrdToq";
BA_ "CompuMethodName" SG_ 429 IEPS_10ms_Group01_Reserved4 "EPS_10ms_Group01_Reserved4";
BA_ "GenSigStartValue" SG_ 429 IEPS_10ms_Group01_Reserved4 3;
BA_ "ISignalName" SG_ 429 IEPS_10ms_Group01_Reserved4 "IEPS_10ms_Group01_Reserved4";
BA_ "SysSignalName" SG_ 429 IEPS_10ms_Group01_Reserved4 "EPS_10ms_Group01_Reserved4";
BA_ "CompuMethodName" SG_ 429 IChLKAToqReqResp "ChLKAToqReqResp";
BA_ "ISignalName" SG_ 429 IChLKAToqReqResp "IChLKAToqReqResp";
BA_ "LongName" SG_ 429 IChLKAToqReqResp "Chassis Lane Keeping Assist Torque Request Response";
BA_ "SysSignalName" SG_ 429 IChLKAToqReqResp "ChLKAToqReqResp";
BA_ "CompuMethodName" SG_ 429 IEPSToqValAldMax "EPSToqValAldMax";
BA_ "GenSigStartValue" SG_ 429 IEPSToqValAldMax 1024;
BA_ "ISignalName" SG_ 429 IEPSToqValAldMax "IEPSToqValAldMax";
BA_ "LongName" SG_ 429 IEPSToqValAldMax "Electric Power Steering Torque Value Allowed Maximum";
BA_ "SysSignalName" SG_ 429 IEPSToqValAldMax "EPSToqValAldMax";
BA_ "CompuMethodName" SG_ 429 IEPSCoDrivingSts "EPSCoDrivingSts";
BA_ "GenSigStartValue" SG_ 429 IEPSCoDrivingSts 3;
BA_ "ISignalName" SG_ 429 IEPSCoDrivingSts "IEPSCoDrivingSts";
BA_ "LongName" SG_ 429 IEPSCoDrivingSts "Electric Power Steering Coperation Driving Status";
BA_ "SysSignalName" SG_ 429 IEPSCoDrivingSts "EPSCoDrivingSts";
BA_ "CompuMethodName" SG_ 429 IEPS_10ms_Group01_Reserved5 "EPS_10ms_Group01_Reserved5";
BA_ "GenSigStartValue" SG_ 429 IEPS_10ms_Group01_Reserved5 7;
BA_ "ISignalName" SG_ 429 IEPS_10ms_Group01_Reserved5 "IEPS_10ms_Group01_Reserved5";
BA_ "SysSignalName" SG_ 429 IEPS_10ms_Group01_Reserved5 "EPS_10ms_Group01_Reserved5";
BA_ "CompuMethodName" SG_ 429 IEPSToqValAldMin "EPSToqValAldMin";
BA_ "GenSigStartValue" SG_ 429 IEPSToqValAldMin 1024;
BA_ "ISignalName" SG_ 429 IEPSToqValAldMin "IEPSToqValAldMin";
BA_ "LongName" SG_ 429 IEPSToqValAldMin "Electric Power Steering Torque Value Allowed Minimum";
BA_ "SysSignalName" SG_ 429 IEPSToqValAldMin "EPSToqValAldMin";
BA_ "CompuMethodName" SG_ 429 IEPS_10ms_Group01_Reserved6 "EPS_10ms_Group01_Reserved6";
BA_ "GenSigStartValue" SG_ 429 IEPS_10ms_Group01_Reserved6 31;
BA_ "ISignalName" SG_ 429 IEPS_10ms_Group01_Reserved6 "IEPS_10ms_Group01_Reserved6";
BA_ "SysSignalName" SG_ 429 IEPS_10ms_Group01_Reserved6 "EPS_10ms_Group01_Reserved6";
BA_ "CompuMethodName" SG_ 429 IEPSActRetMotToq "EPSActRetMotToq";
BA_ "ISignalName" SG_ 429 IEPSActRetMotToq "IEPSActRetMotToq";
BA_ "LongName" SG_ 429 IEPSActRetMotToq "Electric_Power_Steering_Active_Return_Motor_Torque";
BA_ "SysSignalName" SG_ 429 IEPSActRetMotToq "EPSActRetMotToq";
BA_ "CompuMethodName" SG_ 429 IEPS_10ms_Group01_Reserved9 "EPS_10ms_Group01_Reserved9";
BA_ "GenSigStartValue" SG_ 429 IEPS_10ms_Group01_Reserved9 255;
BA_ "ISignalName" SG_ 429 IEPS_10ms_Group01_Reserved9 "IEPS_10ms_Group01_Reserved9";
BA_ "SysSignalName" SG_ 429 IEPS_10ms_Group01_Reserved9 "EPS_10ms_Group01_Reserved9";
BA_ "CompuMethodName" SG_ 429 IDrvrStrgDlvrdToq "DrvrStrgDlvrdToq";
BA_ "GenSigStartValue" SG_ 429 IDrvrStrgDlvrdToq 2048;
BA_ "ISignalName" SG_ 429 IDrvrStrgDlvrdToq "IDrvrStrgDlvrdToq";
BA_ "LongName" SG_ 429 IDrvrStrgDlvrdToq "Driver Steering Delivered Torque";
BA_ "SysSignalName" SG_ 429 IDrvrStrgDlvrdToq "DrvrStrgDlvrdToq";
BA_ "CompuMethodName" SG_ 429 IEPS_10ms_Group01_Reserved10 "EPS_10ms_Group01_Reserved10";
BA_ "GenSigStartValue" SG_ 429 IEPS_10ms_Group01_Reserved10 15;
BA_ "ISignalName" SG_ 429 IEPS_10ms_Group01_Reserved10 "IEPS_10ms_Group01_Reserved10";
BA_ "SysSignalName" SG_ 429 IEPS_10ms_Group01_Reserved10 "EPS_10ms_Group01_Reserved10";
BA_ "CompuMethodName" SG_ 429 IEPS_10ms_Group01_Reserved11 "EPS_10ms_Group01_Reserved11";
BA_ "GenSigStartValue" SG_ 429 IEPS_10ms_Group01_Reserved11 255;
BA_ "ISignalName" SG_ 429 IEPS_10ms_Group01_Reserved11 "IEPS_10ms_Group01_Reserved11";
BA_ "SysSignalName" SG_ 429 IEPS_10ms_Group01_Reserved11 "EPS_10ms_Group01_Reserved11";
BA_ "CompuMethodName" SG_ 429 IEPSLimMotToq "EPSLimMotToq";
BA_ "ISignalName" SG_ 429 IEPSLimMotToq "IEPSLimMotToq";
BA_ "LongName" SG_ 429 IEPSLimMotToq "Electric_Power_Steering_Limited_Motor_Torque";
BA_ "SysSignalName" SG_ 429 IEPSLimMotToq "EPSLimMotToq";
BA_ "CompuMethodName" SG_ 429 IEPS_10ms_Group02_CRC "EPS_10ms_Group02_CRC";
BA_ "ISignalName" SG_ 429 IEPS_10ms_Group02_CRC "IEPS_10ms_Group02_CRC";
BA_ "SysSignalName" SG_ 429 IEPS_10ms_Group02_CRC "EPS_10ms_Group02_CRC";
BA_ "CompuMethodName" SG_ 429 IEPS_10ms_Group02_RC "EPS_10ms_Group02_RC";
BA_ "ISignalName" SG_ 429 IEPS_10ms_Group02_RC "IEPS_10ms_Group02_RC";
BA_ "SysSignalName" SG_ 429 IEPS_10ms_Group02_RC "EPS_10ms_Group02_RC";
BA_ "CompuMethodName" SG_ 429 IEPSAIPkgAngReqResp "EPSAIPkgAngReqResp";
BA_ "GenSigStartValue" SG_ 429 IEPSAIPkgAngReqResp 7;
BA_ "ISignalName" SG_ 429 IEPSAIPkgAngReqResp "IEPSAIPkgAngReqResp";
BA_ "LongName" SG_ 429 IEPSAIPkgAngReqResp "Electric Power Steering Ai Parking Angle Request Response";
BA_ "SysSignalName" SG_ 429 IEPSAIPkgAngReqResp "EPSAIPkgAngReqResp";
BA_ "CompuMethodName" SG_ 429 IEPSAIPkgAngReqRespInh "EPSAIPkgAngReqRespInh";
BA_ "ISignalName" SG_ 429 IEPSAIPkgAngReqRespInh "IEPSAIPkgAngReqRespInh";
BA_ "LongName" SG_ 429 IEPSAIPkgAngReqRespInh "Electric Power Steering Ai Parking Angle Request Response Inhibit Reason";
BA_ "SysSignalName" SG_ 429 IEPSAIPkgAngReqRespInh "EPSAIPkgAngReqRespInh";
BA_ "CompuMethodName" SG_ 429 IEPSAIPltAngRespStsInh "EPSAIPltAngRespStsInh";
BA_ "ISignalName" SG_ 429 IEPSAIPltAngRespStsInh "IEPSAIPltAngRespStsInh";
BA_ "LongName" SG_ 429 IEPSAIPltAngRespStsInh "Electric_Power_Steering_Ai_Pilot_Angle_Request_Response_Inhibit_Reason";
BA_ "SysSignalName" SG_ 429 IEPSAIPltAngRespStsInh "EPSAIPltAngRespStsInh";
BA_ "CompuMethodName" SG_ 429 IEPS_10ms_Group02_Reserved1 "EPS_10ms_Group02_Reserved1";
BA_ "GenSigStartValue" SG_ 429 IEPS_10ms_Group02_Reserved1 7;
BA_ "ISignalName" SG_ 429 IEPS_10ms_Group02_Reserved1 "IEPS_10ms_Group02_Reserved1";
BA_ "SysSignalName" SG_ 429 IEPS_10ms_Group02_Reserved1 "EPS_10ms_Group02_Reserved1";
BA_ "CompuMethodName" SG_ 429 IEPSAIPltAvlLvl "EPSAIPltAvlLvl";
BA_ "ISignalName" SG_ 429 IEPSAIPltAvlLvl "IEPSAIPltAvlLvl";
BA_ "LongName" SG_ 429 IEPSAIPltAvlLvl "Electric Power Steering Ai Pilot Availablity Level";
BA_ "SysSignalName" SG_ 429 IEPSAIPltAvlLvl "EPSAIPltAvlLvl";
BA_ "CompuMethodName" SG_ 429 IEPSAIPltAngRespSts "EPSAIPltAngRespSts";
BA_ "ISignalName" SG_ 429 IEPSAIPltAngRespSts "IEPSAIPltAngRespSts";
BA_ "LongName" SG_ 429 IEPSAIPltAngRespSts "Electric Power Steering Ai Pilot Angle Response Status";
BA_ "SysSignalName" SG_ 429 IEPSAIPltAngRespSts "EPSAIPltAngRespSts";
BA_ "CompuMethodName" SG_ 429 IActuRoadWhlAngGrdV "ActuRoadWhlAngGrdV";
BA_ "ISignalName" SG_ 429 IActuRoadWhlAngGrdV "IActuRoadWhlAngGrdV";
BA_ "LongName" SG_ 429 IActuRoadWhlAngGrdV "Actual Road Wheel Angle Gradient Validity";
BA_ "SysSignalName" SG_ 429 IActuRoadWhlAngGrdV "ActuRoadWhlAngGrdV";
BA_ "CompuMethodName" SG_ 429 IEPS_10ms_Group02_Reserved2 "EPS_10ms_Group02_Reserved2";
BA_ "GenSigStartValue" SG_ 429 IEPS_10ms_Group02_Reserved2 63;
BA_ "ISignalName" SG_ 429 IEPS_10ms_Group02_Reserved2 "IEPS_10ms_Group02_Reserved2";
BA_ "SysSignalName" SG_ 429 IEPS_10ms_Group02_Reserved2 "EPS_10ms_Group02_Reserved2";
BA_ "CompuMethodName" SG_ 429 IEPSAIPltCtrlChannel "EPSAIPltCtrlChannel";
BA_ "ISignalName" SG_ 429 IEPSAIPltCtrlChannel "IEPSAIPltCtrlChannel";
BA_ "LongName" SG_ 429 IEPSAIPltCtrlChannel "EPSAIPltCtrlChannel";
BA_ "SysSignalName" SG_ 429 IEPSAIPltCtrlChannel "EPSAIPltCtrlChannel";
BA_ "CompuMethodName" SG_ 429 IActuRoadWhlAngGrd "ActuRoadWhlAngGrd";
BA_ "GenSigStartValue" SG_ 429 IActuRoadWhlAngGrd 32600;
BA_ "ISignalName" SG_ 429 IActuRoadWhlAngGrd "IActuRoadWhlAngGrd";
BA_ "LongName" SG_ 429 IActuRoadWhlAngGrd "Actual Road Wheel Angle Gradient";
BA_ "SysSignalName" SG_ 429 IActuRoadWhlAngGrd "ActuRoadWhlAngGrd";
BA_ "CompuMethodName" SG_ 173 IEPS_10ms_Group05_CRC "EPS_10ms_Group05_CRC";
BA_ "ISignalName" SG_ 173 IEPS_10ms_Group05_CRC "IEPS_10ms_Group05_CRC";
BA_ "SysSignalName" SG_ 173 IEPS_10ms_Group05_CRC "EPS_10ms_Group05_CRC";
BA_ "CompuMethodName" SG_ 173 IEPS_10ms_Group05_RC "EPS_10ms_Group05_RC";
BA_ "ISignalName" SG_ 173 IEPS_10ms_Group05_RC "IEPS_10ms_Group05_RC";
BA_ "SysSignalName" SG_ 173 IEPS_10ms_Group05_RC "EPS_10ms_Group05_RC";
BA_ "CompuMethodName" SG_ 173 IStrgWhlAngSnsrFlt "StrgWhlAngSnsrFlt";
BA_ "ISignalName" SG_ 173 IStrgWhlAngSnsrFlt "IStrgWhlAngSnsrFlt";
BA_ "LongName" SG_ 173 IStrgWhlAngSnsrFlt "Steering Wheel Angle Sensor Fault";
BA_ "SysSignalName" SG_ 173 IStrgWhlAngSnsrFlt "StrgWhlAngSnsrFlt";
BA_ "CompuMethodName" SG_ 173 IStrgWhlAngV "StrgWhlAngV";
BA_ "ISignalName" SG_ 173 IStrgWhlAngV "IStrgWhlAngV";
BA_ "LongName" SG_ 173 IStrgWhlAngV "Steering Wheel Angle Validity";
BA_ "SysSignalName" SG_ 173 IStrgWhlAngV "StrgWhlAngV";
BA_ "CompuMethodName" SG_ 173 IStrgWhlAngSnsrMultCapb "StrgWhlAngSnsrMultCapb";
BA_ "ISignalName" SG_ 173 IStrgWhlAngSnsrMultCapb "IStrgWhlAngSnsrMultCapb";
BA_ "LongName" SG_ 173 IStrgWhlAngSnsrMultCapb "Steering Wheel Angle Sensor Multiturn Capable";
BA_ "SysSignalName" SG_ 173 IStrgWhlAngSnsrMultCapb "StrgWhlAngSnsrMultCapb";
BA_ "CompuMethodName" SG_ 173 IStrgWhlAngSnsrInid "StrgWhlAngSnsrInid";
BA_ "ISignalName" SG_ 173 IStrgWhlAngSnsrInid "IStrgWhlAngSnsrInid";
BA_ "LongName" SG_ 173 IStrgWhlAngSnsrInid "Steering Wheel Angle Sensor Initialized";
BA_ "SysSignalName" SG_ 173 IStrgWhlAngSnsrInid "StrgWhlAngSnsrInid";
BA_ "CompuMethodName" SG_ 173 IStrgWhlAng "StrgWhlAng";
BA_ "ISignalName" SG_ 173 IStrgWhlAng "IStrgWhlAng";
BA_ "LongName" SG_ 173 IStrgWhlAng "Steering Wheel Angle";
BA_ "SysSignalName" SG_ 173 IStrgWhlAng "StrgWhlAng";
BA_ "CompuMethodName" SG_ 173 IStrgWhlAngGrd "StrgWhlAngGrd";
BA_ "ISignalName" SG_ 173 IStrgWhlAngGrd "IStrgWhlAngGrd";
BA_ "LongName" SG_ 173 IStrgWhlAngGrd "Steering Wheel Angle Gradient";
BA_ "SysSignalName" SG_ 173 IStrgWhlAngGrd "StrgWhlAngGrd";
BA_ "CompuMethodName" SG_ 173 IEPS_10ms_Group05_Reserved1 "EPS_10ms_Group05_Reserved1";
BA_ "GenSigStartValue" SG_ 173 IEPS_10ms_Group05_Reserved1 3;
BA_ "ISignalName" SG_ 173 IEPS_10ms_Group05_Reserved1 "IEPS_10ms_Group05_Reserved1";
BA_ "SysSignalName" SG_ 173 IEPS_10ms_Group05_Reserved1 "EPS_10ms_Group05_Reserved1";
BA_ "CompuMethodName" SG_ 173 IStrgWhlAngSnsrCalSts "StrgWhlAngSnsrCalSts";
BA_ "ISignalName" SG_ 173 IStrgWhlAngSnsrCalSts "IStrgWhlAngSnsrCalSts";
BA_ "LongName" SG_ 173 IStrgWhlAngSnsrCalSts "Steering Wheel Angle Sensor Calibration Status";
BA_ "SysSignalName" SG_ 173 IStrgWhlAngSnsrCalSts "StrgWhlAngSnsrCalSts";
BA_ "CompuMethodName" SG_ 173 IEPS_10ms_Group05_Reserved2 "EPS_10ms_Group05_Reserved2";
BA_ "GenSigStartValue" SG_ 173 IEPS_10ms_Group05_Reserved2 255;
BA_ "ISignalName" SG_ 173 IEPS_10ms_Group05_Reserved2 "IEPS_10ms_Group05_Reserved2";
BA_ "SysSignalName" SG_ 173 IEPS_10ms_Group05_Reserved2 "EPS_10ms_Group05_Reserved2";
BA_ "CompuMethodName" SG_ 173 IEPS_10ms_Group05_Reserved3 "EPS_10ms_Group05_Reserved3";
BA_ "GenSigStartValue" SG_ 173 IEPS_10ms_Group05_Reserved3 255;
BA_ "ISignalName" SG_ 173 IEPS_10ms_Group05_Reserved3 "IEPS_10ms_Group05_Reserved3";
BA_ "SysSignalName" SG_ 173 IEPS_10ms_Group05_Reserved3 "EPS_10ms_Group05_Reserved3";
BA_ "CompuMethodName" SG_ 184 IIBS_10ms_Group04_CRC "IBS_10ms_Group04_CRC";
BA_ "ISignalName" SG_ 184 IIBS_10ms_Group04_CRC "IIBS_10ms_Group04_CRC";
BA_ "SysSignalName" SG_ 184 IIBS_10ms_Group04_CRC "IBS_10ms_Group04_CRC";
BA_ "CompuMethodName" SG_ 184 IIBS_10ms_Group04_RC "IBS_10ms_Group04_RC";
BA_ "ISignalName" SG_ 184 IIBS_10ms_Group04_RC "IIBS_10ms_Group04_RC";
BA_ "SysSignalName" SG_ 184 IIBS_10ms_Group04_RC "IBS_10ms_Group04_RC";
BA_ "CompuMethodName" SG_ 184 IIBS_10ms_Group04_Reserved1 "IBS_10ms_Group04_Reserved1";
BA_ "GenSigStartValue" SG_ 184 IIBS_10ms_Group04_Reserved1 15;
BA_ "ISignalName" SG_ 184 IIBS_10ms_Group04_Reserved1 "IIBS_10ms_Group04_Reserved1";
BA_ "SysSignalName" SG_ 184 IIBS_10ms_Group04_Reserved1 "IBS_10ms_Group04_Reserved1";
BA_ "CompuMethodName" SG_ 184 IBrkPdlPos "BrkPdlPos";
BA_ "ISignalName" SG_ 184 IBrkPdlPos "IBrkPdlPos";
BA_ "LongName" SG_ 184 IBrkPdlPos "Brake Pedal Position";
BA_ "SysSignalName" SG_ 184 IBrkPdlPos "BrkPdlPos";
BA_ "CompuMethodName" SG_ 184 IIBS_10ms_Group04_Reserved2 "IBS_10ms_Group04_Reserved2";
BA_ "GenSigStartValue" SG_ 184 IIBS_10ms_Group04_Reserved2 63;
BA_ "ISignalName" SG_ 184 IIBS_10ms_Group04_Reserved2 "IIBS_10ms_Group04_Reserved2";
BA_ "SysSignalName" SG_ 184 IIBS_10ms_Group04_Reserved2 "IBS_10ms_Group04_Reserved2";
BA_ "CompuMethodName" SG_ 184 IBrkSysBrkLghtsReqd "BrkSysBrkLghtsReqd";
BA_ "ISignalName" SG_ 184 IBrkSysBrkLghtsReqd "IBrkSysBrkLghtsReqd";
BA_ "LongName" SG_ 184 IBrkSysBrkLghtsReqd "Brake System Brake Lights Requested";
BA_ "SysSignalName" SG_ 184 IBrkSysBrkLghtsReqd "BrkSysBrkLghtsReqd";
BA_ "CompuMethodName" SG_ 184 IBrkPdlPosV "BrkPdlPosV";
BA_ "ISignalName" SG_ 184 IBrkPdlPosV "IBrkPdlPosV";
BA_ "LongName" SG_ 184 IBrkPdlPosV "Brake Pedal Position Validity";
BA_ "SysSignalName" SG_ 184 IBrkPdlPosV "BrkPdlPosV";
BA_ "CompuMethodName" SG_ 184 IIBS_10ms_Group04_Reserved3 "IBS_10ms_Group04_Reserved3";
BA_ "GenSigStartValue" SG_ 184 IIBS_10ms_Group04_Reserved3 255;
BA_ "ISignalName" SG_ 184 IIBS_10ms_Group04_Reserved3 "IIBS_10ms_Group04_Reserved3";
BA_ "SysSignalName" SG_ 184 IIBS_10ms_Group04_Reserved3 "IBS_10ms_Group04_Reserved3";
BA_ "CompuMethodName" SG_ 184 IIBS_10ms_Group04_Reserved4 "IBS_10ms_Group04_Reserved4";
BA_ "GenSigStartValue" SG_ 184 IIBS_10ms_Group04_Reserved4 255;
BA_ "ISignalName" SG_ 184 IIBS_10ms_Group04_Reserved4 "IIBS_10ms_Group04_Reserved4";
BA_ "SysSignalName" SG_ 184 IIBS_10ms_Group04_Reserved4 "IBS_10ms_Group04_Reserved4";
BA_ "CompuMethodName" SG_ 184 IIBS_10ms_Group04_Reserved5 "IBS_10ms_Group04_Reserved5";
BA_ "GenSigStartValue" SG_ 184 IIBS_10ms_Group04_Reserved5 255;
BA_ "ISignalName" SG_ 184 IIBS_10ms_Group04_Reserved5 "IIBS_10ms_Group04_Reserved5";
BA_ "SysSignalName" SG_ 184 IIBS_10ms_Group04_Reserved5 "IBS_10ms_Group04_Reserved5";
BA_ "CompuMethodName" SG_ 184 IIBS_10ms_Group04_Reserved6 "IBS_10ms_Group04_Reserved6";
BA_ "GenSigStartValue" SG_ 184 IIBS_10ms_Group04_Reserved6 255;
BA_ "ISignalName" SG_ 184 IIBS_10ms_Group04_Reserved6 "IIBS_10ms_Group04_Reserved6";
BA_ "SysSignalName" SG_ 184 IIBS_10ms_Group04_Reserved6 "IBS_10ms_Group04_Reserved6";
BA_ "CompuMethodName" SG_ 184 IActuOtptRodTrvlSts "ActuOtptRodTrvlSts";
BA_ "ISignalName" SG_ 184 IActuOtptRodTrvlSts "IActuOtptRodTrvlSts";
BA_ "SysSignalName" SG_ 184 IActuOtptRodTrvlSts "ActuOtptRodTrvlSts";
BA_ "CompuMethodName" SG_ 184 IActuOtptRodTrvl "ActuOtptRodTrvl";
BA_ "ISignalName" SG_ 184 IActuOtptRodTrvl "IActuOtptRodTrvl";
BA_ "SysSignalName" SG_ 184 IActuOtptRodTrvl "ActuOtptRodTrvl";
BA_ "CompuMethodName" SG_ 394 IIBS_20ms_Group10_CRC "IBS_20ms_Group10_CRC";
BA_ "ISignalName" SG_ 394 IIBS_20ms_Group10_CRC "IIBS_20ms_Group10_CRC";
BA_ "LongName" SG_ 394 IIBS_20ms_Group10_CRC "Brake Pedal Applied Cyclic Redundancy Check";
BA_ "SysSignalName" SG_ 394 IIBS_20ms_Group10_CRC "IBS_20ms_Group10_CRC";
BA_ "CompuMethodName" SG_ 394 IIBS_20ms_Group10_RC "IBS_20ms_Group10_RC";
BA_ "ISignalName" SG_ 394 IIBS_20ms_Group10_RC "IIBS_20ms_Group10_RC";
BA_ "LongName" SG_ 394 IIBS_20ms_Group10_RC "Brake Pedal Applied Rolling Count";
BA_ "SysSignalName" SG_ 394 IIBS_20ms_Group10_RC "IBS_20ms_Group10_RC";
BA_ "CompuMethodName" SG_ 394 IBrkPdlDrvrAppdPrsV "BrkPdlDrvrAppdPrsV";
BA_ "ISignalName" SG_ 394 IBrkPdlDrvrAppdPrsV "IBrkPdlDrvrAppdPrsV";
BA_ "LongName" SG_ 394 IBrkPdlDrvrAppdPrsV "Brake Pedal Driver Applied Pressure Validity";
BA_ "SysSignalName" SG_ 394 IBrkPdlDrvrAppdPrsV "BrkPdlDrvrAppdPrsV";
BA_ "CompuMethodName" SG_ 394 IBrkPdlDrvrAppdPrsDetV "BrkPdlDrvrAppdPrsDetV";
BA_ "ISignalName" SG_ 394 IBrkPdlDrvrAppdPrsDetV "IBrkPdlDrvrAppdPrsDetV";
BA_ "LongName" SG_ 394 IBrkPdlDrvrAppdPrsDetV "Brake_Pedal_Driver_Applied_Pressure_Detected_Validity";
BA_ "SysSignalName" SG_ 394 IBrkPdlDrvrAppdPrsDetV "BrkPdlDrvrAppdPrsDetV";
BA_ "CompuMethodName" SG_ 394 IBrkPdlDrvrAppdPrsDet "BrkPdlDrvrAppdPrsDet";
BA_ "ISignalName" SG_ 394 IBrkPdlDrvrAppdPrsDet "IBrkPdlDrvrAppdPrsDet";
BA_ "LongName" SG_ 394 IBrkPdlDrvrAppdPrsDet "Brake_Pedal_Driver_Applied_Pressure_Detected";
BA_ "SysSignalName" SG_ 394 IBrkPdlDrvrAppdPrsDet "BrkPdlDrvrAppdPrsDet";
BA_ "CompuMethodName" SG_ 394 IBrkDiscTemSts "BrkDiscTemSts";
BA_ "ISignalName" SG_ 394 IBrkDiscTemSts "IBrkDiscTemSts";
BA_ "LongName" SG_ 394 IBrkDiscTemSts "Brake Disc Temperature Status";
BA_ "SysSignalName" SG_ 394 IBrkDiscTemSts "BrkDiscTemSts";
BA_ "CompuMethodName" SG_ 394 IBrkPdlDrvrAppdPrs "BrkPdlDrvrAppdPrs";
BA_ "ISignalName" SG_ 394 IBrkPdlDrvrAppdPrs "IBrkPdlDrvrAppdPrs";
BA_ "LongName" SG_ 394 IBrkPdlDrvrAppdPrs "Brake Pedal Driver Applied Pressure";
BA_ "SysSignalName" SG_ 394 IBrkPdlDrvrAppdPrs "BrkPdlDrvrAppdPrs";
BA_ "CompuMethodName" SG_ 394 IBrkPdlMdlSts "BrkPdlMdlSts";
BA_ "ISignalName" SG_ 394 IBrkPdlMdlSts "IBrkPdlMdlSts";
BA_ "LongName" SG_ 394 IBrkPdlMdlSts "Brake Pedal Model Status";
BA_ "SysSignalName" SG_ 394 IBrkPdlMdlSts "BrkPdlMdlSts";
BA_ "CompuMethodName" SG_ 394 IDrvrReqOtptRodTrvlSts "DrvrReqOtptRodTrvlSts";
BA_ "ISignalName" SG_ 394 IDrvrReqOtptRodTrvlSts "IDrvrReqOtptRodTrvlSts";
BA_ "LongName" SG_ 394 IDrvrReqOtptRodTrvlSts "Driver Request Output Rod Travel Status";
BA_ "SysSignalName" SG_ 394 IDrvrReqOtptRodTrvlSts "DrvrReqOtptRodTrvlSts";
BA_ "CompuMethodName" SG_ 394 IBrkPdlSimltdPrsV "BrkPdlSimltdPrsV";
BA_ "ISignalName" SG_ 394 IBrkPdlSimltdPrsV "IBrkPdlSimltdPrsV";
BA_ "LongName" SG_ 394 IBrkPdlSimltdPrsV "Brake Pedal Simulated Pressure Validity";
BA_ "SysSignalName" SG_ 394 IBrkPdlSimltdPrsV "BrkPdlSimltdPrsV";
BA_ "CompuMethodName" SG_ 394 IBrkPdlAppd "BrkPdlAppd";
BA_ "ISignalName" SG_ 394 IBrkPdlAppd "IBrkPdlAppd";
BA_ "LongName" SG_ 394 IBrkPdlAppd "Brake Pedal Applied";
BA_ "SysSignalName" SG_ 394 IBrkPdlAppd "BrkPdlAppd";
BA_ "CompuMethodName" SG_ 394 IBrkPdlAppdV "BrkPdlAppdV";
BA_ "ISignalName" SG_ 394 IBrkPdlAppdV "IBrkPdlAppdV";
BA_ "LongName" SG_ 394 IBrkPdlAppdV "Brake Pedal Applied Validity";
BA_ "SysSignalName" SG_ 394 IBrkPdlAppdV "BrkPdlAppdV";
BA_ "CompuMethodName" SG_ 394 IBrkPdlSimltdPrs "BrkPdlSimltdPrs";
BA_ "ISignalName" SG_ 394 IBrkPdlSimltdPrs "IBrkPdlSimltdPrs";
BA_ "LongName" SG_ 394 IBrkPdlSimltdPrs "Brake Pedal Simulated Pressure";
BA_ "SysSignalName" SG_ 394 IBrkPdlSimltdPrs "BrkPdlSimltdPrs";
BA_ "CompuMethodName" SG_ 394 IBrkFludLvlLowV "BrkFludLvlLowV";
BA_ "ISignalName" SG_ 394 IBrkFludLvlLowV "IBrkFludLvlLowV";
BA_ "LongName" SG_ 394 IBrkFludLvlLowV "Brake Fluid Level Low Validity";
BA_ "SysSignalName" SG_ 394 IBrkFludLvlLowV "BrkFludLvlLowV";
BA_ "CompuMethodName" SG_ 394 IBrkFludLvlLow "BrkFludLvlLow";
BA_ "ISignalName" SG_ 394 IBrkFludLvlLow "IBrkFludLvlLow";
BA_ "LongName" SG_ 394 IBrkFludLvlLow "Brake Fluid Level Low";
BA_ "SysSignalName" SG_ 394 IBrkFludLvlLow "BrkFludLvlLow";
BA_ "CompuMethodName" SG_ 394 IBrkPdlMdlActSts "BrkPdlMdlActSts";
BA_ "ISignalName" SG_ 394 IBrkPdlMdlActSts "IBrkPdlMdlActSts";
BA_ "LongName" SG_ 394 IBrkPdlMdlActSts "Brake Pedal Model Actual Status";
BA_ "SysSignalName" SG_ 394 IBrkPdlMdlActSts "BrkPdlMdlActSts";
BA_ "CompuMethodName" SG_ 394 IIBS_20ms_Group10_Reserved1 "IBS_20ms_Group10_Reserved1";
BA_ "GenSigStartValue" SG_ 394 IIBS_20ms_Group10_Reserved1 15;
BA_ "ISignalName" SG_ 394 IIBS_20ms_Group10_Reserved1 "IIBS_20ms_Group10_Reserved1";
BA_ "SysSignalName" SG_ 394 IIBS_20ms_Group10_Reserved1 "IBS_20ms_Group10_Reserved1";
BA_ "CompuMethodName" SG_ 394 IDrvrReqOtptRodTrvl "DrvrReqOtptRodTrvl";
BA_ "ISignalName" SG_ 394 IDrvrReqOtptRodTrvl "IDrvrReqOtptRodTrvl";
BA_ "LongName" SG_ 394 IDrvrReqOtptRodTrvl "Driver Request Output Rod Travel";
BA_ "SysSignalName" SG_ 394 IDrvrReqOtptRodTrvl "DrvrReqOtptRodTrvl";
BA_ "CompuMethodName" SG_ 394 IIBS_20ms_Group10_Reserved2 "IBS_20ms_Group10_Reserved2";
BA_ "GenSigStartValue" SG_ 394 IIBS_20ms_Group10_Reserved2 15;
BA_ "ISignalName" SG_ 394 IIBS_20ms_Group10_Reserved2 "IIBS_20ms_Group10_Reserved2";
BA_ "SysSignalName" SG_ 394 IIBS_20ms_Group10_Reserved2 "IBS_20ms_Group10_Reserved2";
BA_ "CompuMethodName" SG_ 394 IIBS_20ms_Group13_CRC "IBS_20ms_Group13_CRC";
BA_ "ISignalName" SG_ 394 IIBS_20ms_Group13_CRC "IIBS_20ms_Group13_CRC";
BA_ "LongName" SG_ 394 IIBS_20ms_Group13_CRC "Stability Control System Advanced Park Assist Acceleration Active Checksum";
BA_ "SysSignalName" SG_ 394 IIBS_20ms_Group13_CRC "IBS_20ms_Group13_CRC";
BA_ "CompuMethodName" SG_ 394 IIBS_20ms_Group13_RC "IBS_20ms_Group13_RC";
BA_ "ISignalName" SG_ 394 IIBS_20ms_Group13_RC "IIBS_20ms_Group13_RC";
BA_ "LongName" SG_ 394 IIBS_20ms_Group13_RC "Stability Control System Advanced Park Assist Acceleration Active Rolling Count";
BA_ "SysSignalName" SG_ 394 IIBS_20ms_Group13_RC "IBS_20ms_Group13_RC";
BA_ "CompuMethodName" SG_ 394 IACCBrkngA "ACCBrkngA";
BA_ "ISignalName" SG_ 394 IACCBrkngA "IACCBrkngA";
BA_ "LongName" SG_ 394 IACCBrkngA "Adaptive Cruise Control Braking Active";
BA_ "SysSignalName" SG_ 394 IACCBrkngA "ACCBrkngA";
BA_ "CompuMethodName" SG_ 394 IChAEBDclReqResp "ChAEBDclReqResp";
BA_ "ISignalName" SG_ 394 IChAEBDclReqResp "IChAEBDclReqResp";
BA_ "LongName" SG_ 394 IChAEBDclReqResp "Chassis Autonomous Emergency Braking Deceleration Request Response";
BA_ "SysSignalName" SG_ 394 IChAEBDclReqResp "ChAEBDclReqResp";
BA_ "CompuMethodName" SG_ 394 IChACCReqFlrSts "ChACCReqFlrSts";
BA_ "ISignalName" SG_ 394 IChACCReqFlrSts "IChACCReqFlrSts";
BA_ "LongName" SG_ 394 IChACCReqFlrSts "Chassis Adaptive Cruise Control Request Failure Status";
BA_ "SysSignalName" SG_ 394 IChACCReqFlrSts "ChACCReqFlrSts";
BA_ "CompuMethodName" SG_ 394 IChACCAccReqResp "ChACCAccReqResp";
BA_ "ISignalName" SG_ 394 IChACCAccReqResp "IChACCAccReqResp";
BA_ "LongName" SG_ 394 IChACCAccReqResp "Chassis Adaptive Cruise Control Acceleration Request Response";
BA_ "SysSignalName" SG_ 394 IChACCAccReqResp "ChACCAccReqResp";
BA_ "CompuMethodName" SG_ 394 IChAEBPrflReqResp "ChAEBPrflReqResp";
BA_ "ISignalName" SG_ 394 IChAEBPrflReqResp "IChAEBPrflReqResp";
BA_ "LongName" SG_ 394 IChAEBPrflReqResp "Chassis Autonomous Emergency Braking Prefill Request Response";
BA_ "SysSignalName" SG_ 394 IChAEBPrflReqResp "ChAEBPrflReqResp";
BA_ "CompuMethodName" SG_ 394 IAutodDrvngSysMdReqRespV "AutodDrvngSysMdReqRespV";
BA_ "ISignalName" SG_ 394 IAutodDrvngSysMdReqRespV "IAutodDrvngSysMdReqRespV";
BA_ "LongName" SG_ 394 IAutodDrvngSysMdReqRespV "Automated Driving System Mode Request Response Validity";
BA_ "SysSignalName" SG_ 394 IAutodDrvngSysMdReqRespV "AutodDrvngSysMdReqRespV";
BA_ "CompuMethodName" SG_ 394 IAutodDrvngSysMdReqResp "AutodDrvngSysMdReqResp";
BA_ "ISignalName" SG_ 394 IAutodDrvngSysMdReqResp "IAutodDrvngSysMdReqResp";
BA_ "LongName" SG_ 394 IAutodDrvngSysMdReqResp "Automated Driving System Mode Request Response";
BA_ "SysSignalName" SG_ 394 IAutodDrvngSysMdReqResp "AutodDrvngSysMdReqResp";
BA_ "CompuMethodName" SG_ 394 IChAEBHydBrkAstReqResp "ChAEBHydBrkAstReqResp";
BA_ "ISignalName" SG_ 394 IChAEBHydBrkAstReqResp "IChAEBHydBrkAstReqResp";
BA_ "LongName" SG_ 394 IChAEBHydBrkAstReqResp "Chassis Autonomous Emergency Braking Hydraulic Brake Assist Request Response";
BA_ "SysSignalName" SG_ 394 IChAEBHydBrkAstReqResp "ChAEBHydBrkAstReqResp";
BA_ "CompuMethodName" SG_ 394 IChAEBBrkJerkReqResp "ChAEBBrkJerkReqResp";
BA_ "ISignalName" SG_ 394 IChAEBBrkJerkReqResp "IChAEBBrkJerkReqResp";
BA_ "LongName" SG_ 394 IChAEBBrkJerkReqResp "Chassis Autonomous Emergency Braking Brake Jerk Request Response";
BA_ "SysSignalName" SG_ 394 IChAEBBrkJerkReqResp "ChAEBBrkJerkReqResp";
BA_ "CompuMethodName" SG_ 394 ISCSAutodDrvngSysSts "SCSAutodDrvngSysSts";
BA_ "ISignalName" SG_ 394 ISCSAutodDrvngSysSts "ISCSAutodDrvngSysSts";
BA_ "LongName" SG_ 394 ISCSAutodDrvngSysSts "Stability Control System Automated Driving System Status";
BA_ "SysSignalName" SG_ 394 ISCSAutodDrvngSysSts "SCSAutodDrvngSysSts";
BA_ "CompuMethodName" SG_ 394 ISCSAPAAcclAV "SCSAPAAcclAV";
BA_ "ISignalName" SG_ 394 ISCSAPAAcclAV "ISCSAPAAcclAV";
BA_ "LongName" SG_ 394 ISCSAPAAcclAV "Stability Control System Advanced Park Assist Acceleration Active Validity";
BA_ "SysSignalName" SG_ 394 ISCSAPAAcclAV "SCSAPAAcclAV";
BA_ "CompuMethodName" SG_ 394 ISCSAPAAcclA "SCSAPAAcclA";
BA_ "ISignalName" SG_ 394 ISCSAPAAcclA "ISCSAPAAcclA";
BA_ "LongName" SG_ 394 ISCSAPAAcclA "Stability Control System Advanced Park Assist Acceleration Active";
BA_ "SysSignalName" SG_ 394 ISCSAPAAcclA "SCSAPAAcclA";
BA_ "CompuMethodName" SG_ 394 IExtnlBrkPrioV "ExtnlBrkPrioV";
BA_ "ISignalName" SG_ 394 IExtnlBrkPrioV "IExtnlBrkPrioV";
BA_ "LongName" SG_ 394 IExtnlBrkPrioV "External Brake Priority Validity";
BA_ "SysSignalName" SG_ 394 IExtnlBrkPrioV "ExtnlBrkPrioV";
BA_ "CompuMethodName" SG_ 394 IExtnlBrkPrio "ExtnlBrkPrio";
BA_ "ISignalName" SG_ 394 IExtnlBrkPrio "IExtnlBrkPrio";
BA_ "LongName" SG_ 394 IExtnlBrkPrio "External Brake Priority";
BA_ "SysSignalName" SG_ 394 IExtnlBrkPrio "ExtnlBrkPrio";
BA_ "CompuMethodName" SG_ 394 IEmgcBrkReqdByIECUSts "EmgcBrkReqdByIECUSts";
BA_ "ISignalName" SG_ 394 IEmgcBrkReqdByIECUSts "IEmgcBrkReqdByIECUSts";
BA_ "LongName" SG_ 394 IEmgcBrkReqdByIECUSts "Emergency_Brake_Requested_By_Intelligent_Electric_Control_Unit_Status";
BA_ "SysSignalName" SG_ 394 IEmgcBrkReqdByIECUSts "EmgcBrkReqdByIECUSts";
BA_ "CompuMethodName" SG_ 394 ITCSDrvrItnt "TCSDrvrItnt";
BA_ "ISignalName" SG_ 394 ITCSDrvrItnt "ITCSDrvrItnt";
BA_ "LongName" SG_ 394 ITCSDrvrItnt "Traction_Control_System_Driver_Intent";
BA_ "SysSignalName" SG_ 394 ITCSDrvrItnt "TCSDrvrItnt";
BA_ "CompuMethodName" SG_ 394 IMultColBrkAvlblySts "MultColBrkAvlblySts";
BA_ "ISignalName" SG_ 394 IMultColBrkAvlblySts "IMultColBrkAvlblySts";
BA_ "LongName" SG_ 394 IMultColBrkAvlblySts "Multi_Collision_Brake_Availability_Status";
BA_ "SysSignalName" SG_ 394 IMultColBrkAvlblySts "MultColBrkAvlblySts";
BA_ "CompuMethodName" SG_ 394 IChRCTBDclReqResp "ChRCTBDclReqResp";
BA_ "ISignalName" SG_ 394 IChRCTBDclReqResp "IChRCTBDclReqResp";
BA_ "LongName" SG_ 394 IChRCTBDclReqResp "Chassis Rear Cross Traffic Braking Deceleration Request Response";
BA_ "SysSignalName" SG_ 394 IChRCTBDclReqResp "ChRCTBDclReqResp";
BA_ "CompuMethodName" SG_ 394 ISCSVehHoldAV "SCSVehHoldAV";
BA_ "ISignalName" SG_ 394 ISCSVehHoldAV "ISCSVehHoldAV";
BA_ "LongName" SG_ 394 ISCSVehHoldAV "Stability Control System Vehicle Hold A Validity";
BA_ "SysSignalName" SG_ 394 ISCSVehHoldAV "SCSVehHoldAV";
BA_ "CompuMethodName" SG_ 394 ISCSVehHoldA "SCSVehHoldA";
BA_ "ISignalName" SG_ 394 ISCSVehHoldA "ISCSVehHoldA";
BA_ "LongName" SG_ 394 ISCSVehHoldA "Stability Control System Vehicle Hold Active";
BA_ "SysSignalName" SG_ 394 ISCSVehHoldA "SCSVehHoldA";
BA_ "CompuMethodName" SG_ 394 ISCSAutodDrvngSysStsV "SCSAutodDrvngSysStsV";
BA_ "ISignalName" SG_ 394 ISCSAutodDrvngSysStsV "ISCSAutodDrvngSysStsV";
BA_ "LongName" SG_ 394 ISCSAutodDrvngSysStsV "Stability Control System Automated Driving System Status Validity";
BA_ "SysSignalName" SG_ 394 ISCSAutodDrvngSysStsV "SCSAutodDrvngSysStsV";
BA_ "CompuMethodName" SG_ 394 IVehSdslStsV "VehSdslStsV";
BA_ "ISignalName" SG_ 394 IVehSdslStsV "IVehSdslStsV";
BA_ "LongName" SG_ 394 IVehSdslStsV "Vehicle Standstill Status Valid";
BA_ "SysSignalName" SG_ 394 IVehSdslStsV "VehSdslStsV";
BA_ "CompuMethodName" SG_ 394 IChRCTBPrflReqResp "ChRCTBPrflReqResp";
BA_ "ISignalName" SG_ 394 IChRCTBPrflReqResp "IChRCTBPrflReqResp";
BA_ "LongName" SG_ 394 IChRCTBPrflReqResp "Chassis Rear Cross Traffic Braking Prefill Request Response";
BA_ "SysSignalName" SG_ 394 IChRCTBPrflReqResp "ChRCTBPrflReqResp";
BA_ "CompuMethodName" SG_ 394 IWhlBrkPrsSts "WhlBrkPrsSts";
BA_ "GenSigStartValue" SG_ 394 IWhlBrkPrsSts 1;
BA_ "ISignalName" SG_ 394 IWhlBrkPrsSts "IWhlBrkPrsSts";
BA_ "LongName" SG_ 394 IWhlBrkPrsSts "Wheel Brake Pressure Status";
BA_ "SysSignalName" SG_ 394 IWhlBrkPrsSts "WhlBrkPrsSts";
BA_ "CompuMethodName" SG_ 394 IBrkSysRddySysSts "BrkSysRddySysSts";
BA_ "ISignalName" SG_ 394 IBrkSysRddySysSts "IBrkSysRddySysSts";
BA_ "LongName" SG_ 394 IBrkSysRddySysSts "Brake Redundancy System Status";
BA_ "SysSignalName" SG_ 394 IBrkSysRddySysSts "BrkSysRddySysSts";
BA_ "CompuMethodName" SG_ 394 IVehSdslSts "VehSdslSts";
BA_ "ISignalName" SG_ 394 IVehSdslSts "IVehSdslSts";
BA_ "LongName" SG_ 394 IVehSdslSts "Vehicle Standstill Status";
BA_ "SysSignalName" SG_ 394 IVehSdslSts "VehSdslSts";
BA_ "CompuMethodName" SG_ 394 IIBS_20ms_Group13_Reserved1 "IBS_20ms_Group13_Reserved1";
BA_ "GenSigStartValue" SG_ 394 IIBS_20ms_Group13_Reserved1 31;
BA_ "ISignalName" SG_ 394 IIBS_20ms_Group13_Reserved1 "IIBS_20ms_Group13_Reserved1";
BA_ "SysSignalName" SG_ 394 IIBS_20ms_Group13_Reserved1 "IBS_20ms_Group13_Reserved1";
BA_ "CompuMethodName" SG_ 394 IIBSAPASysFltSts "IBSAPASysFltSts";
BA_ "ISignalName" SG_ 394 IIBSAPASysFltSts "IIBSAPASysFltSts";
BA_ "LongName" SG_ 394 IIBSAPASysFltSts "Ibs Apa System Fault Status";
BA_ "SysSignalName" SG_ 394 IIBSAPASysFltSts "IBSAPASysFltSts";
BA_ "CompuMethodName" SG_ 222 IICBAD_10ms_Group01_CRC "ICBAD_10ms_Group01_CRC";
BA_ "ISignalName" SG_ 222 IICBAD_10ms_Group01_CRC "IICBAD_10ms_Group01_CRC";
BA_ "SysSignalName" SG_ 222 IICBAD_10ms_Group01_CRC "ICBAD_10ms_Group01_CRC";
BA_ "CompuMethodName" SG_ 222 IICBAD_10ms_Group01_RC "ICBAD_10ms_Group01_RC";
BA_ "ISignalName" SG_ 222 IICBAD_10ms_Group01_RC "IICBAD_10ms_Group01_RC";
BA_ "SysSignalName" SG_ 222 IICBAD_10ms_Group01_RC "ICBAD_10ms_Group01_RC";
BA_ "CompuMethodName" SG_ 222 IICBAD_10ms_Group01_Reserved1 "ICBAD_10ms_Group01_Reserved1";
BA_ "GenSigStartValue" SG_ 222 IICBAD_10ms_Group01_Reserved1 7;
BA_ "ISignalName" SG_ 222 IICBAD_10ms_Group01_Reserved1 "IICBAD_10ms_Group01_Reserved1";
BA_ "SysSignalName" SG_ 222 IICBAD_10ms_Group01_Reserved1 "ICBAD_10ms_Group01_Reserved1";
BA_ "CompuMethodName" SG_ 222 IAIPltEPSReqRdWhlAngV "AIPltEPSReqRdWhlAngV";
BA_ "ISignalName" SG_ 222 IAIPltEPSReqRdWhlAngV "IAIPltEPSReqRdWhlAngV";
BA_ "LongName" SG_ 222 IAIPltEPSReqRdWhlAngV "Ai Pilot Electric Power Steering Request Road Wheel Angle Validity";
BA_ "SysSignalName" SG_ 222 IAIPltEPSReqRdWhlAngV "AIPltEPSReqRdWhlAngV";
BA_ "CompuMethodName" SG_ 222 IPltEPSRdWhlAngReqStsV "PltEPSRdWhlAngReqStsV";
BA_ "ISignalName" SG_ 222 IPltEPSRdWhlAngReqStsV "IPltEPSRdWhlAngReqStsV";
BA_ "LongName" SG_ 222 IPltEPSRdWhlAngReqStsV "Pilot Electric Power Steering Road Wheel Angle Request Status Valid";
BA_ "SysSignalName" SG_ 222 IPltEPSRdWhlAngReqStsV "PltEPSRdWhlAngReqStsV";
BA_ "CompuMethodName" SG_ 222 IPltEPSRdWhlAngReqSts "PltEPSRdWhlAngReqSts";
BA_ "ISignalName" SG_ 222 IPltEPSRdWhlAngReqSts "IPltEPSRdWhlAngReqSts";
BA_ "LongName" SG_ 222 IPltEPSRdWhlAngReqSts "Pilot Electric Power Steering Road Wheel Angle Request Status";
BA_ "SysSignalName" SG_ 222 IPltEPSRdWhlAngReqSts "PltEPSRdWhlAngReqSts";
BA_ "CompuMethodName" SG_ 222 IICBAD_10ms_Group01_Reserved2 "ICBAD_10ms_Group01_Reserved2";
BA_ "GenSigStartValue" SG_ 222 IICBAD_10ms_Group01_Reserved2 15;
BA_ "ISignalName" SG_ 222 IICBAD_10ms_Group01_Reserved2 "IICBAD_10ms_Group01_Reserved2";
BA_ "SysSignalName" SG_ 222 IICBAD_10ms_Group01_Reserved2 "ICBAD_10ms_Group01_Reserved2";
BA_ "CompuMethodName" SG_ 222 IICBAD_10ms_Group01_Reserved3 "ICBAD_10ms_Group01_Reserved3";
BA_ "GenSigStartValue" SG_ 222 IICBAD_10ms_Group01_Reserved3 255;
BA_ "ISignalName" SG_ 222 IICBAD_10ms_Group01_Reserved3 "IICBAD_10ms_Group01_Reserved3";
BA_ "SysSignalName" SG_ 222 IICBAD_10ms_Group01_Reserved3 "ICBAD_10ms_Group01_Reserved3";
BA_ "CompuMethodName" SG_ 222 IICBAD_10ms_Group01_Reserved4 "ICBAD_10ms_Group01_Reserved4";
BA_ "GenSigStartValue" SG_ 222 IICBAD_10ms_Group01_Reserved4 255;
BA_ "ISignalName" SG_ 222 IICBAD_10ms_Group01_Reserved4 "IICBAD_10ms_Group01_Reserved4";
BA_ "SysSignalName" SG_ 222 IICBAD_10ms_Group01_Reserved4 "ICBAD_10ms_Group01_Reserved4";
BA_ "CompuMethodName" SG_ 222 IAIPltEPSReqRdWhlAng "AIPltEPSReqRdWhlAng";
BA_ "GenSigStartValue" SG_ 222 IAIPltEPSReqRdWhlAng 32600;
BA_ "ISignalName" SG_ 222 IAIPltEPSReqRdWhlAng "IAIPltEPSReqRdWhlAng";
BA_ "LongName" SG_ 222 IAIPltEPSReqRdWhlAng "Ai Pilot Electric Power Steering Request Road Wheel Angle";
BA_ "SysSignalName" SG_ 222 IAIPltEPSReqRdWhlAng "AIPltEPSReqRdWhlAng";
BA_ "CompuMethodName" SG_ 222 IICBAD_10ms_Group01_Reserved5 "ICBAD_10ms_Group01_Reserved5";
BA_ "GenSigStartValue" SG_ 222 IICBAD_10ms_Group01_Reserved5 1;
BA_ "ISignalName" SG_ 222 IICBAD_10ms_Group01_Reserved5 "IICBAD_10ms_Group01_Reserved5";
BA_ "SysSignalName" SG_ 222 IICBAD_10ms_Group01_Reserved5 "ICBAD_10ms_Group01_Reserved5";
BA_ "CompuMethodName" SG_ 222 IEPSToqAppdCoefnt "EPSToqAppdCoefnt";
BA_ "ISignalName" SG_ 222 IEPSToqAppdCoefnt "IEPSToqAppdCoefnt";
BA_ "LongName" SG_ 222 IEPSToqAppdCoefnt "Electric Power Steering Torque Applied Coefficient";
BA_ "SysSignalName" SG_ 222 IEPSToqAppdCoefnt "EPSToqAppdCoefnt";
VAL_ 688 IIMCUtoIPD_Rsrv01 0 "IMCUtoIPD_Rsrv01_0_Reserved" 1 "IMCUtoIPD_Rsrv01_1_Reserved" 2 "IMCUtoIPD_Rsrv01_2_Reserved" 3 "IMCUtoIPD_Rsrv01_3_Reserved";
VAL_ 688 IIMCUtoIPD_Rsrv02 0 "IMCUtoIPD_Rsrv01_0_Reserved" 1 "IMCUtoIPD_Rsrv01_1_Reserved" 2 "IMCUtoIPD_Rsrv01_2_Reserved" 3 "IMCUtoIPD_Rsrv01_3_Reserved";
VAL_ 688 IIMCUtoIPD_Rsrv03 0 "IMCUtoIPD_Rsrv01_0_Reserved" 1 "IMCUtoIPD_Rsrv01_1_Reserved" 2 "IMCUtoIPD_Rsrv01_2_Reserved" 3 "IMCUtoIPD_Rsrv01_3_Reserved";
VAL_ 337 IAutoLaneChngRLaneSts 0 "AutoLaneChngRLaneSts_0_NoRequest" 1 "AutoLaneChngRLaneSts_1_LaneChangeInhibit" 2 "AutoLaneChngRLaneSts_2_WaitingForLaneChangeStarting" 3 "AutoLaneChngRLaneSts_3_LaneChangeInProgress" 4 "AutoLaneChngRLaneSts_4_LaneChangeSucces" 5 "AutoLaneChngRLaneSts_5_LaneChangeFailed" 6 "AutoLaneChngRLaneSts_6_LaneChangeSuppressByDriver" 7 "AutoLaneChngRLaneSts_7_ReturnToEgoLaneByDriver" 8 "AutoLaneChngRLaneSts_8_ReturnToEgoLaneByAlc" 9 "AutoLaneChngRLaneSts_9_LaneChangeManoeuvreWithRisk" 10 "AutoLaneChngRLaneSts_10_ReturnToEgoLaneSuccess" 11 "AutoLaneChngRLaneSts_11_Waiting_For_ALC_Because_Vehicle_Speed_Too_Low" 12 "AutoLaneChngRLaneSts_12_Waiting_For_ALC_Because_Vehicle_Speed_Too_High" 13 "AutoLaneChngRLaneSts_13_Vehicle_go_through_the_lane";
VAL_ 337 IESSDirInd 0 "ESSDirInd_0_Unactive" 1 "ESSDirInd_1_Left" 2 "ESSDirInd_2_Right" 3 "ESSDirInd_3_reserved";
VAL_ 337 IPilotTkovMsgReq 0 "PilotTkovMsgReq_0_NoDisplay" 1 "PilotTkovMsgReq_1__1" 2 "PilotTkovMsgReq_2__2" 3 "PilotTkovMsgReq_3__3" 4 "PilotTkovMsgReq_4__4" 5 "PilotTkovMsgReq_5__5" 6 "PilotTkovMsgReq_6__6" 7 "PilotTkovMsgReq_7__7" 8 "PilotTkovMsgReq_8__8" 9 "PilotTkovMsgReq_9__9" 10 "PilotTkovMsgReq_10__10" 11 "PilotTkovMsgReq_11__11" 12 "PilotTkovMsgReq_12__12" 13 "PilotTkovMsgReq_13__12" 14 "PilotTkovMsgReq_14__14" 15 "PilotTkovMsgReq_15__15";
VAL_ 337 INOPSysSts_ZPD 0 "NOPSysSts_ZPD_0_Off" 1 "NOPSysSts_ZPD_1_Passive" 2 "NOPSysSts_ZPD_2_Standby" 3 "NOPSysSts_ZPD_3_HandsOn_active" 4 "NOPSysSts_ZPD_4_HandsFree_active" 5 "NOPSysSts_ZPD_5_Wait_for_driver_to_confirm" 6 "NOPSysSts_ZPD_6_ALC_Active" 7 "NOPSysSts_ZPD_7_Override" 8 "NOPSysSts_ZPD_8_TOR" 9 "NOPSysSts_ZPD_9_Prohibit" 10 "NOPSysSts_ZPD_10_Fault" 11 "NOPSysSts_ZPD_11_SafeStop";
VAL_ 337 IPrkgDstCtrlSwResp 0 "PrkgDstCtrlSwResp_0_Unavailable" 1 "PrkgDstCtrlSwResp_1_ON" 2 "PrkgDstCtrlSwResp_2_OFF";
VAL_ 337 IALCSysSts 0 "ALCSysSts_0_Off" 1 "ALCSysSts_1_ALCSySSts_1_Stand_by" 2 "ALCSysSts_2_Active_Request" 3 "ALCSysSts_3_Active_Control" 4 "ALCSysSts_4_Passive" 5 "ALCSysSts_5_Lane_Change_Returning" 6 "ALCSysSts_6_TOR" 7 "ALCSysSts_7_Please_Turn_Off_Direction_Indication_Lamp_Switch";
VAL_ 337 IALCSysFltSts 0 "ALCSysFltSts_0_No_error" 1 "ALCSysFltSts_1_Performance_degradation" 2 "ALCSysFltSts_2_System_temporary_unavailable" 3 "ALCSysFltSts_3_Service_required" 4 "ALCSysFltSts_4_Reserved";
VAL_ 337 IAutoLaneChngLLaneSts 0 "AutoLaneChngLLaneSts_0_NoRequest" 1 "AutoLaneChngLLaneSts_1_LaneChangeInhibit" 2 "AutoLaneChngLLaneSts_2_WaitingForLaneChangeStarting" 3 "AutoLaneChngLLaneSts_3_LaneChangeInProgress" 4 "AutoLaneChngLLaneSts_4_LaneChangeSucces" 5 "AutoLaneChngLLaneSts_5_LaneChangeFailed" 6 "AutoLaneChngLLaneSts_6_LaneChangeSuppressByDriver" 7 "AutoLaneChngLLaneSts_7_ReturnToEgoLaneByDriver" 8 "AutoLaneChngLLaneSts_8_ReturnToEgoLaneByAlc" 9 "AutoLaneChngLLaneSts_9_LaneChangeManoeuvreWithRisk" 10 "AutoLaneChngLLaneSts_10_ReturnToEgoLaneSuccess" 11 "AutoLaneChngRLaneSts_11_Waiting_For_ALC_Because_Vehicle_Speed_Too_Low" 12 "AutoLaneChngRLaneSts_12_Waiting_For_ALC_Because_Vehicle_Speed_Too_High" 13 "AutoLaneChngRLaneSts_13_Vehicle_go_through_the_lane";
VAL_ 337 IESSSysSts 0 "ESSSysSts_0_Off" 1 "ESSSysSts_1_StandBy" 2 "ESSSysSts_2_Passive" 3 "ESSSysSts_3_Active" 4 "ESSSysSts_4_Disable" 5 "ESSSysSts_5_reserved" 6 "ESSSysSts_6_reserved";
VAL_ 337 IESSSysFltSts 0 "ESSSysFltSts_0_NoError" 1 "ESSSysFltSts_1_PerformanceDegradation" 2 "ESSSysFltSts_2_SystemTemporaryUnvailable" 3 "ESSSysFltSts_3_ServiceRequired" 4 "ESSSysFltSts_4_Reserved" 5 "ESSSysFltSts_5_Reserved" 6 "ESSSysFltSts_6_Reserved" 7 "ESSSysFltSts_7_Reserved";
VAL_ 337 IESSDrvrTkovReq 0 "ESSDrvrTkovReq_0_False" 1 "ESSDrvrTkovReq_1_True";
VAL_ 337 ISLIFSysFltSts 0 "SLIFSysFltSts_0_NoError" 1 "SLIFSysFltSts_1_PerformanceDegradation" 2 "SLIFSysFltSts_2_SystemTemporaryUnavailable" 3 "SLIFSysFltSts_3_ServiceRequired";
VAL_ 337 IParkngslottype 0 "ParkngSlotType_0__null" 1 "ParkngSlotType_1_left_vertical" 2 "ParkngSlotType_2_left_parallel" 3 "ParkngSlotType_3_right_vertical" 4 "ParkngSlotType_4_right_parallel";
VAL_ 337 INOPSysFltSts 0 "NOPSysFltSts_0_No_error" 1 "NOPSysFltSts_1_Performance_degradation" 2 "NOPSysFltSts_2_System_temporary_unavailable" 3 "NOPSysFltSts_3_Service_required" 4 "NOPSysFltSts_4_Reserved";
VAL_ 590 IRoadProfileShockDetectedL1 0 "RoadProfileShockDetectedL1_0_NotDetected" 1 "RoadProfileShockDetectedL1_1_SpeedBump" 2 "RoadProfileShockDetectedL1_2_Manhole_cover" 3 "RoadProfileShockDetectedL1_3_reserved" 4 "RoadProfileShockDetectedL1_4_reserved" 5 "RoadProfileShockDetectedL1_5_reserved" 6 "RoadProfileShockDetectedL1_6_reserved" 7 "RoadProfileShockDetectedL1_7_reserved" 8 "RoadProfileShockDetectedL1_8_reserved" 9 "RoadProfileShockDetectedL1_9_reserved" 10 "RoadProfileShockDetectedL1_10_reserved" 11 "RoadProfileShockDetectedL1_11_reserved" 12 "RoadProfileShockDetectedL1_12_reserved" 13 "RoadProfileShockDetectedL1_13_reserved" 14 "RoadProfileShockDetectedL1_14_reserved" 15 "RoadProfileShockDetectedL1_15_reserved";
VAL_ 590 IRoadProfileShockDetectedL2 0 "RoadProfileShockDetectedL2_0_NotDetected" 1 "RoadProfileShockDetectedL2_1_SpeedBump" 2 "RoadProfileShockDetectedL2_2_Manhole_cover" 3 "RoadProfileShockDetectedL2_3_reserved" 4 "RoadProfileShockDetectedL2_4_reserved" 5 "RoadProfileShockDetectedL2_5_reserved" 6 "RoadProfileShockDetectedL2_6_reserved" 7 "RoadProfileShockDetectedL2_7_reserved" 8 "RoadProfileShockDetectedL2_8_reserved" 9 "RoadProfileShockDetectedL2_9_reserved" 10 "RoadProfileShockDetectedL2_10_reserved" 11 "RoadProfileShockDetectedL2_11_reserved" 12 "RoadProfileShockDetectedL2_12_reserved" 13 "RoadProfileShockDetectedL2_13_reserved" 14 "RoadProfileShockDetectedL2_14_reserved" 15 "RoadProfileShockDetectedL2_15_reserved";
VAL_ 590 IRoadProfileShockDetectedL3 0 "RoadProfileShockDetectedL3_0_NotDetected" 1 "RoadProfileShockDetectedL3_1_SpeedBump" 2 "RoadProfileShockDetectedL3_2_Manhole_cover" 3 "RoadProfileShockDetectedL3_3_reserved" 4 "RoadProfileShockDetectedL3_4_reserved" 5 "RoadProfileShockDetectedL3_5_reserved" 6 "RoadProfileShockDetectedL3_6_reserved" 7 "RoadProfileShockDetectedL3_7_reserved" 8 "RoadProfileShockDetectedL3_8_reserved" 9 "RoadProfileShockDetectedL3_9_reserved" 10 "RoadProfileShockDetectedL3_10_reserved" 11 "RoadProfileShockDetectedL3_11_reserved" 12 "RoadProfileShockDetectedL3_12_reserved" 13 "RoadProfileShockDetectedL3_13_reserved" 14 "RoadProfileShockDetectedL3_14_reserved" 15 "RoadProfileShockDetectedL3_15_reserved";
VAL_ 590 IPrvOutSts 0 "PrvOutSts_0_Disable" 1 "PrvOutSts_1_Normal" 2 "PrvOutSts_2_Passive" 3 "PrvOutSts_3_reserved";
VAL_ 590 IRoadProfileShockDetectedR1 0 "RoadProfileShockDetectedR1_0_NotDetected" 1 "RoadProfileShockDetectedR1_1_SpeedBump" 2 "RoadProfileShockDetectedR1_2_Manhole_cover" 3 "RoadProfileShockDetectedR1_3_reserved" 4 "RoadProfileShockDetectedR1_4_reserved" 5 "RoadProfileShockDetectedR1_5_reserved" 6 "RoadProfileShockDetectedR1_6_reserved" 7 "RoadProfileShockDetectedR1_7_reserved" 8 "RoadProfileShockDetectedR1_8_reserved" 9 "RoadProfileShockDetectedR1_9_reserved" 10 "RoadProfileShockDetectedR1_10_reserved" 11 "RoadProfileShockDetectedR1_11_reserved" 12 "RoadProfileShockDetectedR1_12_reserved" 13 "RoadProfileShockDetectedR1_13_reserved" 14 "RoadProfileShockDetectedR1_14_reserved" 15 "RoadProfileShockDetectedR1_15_reserved";
VAL_ 590 IRoadProfileShockDetectedR3 0 "RoadProfileShockDetectedR3_0_NotDetected" 1 "RoadProfileShockDetectedR3_1_SpeedBump" 2 "RoadProfileShockDetectedR3_2_Manhole_cover" 3 "RoadProfileShockDetectedR3_3_reserved" 4 "RoadProfileShockDetectedR3_4_reserved" 5 "RoadProfileShockDetectedR3_5_reserved" 6 "RoadProfileShockDetectedR3_6_reserved" 7 "RoadProfileShockDetectedR3_7_reserved" 8 "RoadProfileShockDetectedR3_8_reserved" 9 "RoadProfileShockDetectedR3_9_reserved" 10 "RoadProfileShockDetectedR3_10_reserved" 11 "RoadProfileShockDetectedR3_11_reserved" 12 "RoadProfileShockDetectedR3_12_reserved" 13 "RoadProfileShockDetectedR3_13_reserved" 14 "RoadProfileShockDetectedR3_14_reserved" 15 "RoadProfileShockDetectedR3_15_reserved";
VAL_ 590 IRoadProfileShockDetectedR2 0 "RoadProfileShockDetectedR2_0_NotDetected" 1 "RoadProfileShockDetectedR2_1_SpeedBump" 2 "RoadProfileShockDetectedR2_2_Manhole_cover" 3 "RoadProfileShockDetectedR2_3_reserved" 4 "RoadProfileShockDetectedR2_4_reserved" 5 "RoadProfileShockDetectedR2_5_reserved" 6 "RoadProfileShockDetectedR2_6_reserved" 7 "RoadProfileShockDetectedR2_7_reserved" 8 "RoadProfileShockDetectedR2_8_reserved" 9 "RoadProfileShockDetectedR2_9_reserved" 10 "RoadProfileShockDetectedR2_10_reserved" 11 "RoadProfileShockDetectedR2_11_reserved" 12 "RoadProfileShockDetectedR2_12_reserved" 13 "RoadProfileShockDetectedR2_13_reserved" 14 "RoadProfileShockDetectedR2_14_reserved" 15 "RoadProfileShockDetectedR2_15_reserved";
VAL_ 1202 IIPD_NM_BSMtoRMS_CHCANFD 0 "IPD_NM_BSMtoRMS_CHCANFD_0_False" 1 "IPD_NM_BSMtoRMS_CHCANFD_1_True";
VAL_ 1202 IIPD_NM_PBSMtoRMS_CHCANFD 0 "IPD_NM_PBSMtoRMS_CHCANFD_0_False" 1 "IPD_NM_PBSMtoRMS_CHCANFD_1_True";
VAL_ 1202 IIPD_NM_RMStoNOS_CHCANFD 0 "IPD_NM_RMStoNOS_CHCANFD_0_False" 1 "IPD_NM_RMStoNOS_CHCANFD_1_True";
VAL_ 1202 IIPD_NM_RSStoNOS_CHCANFD 0 "IPD_NM_RSStoNOS_CHCANFD_0_False" 1 "IPD_NM_RSStoNOS_CHCANFD_1_True";
VAL_ 1202 IIPD_NM_RSStoRMS_CHCANFD 0 "IPD_NM_RSStoRMS_CHCANFD_0_False" 1 "IPD_NM_RSStoRMS_CHCANFD_1_True";
VAL_ 1202 IIPD_NM_NOStoRMS_CHCANFD 0 "IPD_NM_NOStoRMS_CHCANFD_0_False" 1 "IPD_NM_NOStoRMS_CHCANFD_1_True";
VAL_ 1202 IIPD_NM_NOSSta_CHCANFD 0 "IPD_NM_NOSSta_CHCANFD_0_False" 1 "IPD_NM_NOSSta_CHCANFD_1_True";
VAL_ 1202 IIPD_NM_RMSSta_CHCANFD 0 "IPD_NM_RMSSta_CHCANFD_0_False" 1 "IPD_NM_RMSSta_CHCANFD_1_True";
VAL_ 1202 IIPD_NWI_CHCANFD 0 "IPD_NWI_CHCANFD_0_NoWakeNetworkSource" 1 "IPD_NWI_CHCANFD_1_PowerModeIsNonOFF" 2 "IPD_NWI_CHCANFD_2_OnboardChargerConnected";
VAL_ 1202 IIPD_NOI_CHCANFD 0 "IPD_NOI_CHCANFD_0_NoRequest" 65535 "IPD_NOI_CHCANFD_65535_AllNetworkOperationActive";
VAL_ 1202 IIPD_NKI_CHCANFD 0 "IPD_NKI_CHCANFD_0_NoRequest" 1 "IPD_NKI_CHCANFD_1_PowerModeIsNonOFF";
VAL_ 157 ISCUFltLvlWarn 0 "SCUFltLvlWarn_0_No_Fault" 1 "SCUFltLvlWarn_1_SCU_Limited_Fault" 2 "SCUFltLvlWarn_2_SCU_Critical_Fault" 3 "SCUFltLvlWarn_3_Transmission_Wrong_Gear_feedback";
VAL_ 157 ISCUDrvMd 0 "SCUDrvMd_0_Normal" 1 "SCUDrvMd_1_TT_Push_mode" 2 "SCUDrvMd_2_Reserved" 3 "SCUDrvMd_3_Reserved";
VAL_ 157 ISCUExtdShiftrFlr 0 "SCUExtdShiftrFlr_0_No_fail" 1 "SCUExtdShiftrFlr_1_Mode_selector_sensor_fail" 2 "SCUExtdShiftrFlr_2_Single_rotary_hall_sensor_fail" 3 "SCUExtdShiftrFlr_3_CAN_Bus_communication_fail" 4 "SCUExtdShiftrFlr_4_Single_P_button_sensor_fail" 5 "SCUExtdShiftrFlr_5_All_rotary_hall_sensor_fail" 6 "SCUExtdShiftrFlr_6_All_P_button_sensor_fail" 7 "SCUExtdShiftrFlr_7_SSU_fail" 8 "SCUExtdShiftrFlr_8_Single_Unlock_button_fail" 9 "SCUExtdShiftrFlr_9_All_unlock_button_fail" 10 "SCUExtdShiftrFlr_10_Single_SENT_sensor_fail" 11 "SCUExtdShiftrFlr_11_All_SENT_sensor_fail" 12 "SCUExtdShiftrFlr_12_Motor_Stuck" 13 "SCUExtdShiftrFlr_13_Motor_fail";
VAL_ 157 ISCUShiftrOpngRmndr 0 "SCUShiftrOpngRmndr_0_No_Reminder_Request" 1 "SCUShiftrOpngRmndr_1_Please_Press_The_Unlock_Button" 2 "SCUShiftrOpngRmndr_2_Please_Slam_On_The_Brake_Pedal" 3 "SCUShiftrOpngRmndr_3_Please_Press_The_Unlock_Button_And_Slam_On_The_Brake_Pedal" 4 "SCUShiftrOpngRmndr_4_Speed_Too_High_Go_Into_P_not_allowed" 5 "SCUShiftrOpngRmndr_5_Speed_Too_High_Go_Into_R_not_allowed" 6 "SCUShiftrOpngRmndr_6_Changer_On_Inhibit_Shift_Out_P" 7 "SCUShiftrOpngRmndr_7_Shift_The_Lever_To_Left_Postion" 8 "SCUShiftrOpngRmndr_8_EPTRdy_Failed_Inhibit_Shift_to_D_R" 9 "SCUShiftrOpngRmndr_9_Camp_Mode_Active_Inhibit_Shift_Out_P" 10 "SCUShiftrOpngRmndr_10_Exhibition_Active_Inhibit_Shift_Out_P" 11 "SCUShiftrOpngRmndr_11_Game_Mode_Active_Inhibit_Shift_Out_P";
VAL_ 157 IKeyAuthResp 0 "KeyAuthResp_0_PSNonValidKey" 1 "KeyAuthResp_1_PSValidKey";
VAL_ 157 ISCUParkLckReq 0 "SCUParkLckReq_0_No_Request" 1 "SCUParkLckReq_1_Release_Brake_Request" 2 "SCUParkLckReq_2_Apply_Brake_Request" 3 "SCUParkLckReq_3_Reserved";
VAL_ 157 ISCUParkLckReqV 0 "SCUParkLckReqV_0_Valid" 1 "SCUParkLckReqV_1_Invalid";
VAL_ 157 IDigKeyAuthReq 0 "DigKeyAuthReq_0_NoRequest" 1 "DigKeyAuthReq_1_Request";
VAL_ 157 ISCUShiftrLvrRawPosn 0 "SCUShiftrLvrRawPosn_0_Up2" 1 "SCUShiftrLvrRawPosn_1_Up1" 2 "SCUShiftrLvrRawPosn_2_Stable" 3 "SCUShiftrLvrRawPosn_3_Down1" 4 "SCUShiftrLvrRawPosn_4_Down2" 5 "SCUShiftrLvrRawPosn_5_P_touch" 6 "SCUShiftrLvrRawPosn_6_Error";
VAL_ 157 ISCUParkLckReqVEPMCU 0 "SCUParkLckReqVEPMCU_0_Valid" 1 "SCUParkLckReqVEPMCU_1_Invalid";
VAL_ 157 IScurtKeyInvd 0 "ScurtKeyInvd_0_False" 1 "ScurtKeyInvd_1_True";
VAL_ 157 ISCUParkLckReqEPMCU 0 "SCUParkLckReqEPMCU_0_No_Request" 1 "SCUParkLckReqEPMCU_1_Release_Brake_Request" 2 "SCUParkLckReqEPMCU_2_Apply_Brake_Request" 3 "SCUParkLckReqEPMCU_3_Reserved";
VAL_ 157 ISCUShiftrPosnInvsn 5 "SCUShiftrPosnInvsn_5_Error" 6 "SCUShiftrPosnInvsn_6_In_learn_process" 7 "SCUShiftrPosnInvsn_7_P_Park" 8 "SCUShiftrPosnInvsn_8_R_Reverse" 9 "SCUShiftrPosnInvsn_9_N_Neutral" 10 "SCUShiftrPosnInvsn_10_D_Drive" 12 "SCUShiftrPosnInvsn_12_M_Manual_mode" 13 "SCUShiftrPosnInvsn_13_W_Winter_mode" 14 "SCUShiftrPosnInvsn_14_S_Sport_mode" 15 "SCUShiftrPosnInvsn_15_SCU_initialization";
VAL_ 157 ISCUShiftrLvrPosn 0 "SCUShiftrLvrPosn_0_SCU_Initialization" 1 "SCUShiftrLvrPosn_1_S_Sport_Mode" 2 "SCUShiftrLvrPosn_2_W_Winter_Mode" 3 "SCUShiftrLvrPosn_3_M_Manual_Mode" 5 "SCUShiftrLvrPosn_5_D_Drive" 6 "SCUShiftrLvrPosn_6_N_Neutral" 7 "SCUShiftrLvrPosn_7_R_Reverse" 8 "SCUShiftrLvrPosn_8_P_Park" 9 "SCUShiftrLvrPosn_9_In_learn_Process" 10 "SCUShiftrLvrPosn_10_Error";
VAL_ 157 IDrvrReqParkBtn 0 "DrvrReqParkBtn_0_no_request" 1 "DrvrReqParkBtn_1_driver_request_park_button" 2 "DrvrReqParkBtn_2_Park_button_fault" 3 "DrvrReqParkBtn_3_reserved";
VAL_ 157 ISCUShiftrLvrPosnLtchActv 0 "SCUShiftrLvrPosnLtchActv_0_Inactive" 1 "SCUShiftrLvrPosnLtchActv_1_Active";
VAL_ 157 ISecuKeyVldSts 0 "SecuKeyVldSts_0_Valid" 1 "SecuKeyVldSts_1_Invalid";
VAL_ 157 ISCUDrvrIntrvnActv 0 "SCUDrvrIntrvnActv_0_Inactive" 1 "SCUDrvrIntrvnActv_1_Active";
VAL_ 157 ISCUAPAUnderCtrlActv 0 "SCUAPAUnderCtrlActv_0_Inhibit" 1 "SCUAPAUnderCtrlActv_1_Available_For_Control" 2 "SCUAPAUnderCtrlActv_2_Active_For_Control" 3 "SCUAPAUnderCtrlActv_3_Failed";
VAL_ 546 IHODdiagSts 0 "HODdiagSts_0_NoError" 1 "HODdiagSts_1_HODSystemTempError" 2 "HODdiagSts_2_ECUError" 3 "HODdiagSts_3_SteeringWheelError" 4 "HODdiagSts_4_SteeringWheelErrorandECUError" 5 "HODdiagSts_5_OvervoltageError" 6 "HODdiagSts_6_UndervoltageError";
VAL_ 546 IHODDetnSts 0 "HODDetnSts_0_Unknown" 1 "HODDetnSts_1_No_valid_contact_detected" 2 "HODDetnSts_2_Valid_contact_detected";
VAL_ 546 IHODTchZone1Sts 0 "HODTchZone1Sts_0_No_hand_detected" 1 "HODTchZone1Sts_1_Hand_detected" 2 "HODTchZone1Sts_2_Reserved" 3 "HODTchZone1Sts_3_Reserved" 4 "HODTchZone1Sts_4_Reserved" 5 "HODTchZone1Sts_5_Reserved" 6 "HODTchZone1Sts_6_Reserved" 7 "HODTchZone1Sts_7_Reserved";
VAL_ 546 IHODSysSts 0 "HODSysSts_0_Available" 1 "HODSysSts_1_Initial_Status" 2 "HODSysSts_2_Fault" 3 "HODSysSts_3_Reserved" 4 "HODSysSts_4_NotCalibration";
VAL_ 546 IHODTchZone3Sts 0 "HODTchZone3Sts_0_No_hand_detected" 1 "HODTchZone3Sts_1_Hand_detected" 2 "HODTchZone3Sts_2_Reserved" 3 "HODTchZone3Sts_3_Reserved" 4 "HODTchZone3Sts_4_Reserved" 5 "HODTchZone3Sts_5_Reserved" 6 "HODTchZone3Sts_6_Reserved" 7 "HODTchZone3Sts_7_Reserved";
VAL_ 546 IHODTchZone2Sts 0 "HODTchZone2Sts_0_No_hand_detected" 1 "HODTchZone2Sts_1_Hand_detected" 2 "HODTchZone2Sts_2_Reserved" 3 "HODTchZone2Sts_3_Reserved" 4 "HODTchZone2Sts_4_Reserved" 5 "HODTchZone2Sts_5_Reserved" 6 "HODTchZone2Sts_6_Reserved" 7 "HODTchZone2Sts_7_Reserved";
VAL_ 1267 IRZCU_NM_BSMtoRMS_CHCANFD 0 "RZCU_NM_BSMtoRMS_CHCANFD_0_False" 1 "RZCU_NM_BSMtoRMS_CHCANFD_1_True";
VAL_ 1267 IRZCU_NM_PBSMtoRMS_CHCANFD 0 "RZCU_NM_PBSMtoRMS_CHCANFD_0_False" 1 "RZCU_NM_PBSMtoRMS_CHCANFD_1_True";
VAL_ 1267 IRZCU_NM_RMStoNOS_CHCANFD 0 "RZCU_NM_RMStoNOS_CHCANFD_0_False" 1 "RZCU_NM_RMStoNOS_CHCANFD_1_True";
VAL_ 1267 IRZCU_NM_RSStoNOS_CHCANFD 0 "RZCU_NM_RSStoNOS_CHCANFD_0_False" 1 "RZCU_NM_RSStoNOS_CHCANFD_1_True";
VAL_ 1267 IRZCU_NM_RSStoRMS_CHCANFD 0 "RZCU_NM_RSStoRMS_CHCANFD_0_False" 1 "RZCU_NM_RSStoRMS_CHCANFD_1_True";
VAL_ 1267 IRZCU_NM_NOStoRMS_CHCANFD 0 "RZCU_NM_NOStoRMS_CHCANFD_0_False" 1 "RZCU_NM_NOStoRMS_CHCANFD_1_True";
VAL_ 1267 IRZCU_NM_NOSSta_CHCANFD 0 "RZCU_NM_NOSSta_CHCANFD_0_False" 1 "RZCU_NM_NOSSta_CHCANFD_1_True";
VAL_ 1267 IRZCU_NM_RMSSta_CHCANFD 0 "RZCU_NM_RMSSta_CHCANFD_0_False" 1 "RZCU_NM_RMSSta_CHCANFD_1_True";
VAL_ 1267 IRZCU_NWI_CHCANFD 0 "RZCU_NWI_CHCANFD_0_NoWakeNetworkSource" 1 "RZCU_NWI_CHCANFD_1_PowerModeIsRuncrank" 2 "RZCU_NWI_CHCANFD_2_ThermalFaultActive" 5 "RZCU_NWI_CHCANFD_5_OffboardChargerConnected" 8 "RZCU_NWI_CHCANFD_8_PLGOpenDetectByPriMarySwitch" 9 "RZCU_NWI_CHCANFD_9_PLGCloseDetectByPriMarySwitch" 10 "RZCU_NWI_CHCANFD_10_PLGOpenDetectBySecondarySwitch" 12 "RZCU_NWI_CHCANFD_12_PwrlftgtCloseRequest" 15 "RZCU_NWI_CHCANFD_15_EasyLdSwthReqRequest" 16 "RZCU_NWI_CHCANFD_16_ChrgFlapDoorAjarSwActive" 17 "RZCU_NWI_CHCANFD_17_RrSeatBrkSwActive";
VAL_ 1267 IRZCU_NOI_CHCANFD 0 "RZCU_NOI_CHCANFD_0_NoRequest" 65535 "RZCU_NOI_CHCANFD_65535_AllNetworkOperationActive";
VAL_ 1267 IRZCU_NKI_CHCANFD 0 "RZCU_NKI_CHCANFD_0_NoRequest" 1 "RZCU_NKI_CHCANFD_1_PowerModeIsNonOFF" 2 "RZCU_NKI_CHCANFD_2_ThermalFaultActive" 16 "RZCU_NKI_CHCANFD_16_HVBulid" 256 "RZCU_NKI_CHCANFD_256_RWSActive" 512 "RZCU_NKI_CHCANFD_512_ChargerFlapTimeWindow" 1024 "RZCU_NKI_CHCANFD_1024_EasyLdSwthReqRequest";
VAL_ 247 IEPTTrOtptShaftTotMinAvlblToqV 0 "EPTTrOtptShaftTotMinAvlblToqV_0_Valid" 1 "EPTTrOtptShaftTotMinAvlblToqV_1_Invalid";
VAL_ 247 IEPTTrOtptShaftTotMaxAvlblToqV 0 "EPTTrOtptShaftTotMaxAvlblToqV_0_Valid" 1 "EPTTrOtptShaftTotMaxAvlblToqV_1_Invalid";
VAL_ 247 IEPTTrOtptShaftTotToqV 0 "EPTTrOtptShaftTotToqV_0_Valid" 1 "EPTTrOtptShaftTotToqV_1_Invalid";
VAL_ 201 IVCUAPAUnderCtrlA 0 "VCUAPAUnderCtrlA_0_Inhibit" 1 "VCUAPAUnderCtrlA_1_Available" 2 "VCUAPAUnderCtrlA_2_ActiveForSpeedControl" 3 "VCUAPAUnderCtrlA_3_ActiveForTorqueControl" 4 "VCUAPAUnderCtrlA_4_Failed" 5 "VCUAPAUnderCtrlA_5_Reserved" 6 "VCUAPAUnderCtrlA_6_Reserved" 7 "VCUAPAUnderCtrlA_7_Reserved";
VAL_ 201 IVCUAPAFltRsn 0 "VCUAPAFltRsn_0_Normal" 1 "VCUAPAFltRsn_1_SpeedResponseOverTime" 2 "VCUAPAFltRsn_2_TorqueResponseOverTime" 3 "VCUAPAFltRsn_3_VCUInternal_Fault" 4 "VCUAPAFltRsn_4_Reserved" 5 "VCUAPAFltRsn_5_Reserved" 6 "VCUAPAFltRsn_6_Reserved" 7 "VCUAPAFltRsn_7_Reserved";
VAL_ 201 IEPTAPARevrDrgReqResp 0 "EPTAPARevrDrgReqResp_0_Default" 1 "EPTAPARevrDrgReqResp_1_Intervene" 2 "EPTAPARevrDrgReqResp_2_InterveneOff" 3 "EPTAPARevrDrgReqResp_3_Reserved";
VAL_ 143 IAngularRateXsecinfoV 0 "AngularRateXsecinfoV_0_Valid" 1 "AngularRateXsecinfoV_1_Invalid";
VAL_ 143 IAccelerationZsecinfoV 0 "AccelerationZecinfoV_0_Valid" 1 "AccelerationZsecinfoV_1_Invalid";
VAL_ 143 IAccelerationYsecinfoV 0 "AccelerationYsecinfoV_0_Valid" 1 "AccelerationYsecinfoV_1_Invalid";
VAL_ 143 IAccelerationXsecinfoV 0 "AccelerationXsecinfoV_0_Valid" 1 "AccelerationXsecinfoV_1_Invalid";
VAL_ 143 ITireBlowoutStabCtrlSts 0 "TireBlowoutStabCtrlSts_0_Inactive" 1 "TireBlowoutStabCtrlSts_1_Active";
VAL_ 143 IAngularRateZsecinfoV 0 "AngularRateZsecinfoV_0_Valid" 1 "AngularRateZsecinfoV_1_Invalid";
VAL_ 143 IAngularRateYsecinfoV 0 "AngularRateYsecinfoV_0_Valid" 1 "AngularRateYsecinfoV_1_Invalid";
VAL_ 143 ITireBlowoutPos 0 "TireBlowoutPos_0_No_Tire_Blowout" 1 "TireBlowoutPos_1_FL_Tire_Blowout" 2 "TireBlowoutPos_2_FR_Tire_Blowout" 3 "TireBlowoutPos_3_FL_FR_Tire_Blowout" 4 "TireBlowoutPos_4_RL_Tire_Blowout" 5 "TireBlowoutPos_5_FL_RL_Tire_Blowout" 6 "TireBlowoutPos_6_FR_RL_Tire_Blowout" 7 "TireBlowoutPos_7_FL_FR_RL_Tire_Blowout" 8 "TireBlowoutPos_8_RR_Tire_Blowout" 9 "TireBlowoutPos_9_FL_RR_Tire_Blowout" 10 "TireBlowoutPos_10_FR_RR_Tire_Blowout" 11 "TireBlowoutPos_11_FL_FR_RR_Tire_Blowout" 12 "TireBlowoutPos_12_RL_RR_Tire_Blowout" 13 "TireBlowoutPos_13_FL_RL_RR_Tire_Blowout" 14 "TireBlowoutPos_14_FR_RL_RR_Tire_Blowout" 15 "TireBlowoutPos_15_FL_FR_RL_RR_Tire_Blowout";
VAL_ 1216 IZXD_NM_BSMtoRMS_CHCANFD 0 "ZXD_NM_BSMtoRMS_CHCANFD_0_False" 1 "ZXD_NM_BSMtoRMS_CHCANFD_1_True";
VAL_ 1216 IZXD_NM_PBSMtoRMS_CHCANFD 0 "ZXD_NM_PBSMtoRMS_CHCANFD_0_False" 1 "ZXD_NM_PBSMtoRMS_CHCANFD_1_True";
VAL_ 1216 IZXD_NM_RMStoNOS_CHCANFD 0 "ZXD_NM_RMStoNOS_CHCANFD_0_False" 1 "ZXD_NM_RMStoNOS_CHCANFD_1_True";
VAL_ 1216 IZXD_NM_RSStoNOS_CHCANFD 0 "ZXD_NM_RSStoNOS_CHCANFD_0_False" 1 "ZXD_NM_RSStoNOS_CHCANFD_1_True";
VAL_ 1216 IZXD_NM_RSStoRMS_CHCANFD 0 "ZXD_NM_RSStoRMS_CHCANFD_0_False" 1 "ZXD_NM_RSStoRMS_CHCANFD_1_True";
VAL_ 1216 IZXD_NM_NOStoRMS_CHCANFD 0 "ZXD_NM_NOStoRMS_CHCANFD_0_False" 1 "ZXD_NM_NOStoRMS_CHCANFD_1_True";
VAL_ 1216 IZXD_NM_NOSSta_CHCANFD 0 "ZXD_NM_NOSSta_CHCANFD_0_False" 1 "ZXD_NM_NOSSta_CHCANFD_1_True";
VAL_ 1216 IZXD_NM_RMSSta_CHCANFD 0 "ZXD_NM_RMSSta_CHCANFD_0_False" 1 "ZXD_NM_RMSSta_CHCANFD_1_True";
VAL_ 1216 IZXD_NWI_CHCANFD 0 "ZXD_NWI_CHCANFD_0_NoWakeNetworkSource" 1 "ZXD_NWI_CHCANFD_1_PowerModeIsNonOFF";
VAL_ 1216 IZXD_NOI_CHCANFD 0 "ZXD_NOI_CHCANFD_0_NoRequest" 65535 "ZXD_NOI_CHCANFD_65535_AllNetworkOperationActive";
VAL_ 1216 IZXD_NKI_CHCANFD 0 "ZXD_NKI_CHCANFD_0_NoRequest" 1 "ZXD_NKI_CHCANFD_1_PowerModeIsNonOFF";
VAL_ 308 IAPAEPBOPReq 0 "APAEPBOPReq_0_No_Request" 1 "APAEPBOPReq_1_Apply" 2 "APAEPBOPReq_2_Release";
VAL_ 308 IAPASCSAcclReqSts 0 "APASCSAcclReqSts_0_NoRequest" 1 "APASCSAcclReqSts_1_DecelerationRequest";
VAL_ 308 IAPAEPBOPReqV 0 "APAEPBOPReqV_0_Valid" 1 "APAEPBOPReqV_1_Invalid";
VAL_ 308 IAutodDrvngSysSCSSdslReqV 0 "AutodDrvngSysSCSSdslReqV_0_Valid" 1 "AutodDrvngSysSCSSdslReqV_1_Invalid";
VAL_ 308 IAutodDrvngSysSCSSdslReq 0 "AutodDrvngSysSCSSdslReq_0_NoRequest" 1 "AutodDrvngSysSCSSdslReq_1_request";
VAL_ 308 IAutodDrvngSysSCSDrvOffReqV 0 "AutodDrvngSysSCSDrvOffReqV_0_Valid" 1 "AutodDrvngSysSCSDrvOffReqV_1_Invalid";
VAL_ 308 IAutodDrvngSysSCSDrvOffReq 0 "AutodDrvngSysSCSDrvOffReq_0_NoRequest" 1 "AutodDrvngSysSCSDrvOffReq_1_DriveOffRequest";
VAL_ 308 IAutodDrvngSysMdReqV 0 "AutodDrvngSysMdReqV_0_Valid" 1 "AutodDrvngSysMdReqV_1_Invalid";
VAL_ 308 IAutodDrvngSysMdReq 0 "AutodDrvngSysMdReq_0_DriverModeRequest" 1 "AutodDrvngSysMdReq_1_AutomatedDriverModeRequest";
VAL_ 308 IAutodDrvngSysFlrStsV 0 "AutodDrvngSysFlrStsV_0_Valid" 1 "AutodDrvngSysFlrStsV_1_Invalid";
VAL_ 308 IAutodDrvngSysFlrSts 0 "AutodDrvngSysFlrSts_0_NoError" 1 "AutodDrvngSysFlrSts_1_PerformanceDegradation" 2 "AutodDrvngSysFlrSts_2_SystemUnavailable" 3 "AutodDrvngSysFlrSts_3_Reserved" 4 "AutodDrvngSysFlrSts_4_Reserved" 5 "AutodDrvngSysFlrSts_5_Reserved" 6 "AutodDrvngSysFlrSts_6_Reserved" 7 "AutodDrvngSysFlrSts_7_Reserved";
VAL_ 429 IEPSAESReqResp 0 "EPSAESResp_0_Inhibit" 1 "EPSAESReqResp_1_Available" 2 "EPSAESReqResp_2_Active" 3 "EPSAESReqResp_3_Abort" 4 "EPSAESReqResp_4_ReplyForControl" 5 "EPSAESReqResp_5_Reserve" 6 "EPSAESReqResp_6_Reserve" 7 "EPSAESResp_7_Failure" 8 "EPSAESResp_8_Reserve";
VAL_ 429 IEPSAESStsInh 0 "EPSAIPkgAngReqResp_0_Inhibit" 1 "EPSAIPkgAngReqResp_1_Available" 2 "EPSAIPkgAngReqResp_2_Active" 3 "EPSAIPkgAngReqResp_3_Abort" 4 "EPSAIPkgAngReqResp_4_ReplyForControl" 5 "EPSAIPkgAngReqResp_5_Reserve" 6 "EPSAIPkgAngReqResp_6_Reserve" 7 "EPSAIPkgAngReqResp_7_Failure" 8 "EPSAIPkgAngReqResp_8_Reserve";
VAL_ 429 IEPSVMCAngRespSts 0 "EPSVMCAngRespSts_0_Init" 1 "EPSVMCAngRespSts_1_Off" 2 "EPSVMCAngRespSts_2_Ready" 3 "EPSVMCAngRespSts_3_Fadeln" 4 "EPSVMCAngRespSts_4_Active" 5 "EPSVMCAngRespSts_5_FadeOut" 6 "EPSVMCAngRespSts_6_Error" 7 "EPSVMCAngRespSts_7_Reserved";
VAL_ 429 IEPSAESReqTorRespV 0 "EPSAESReqTorV_0_Valid" 1 "EPSAESReqTorV_1_Invalid";
VAL_ 429 IEPSVMCRespStsInh 0 "EPSVMCRespStsInh_0_NormalOperation" 1 "EPSVMCRespStsInh_1_OverSpeed" 2 "EPSVMCRespStsInh_2_DriverInterference" 4 "EPSVMCRespStsInh_4_AbnormalCanInput" 8 "EPSVMCRespStsInh_8_Reserve" 16 "EPSVMCRespStsInh_16_EpsFailure" 32 "EPSVMCRespStsInh_32_Reserve" 64 "EPSVMCRespStsInh_64_Reserve" 128 "EPSVMCRespStsInh_128_Reserve";
VAL_ 429 IEPSVMCCodrivingSts 0 "EPSVMCCodrivingSts_0_Unavaliable" 1 "EPSVMCCodrivingSts_1_Non_Co_DrivingMode" 2 "EPSVMCCodrivingSts_2_Co_DrivingMode" 3 "EPSVMCCodrivingSts_3_Reserved";
VAL_ 429 IActuRoadWhlAngV 0 "ActuRoadWhlAngV_0_Valid" 1 "ActuRoadWhlAngV_1_Invalid";
VAL_ 429 IADASStrgDlvrdToqV 0 "ADASStrgDlvrdToqV_0_Valid" 1 "ADASStrgDlvrdToqV_1_Invalid";
VAL_ 429 IEPSDrvngMdCtrlInh 0 "EPSDrvngMdCtrlInh_0_False" 1 "EPSDrvngMdCtrlInh_1_True";
VAL_ 429 IDrvrStrgDlvrdToqV 0 "DrvrStrgDlvrdToqV_0_Valid" 1 "DrvrStrgDlvrdToqV_1_Invalid";
VAL_ 429 IStrgCustSetngDspCmd 0 "StrgCustSetngDspCmd_0_FunctionDisable" 1 "StrgCustSetngDspCmd_1_ComfortableMode" 2 "StrgCustSetngDspCmd_2_NormalMode" 3 "StrgCustSetngDspCmd_3_SportMode";
VAL_ 429 IEPSPriyChnlFlrSts 0 "EPSPriyChnlFlrSts_0_NoFailure" 1 "EPSPriyChnlFlrSts_1_LightLevelFailure" 2 "EPSPriyChnlFlrSts_2_HeavyLevelFailure";
VAL_ 429 IEPSFlrSts 0 "EPSFlrSts_0_EpsNoFailure_indicationOff" 1 "EPSFlrSts_1_EpsLightLevelFailureIndication_orange" 2 "EPSFlrSts_2_EpsHeavyLevelFailureIndication_red" 3 "EPSFlrSts_3_Invalid";
VAL_ 429 IEPSCurntDrvMd 0 "EPSCurntDrvMd_0_ADASMode" 1 "EPSCurntDrvMd_1_ComfortableMode" 2 "EPSCurntDrvMd_2_NormalMode" 3 "EPSCurntDrvMd_3_SportMode";
VAL_ 429 IActuPnonAngV 0 "ActuPnonAngV_0_Valid" 1 "ActuPnonAngV_1_Invalid";
VAL_ 429 IEPSToqValAldMaxV 0 "EPSToqValAldMaxV_0_Valid" 1 "EPSToqValAldMaxV_1_Invalid";
VAL_ 429 IEPSLimMotToqV 0 "EPSLimMotToqV_0_Valid" 1 "EPSLimMotToqV_1_Invalid";
VAL_ 429 IEPSActRetMotToqV 0 "EPSActRetMotToqV_0_Valid" 1 "EPSActRetMotToqV_1_Invalid";
VAL_ 429 IChLKAAngReqResp 0 "ChLKAAngReqResp_0_NoRequest" 1 "ChLKAAngReqResp_1_RequestHonored" 2 "ChLKAAngReqResp_2_LostArbitrary" 3 "ChLKAAngReqResp_3_ControlNotAllowedForFailure" 4 "ChLKAAngReqResp_4_Pre_conditionNotSatisfied" 5 "ChLKAAngReqResp_5_Initialization" 6 "ChLKAAngReqResp_6_EMA" 7 "ChLKAAngReqResp_7_Reserved";
VAL_ 429 IEPSToqValAldMinV 0 "EPSToqValAldMinV_0_Valid" 1 "EPSToqValAldMinV_1_Invalid";
VAL_ 429 ICHLKAHptResp 0 "CHLKAHptResp_0_NoRequest" 1 "CHLKAHptResp_1_RequestHonored" 2 "CHLKAHptResp_2_LostArbitrary" 3 "CHLKAHptResp_3_ControlNotAllowedForFailure" 4 "CHLKAHptResp_4_Pre_conditionNotSatisfied" 5 "CHLKAHptResp_5_Initialization";
VAL_ 429 IChLKAToqReqResp 0 "ChLKAToqReqResp_0_NoRequest" 1 "ChLKAToqReqResp_1_RequestHonored" 2 "ChLKAToqReqResp_2_LostArbitrary" 3 "ChLKAToqReqResp_3_ControlNotAllowedForFailure" 4 "ChLKAToqReqResp_4_Pre_conditionNotSatisfied" 5 "ChLKAToqReqResp_5_Initialization" 6 "ChLKAToqReqResp_6_Reserved" 7 "ChLKAToqReqResp_7_Reserved";
VAL_ 429 IEPSCoDrivingSts 0 "EPSCoDrivingSts_0_Unavaliable" 1 "EPSCoDrivingSts_1_Non_Co_DrivingMode" 2 "EPSCoDrivingSts_2_Co_DrivingMode" 3 "EPSCoDrivingSts_3_Reserved";
VAL_ 429 IEPSAIPkgAngReqResp 0 "EPSAIPkgAngReqResp_0_Inhibit" 1 "EPSAIPkgAngReqResp_1_Available" 2 "EPSAIPkgAngReqResp_2_Active" 3 "EPSAIPkgAngReqResp_3_Abort" 4 "EPSAIPkgAngReqResp_4_ReplyForControl" 5 "EPSAIPkgAngReqResp_5_Reserve" 6 "EPSAIPkgAngReqResp_6_Reserve" 7 "EPSAIPkgAngReqResp_7_Failure" 8 "EPSAIPkgAngReqResp_8_Reserve";
VAL_ 429 IEPSAIPkgAngReqRespInh 0 "EPSAIPkgAngReqRespInh_0_NormalOperation" 1 "EPSAIPkgAngReqRespInh_1_OverSpeed" 2 "EPSAIPkgAngReqRespInh_2_DriverInterference" 4 "EPSAIPkgAngReqRespInh_4_AbnormalCanInput" 8 "EPSAIPkgAngReqRespInh_8_ExcessAngleDeviation" 16 "EPSAIPkgAngReqRespInh_16_EpsFailure" 32 "EPSAIPkgAngReqRespInh_32_Reserve" 64 "EPSAIPkgAngReqRespInh_64_Reserve" 128 "EPSAIPkgAngReqRespInh_128_Reserve";
VAL_ 429 IEPSAIPltAngRespStsInh 0 "EPSAIPltAngRespStsInh_0_NormalOperation" 1 "EPSAIPltAngRespStsInh_1_OverSpeed" 2 "EPSAIPltAngRespStsInh_2_DriverInterference" 4 "EPSAIPltAngRespStsInh_4_AbnormalCanInputtoIPD" 8 "EPSAIPltAngRespStsInh_8_AbnormalCanInputtoICB" 16 "EPSAIPltAngRespStsInh_10_EpsFailure" 18 "EPSAIPltAngRespStsInh_12_AbnormalCanInputtoIPDandICB" 32 "EPSAIPltAngRespStsInh_20_Reserve" 64 "EPSAIPltAngRespStsInh_40_Reserve" 128 "EPSAIPltAngRespStsInh_80_Reserve";
VAL_ 429 IEPSAIPltAvlLvl 0 "EPSAIPltAvlLvl_0_HadNotAvailable" 1 "EPSAIPltAvlLvl_1_HadAvailableDegraded" 2 "EPSAIPltAvlLvl_2_HadAvailable" 3 "EPSAIPltAvlLvl_3_Minor_Error";
VAL_ 429 IEPSAIPltAngRespSts 0 "EPSAIPltAngRespSts_0_Init" 1 "EPSAIPltAngRespSts_1_Off" 2 "EPSAIPltAngRespSts_2_Ready" 3 "EPSAIPltAngRespSts_3_Fadeln" 4 "EPSAIPltAngRespSts_4_HO_Active" 5 "EPSAIPltAngRespSts_5_Emergency_function_active" 6 "EPSAIPltAngRespSts_6_Error" 7 "EPSAIPltAngRespSts_7_HF_active";
VAL_ 429 IActuRoadWhlAngGrdV 0 "ActuRoadWhlAngGrdV_0_Valid" 1 "ActuRoadWhlAngGrdV_1_Invalid";
VAL_ 429 IEPSAIPltCtrlChannel 0 "EPSAIPltCtrlChannel_0_Primary" 1 "EPSAIPltCtrlChannel_1_Secondary";
VAL_ 429 IActuRoadWhlAngGrd 65535 "ActuRoadWhlAngGrd_65535_error_mark";
VAL_ 173 IStrgWhlAngSnsrFlt 0 "StrgWhlAngSnsrFlt_0_False" 1 "StrgWhlAngSnsrFlt_1_True";
VAL_ 173 IStrgWhlAngV 0 "StrgWhlAngV_0_Valid" 1 "StrgWhlAngV_1_Invalid";
VAL_ 173 IStrgWhlAngSnsrMultCapb 0 "StrgWhlAngSnsrMultCapb_0_False" 1 "StrgWhlAngSnsrMultCapb_1_True";
VAL_ 173 IStrgWhlAngSnsrInid 0 "StrgWhlAngSnsrInid_0_False" 1 "StrgWhlAngSnsrInid_1_True";
VAL_ 173 IStrgWhlAng 65535 "StrgWhlAng_65535_ErrorMark";
VAL_ 173 IStrgWhlAngGrd 4095 "StrgWhlAngGrd_4095_ErrorMark";
VAL_ 173 IStrgWhlAngSnsrCalSts 0 "StrgWhlAngSnsrCalSts_0_Unknown" 1 "StrgWhlAngSnsrCalSts_1_Estimated" 2 "StrgWhlAngSnsrCalSts_2_Calibrated" 3 "StrgWhlAngSnsrCalSts_3_Unknown";
VAL_ 184 IBrkSysBrkLghtsReqd 0 "BrkSysBrkLghtsReqd_0_False" 1 "BrkSysBrkLghtsReqd_1_True";
VAL_ 184 IBrkPdlPosV 0 "BrkPdlPosV_0_Valid" 1 "BrkPdlPosV_1_Invalid";
VAL_ 184 IActuOtptRodTrvlSts 0 "ActuOtptRodTrvlSts_0_Init" 1 "ActuOtptRodTrvlSts_1_Normal" 2 "ActuOtptRodTrvlSts_2_Faulty";
VAL_ 394 IBrkPdlDrvrAppdPrsV 0 "BrkPdlDrvrAppdPrsV_0_Valid" 1 "BrkPdlDrvrAppdPrsV_1_Invalid";
VAL_ 394 IBrkPdlDrvrAppdPrsDetV 0 "BrkPdlDrvrAppdPrsDetV_0_Valid" 1 "BrkPdlDrvrAppdPrsDetV_1_Invalid";
VAL_ 394 IBrkPdlDrvrAppdPrsDet 0 "BrkPdlDrvrAppdPrsDet_0_False" 1 "BrkPdlDrvrAppdPrsDet_1_True";
VAL_ 394 IBrkDiscTemSts 0 "BrkDiscTemSts_0_Not_high" 1 "BrkDiscTemSts_1_Temperature_too_high";
VAL_ 394 IBrkPdlMdlSts 0 "BrkPdlMdlSts_0_Normal" 1 "BrkPdlMdlSts_1_comfort" 2 "BrkPdlMdlSts_2_sport" 3 "BrkPdlMdlSts_3_Reserve";
VAL_ 394 IDrvrReqOtptRodTrvlSts 0 "DrvrReqOtptRodTrvlSts_0_Init" 1 "DrvrReqOtptRodTrvlSts_1_Normal" 2 "DrvrReqOtptRodTrvlSts_2_Faulty";
VAL_ 394 IBrkPdlSimltdPrsV 0 "BrkPdlSimltdPrsV_0_Valid" 1 "BrkPdlSimltdPrsV_1_Invalid";
VAL_ 394 IBrkPdlAppd 0 "BrkPdlAppd_0_BrakePedalNotApplied" 1 "BrkPdlAppd_1_BrakePedalApplied";
VAL_ 394 IBrkPdlAppdV 0 "BrkPdlAppdV_0_Init" 1 "BrkPdlAppdV_1_Normal" 2 "BrkPdlAppdV_2_Faulty";
VAL_ 394 IBrkFludLvlLowV 0 "BrkFludLvlLowV_0_Valid" 1 "BrkFludLvlLowV_1_Invalid";
VAL_ 394 IBrkFludLvlLow 0 "BrkFludLvlLow_0_False" 1 "BrkFludLvlLow_1_True";
VAL_ 394 IBrkPdlMdlActSts 0 "BrkPdlMdlActSts_0_Normal" 1 "BrkPdlMdlActSts_1_comfort" 2 "BrkPdlMdlActSts_2_sport" 3 "BrkPdlMdlActSts_3_Reserve";
VAL_ 394 IACCBrkngA 0 "ACCBrkngA_0_False" 1 "ACCBrkngA_1_True";
VAL_ 394 IChAEBDclReqResp 0 "ChAEBDclReqResp_0_no_request" 1 "ChAEBDclReqResp_1_request_honored" 2 "ChAEBDclReqResp_2_lost_arbitration" 3 "ChAEBDclReqResp_3_control_not_allowed_for_error" 4 "ChAEBDclReqResp_4_pre_condition_not_satisfied" 5 "ChAEBDclReqResp_5_Request_received_no_fault_but_not_honoured" 6 "ChAEBDclReqResp_6_Reserved" 7 "ChAEBDclReqResp_7_Reserved";
VAL_ 394 IChACCReqFlrSts 0 "ChACCReqFlrSts_0_No_error" 1 "ChACCReqFlrSts_1_reversible_error" 2 "ChACCReqFlrSts_2_irreversible_error" 3 "ChACCReqFlrSts_3_not_defined";
VAL_ 394 IChACCAccReqResp 0 "ChACCAccReqResp_0_no_request" 1 "ChACCAccReqResp_1_request_honored" 2 "ChACCAccReqResp_2_lost_arbitration" 3 "ChACCAccReqResp_3_control_not_allowed_for_error" 4 "ChACCAccReqResp_4_pre_condition_not_satisfied" 5 "ChACCAccReqResp_5_Request_received_no_fault_but_not_honoured" 6 "ChACCAccReqResp_6_Reserved" 7 "ChACCAccReqResp_7_Reserved";
VAL_ 394 IChAEBPrflReqResp 0 "ChAEBPrflReqResp_0_no_request" 1 "ChAEBPrflReqResp_1_request_honored" 2 "ChAEBPrflReqResp_2_lost_arbitration" 3 "ChAEBPrflReqResp_3_control_not_allowed_for_error" 4 "ChAEBPrflReqResp_4_pre_condition_not_satisfied" 5 "ChAEBPrflReqResp_5_Request_received_no_fault_but_not_honoured" 6 "ChAEBPrflReqResp_6_Reserved" 7 "ChAEBPrflReqResp_7_Reserved";
VAL_ 394 IAutodDrvngSysMdReqRespV 0 "AutodDrvngSysMdReqRespV_0_Valid" 1 "AutodDrvngSysMdReqRespV_1_Invalid";
VAL_ 394 IAutodDrvngSysMdReqResp 0 "AutodDrvngSysMdReqResp_0_NoRequest" 1 "AutodDrvngSysMdReqResp_1_ReqestHonred";
VAL_ 394 IChAEBHydBrkAstReqResp 0 "ChAEBHydBrkAstReqResp_0_no_request" 1 "ChAEBHydBrkAstReqResp_1_request_honored" 2 "ChAEBHydBrkAstReqResp_2_lost_arbitration" 3 "ChAEBHydBrkAstReqResp_3_control_not_allowed_for_error" 4 "ChAEBHydBrkAstReqResp_4_pre_condition_not_satisfied" 5 "ChAEBHydBrkAstReqResp_5_Request_received_no_fault_but_not_honoured" 6 "ChAEBHydBrkAstReqResp_6_Reserved" 7 "ChAEBHydBrkAstReqResp_7_Reserved";
VAL_ 394 IChAEBBrkJerkReqResp 0 "ChAEBBrkJerkReqResp_0_no_request" 1 "ChAEBBrkJerkReqResp_1_request_honored" 2 "ChAEBBrkJerkReqResp_2_lost_arbitration" 3 "ChAEBBrkJerkReqResp_3_control_not_allowed_for_error" 4 "ChAEBBrkJerkReqResp_4_pre_condition_not_satisfied" 5 "ChAEBBrkJerkReqResp_5_Request_received_no_fault_but_not_honoured" 6 "ChAEBBrkJerkReqResp_6_reserved6" 7 "ChAEBBrkJerkReqResp_7_reserved7";
VAL_ 394 ISCSAutodDrvngSysSts 0 "SCSAutodDrvngSysSts_0_TemporaryNotAvailable" 1 "SCSAutodDrvngSysSts_1_TemporaryNotReleased" 2 "SCSAutodDrvngSysSts_2_PermanentNotAvailable" 3 "SCSAutodDrvngSysSts_3_FullAvailable" 4 "SCSAutodDrvngSysSts_4_RedudancyLost" 5 "SCSAutodDrvngSysSts_5_FailOperation";
VAL_ 394 ISCSAPAAcclAV 0 "SCSAPAAcclAV_0_Valid" 1 "SCSAPAAcclAV_1_Invalid";
VAL_ 394 ISCSAPAAcclA 0 "SCSAPAAcclA_0_Inactive" 1 "SCSAPAAcclA_1_Active";
VAL_ 394 IExtnlBrkPrioV 0 "ExtnlBrkPrioV_0_Valid" 1 "ExtnlBrkPrioV_1_Invalid";
VAL_ 394 IExtnlBrkPrio 0 "ExtnlBrkPrio_0_EBR_NotDominate" 1 "ExtnlBrkPrio_1_EBR_Dominate";
VAL_ 394 IEmgcBrkReqdByIECUSts 0 "EmgcBrkReqdByIECUSts_0_False" 1 "EmgcBrkReqdByIECUSts_1_True";
VAL_ 394 ITCSDrvrItnt 0 "TCSDrvrItnt_0_Disabled" 1 "TCSDrvrItnt_1_Enabled";
VAL_ 394 IMultColBrkAvlblySts 0 "MultColBrkAvlblySts_0_Unavailable" 1 "MultColBrkAvlblySts_1_Available";
VAL_ 394 IChRCTBDclReqResp 0 "ChRCTBDclReqResp_0_no_request" 1 "ChRCTBDclReqResp_1_request_honored" 2 "ChRCTBDclReqResp_2_lost_arbitration" 3 "ChRCTBDclReqResp_3_control_not_allowed_for_error" 4 "ChRCTBDclReqResp_4_pre_condition_not_satisfied" 5 "ChRCTBDclReqResp_5_request_received_not_fault_but_not_honored" 6 "ChRCTBDclReqResp_6_reserved" 7 "ChRCTBDclReqResp_7_reserved";
VAL_ 394 ISCSVehHoldAV 0 "SCSVehHoldAV_0_Valid" 1 "SCSVehHoldAV_1_Invalid";
VAL_ 394 ISCSVehHoldA 0 "SCSVehHoldA_0_NotActivelyHeld" 1 "SCSVehHoldA_1_ActivelyHeld";
VAL_ 394 ISCSAutodDrvngSysStsV 0 "SCSAutodDrvngSysStsV_0_Valid" 1 "SCSAutodDrvngSysStsV_1_Invalid";
VAL_ 394 IVehSdslStsV 0 "VehSdslStsV_0_Valid" 1 "VehSdslStsV_1_Invalid";
VAL_ 394 IChRCTBPrflReqResp 0 "ChRCTBPrflReqResp_0_no_request" 1 "ChRCTBPrflReqResp_1_request_honored" 2 "ChRCTBPrflReqResp_2_lost_arbitration" 3 "ChRCTBPrflReqResp_3_control_not_allowed_for_error" 4 "ChRCTBPrflReqResp_4_pre_condition_not_satisfied" 5 "ChRCTBPrflReqResp_5_reserved" 6 "ChRCTBPrflReqResp_6_reserved" 7 "ChRCTBPrflReqResp_7_reserved";
VAL_ 394 IWhlBrkPrsSts 0 "WhlBrkPrsSts_0_Exist_brake_force" 1 "WhlBrkPrsSts_1_No_brake_force";
VAL_ 394 IBrkSysRddySysSts 0 "BrkSysRddySysSts_0_FullAvailable" 1 "BrkSysRddySysSts_1_NotAvailable";
VAL_ 394 IVehSdslSts 0 "VehSdslSts_0_not_standstill" 1 "VehSdslSts_1_standstill" 2 "VehSdslSts_2_invalid_short_unavailability_max_3s" 3 "VehSdslSts_3_reserved";
VAL_ 394 IIBSAPASysFltSts 0 "IBSAPASysFltSts_0_FullAvailable" 1 "IBSAPASysFltSts_1_NotAvailable";
VAL_ 222 IAIPltEPSReqRdWhlAngV 0 "AIPltEPSReqRdWhlAngV_0_Valid" 1 "AIPltEPSReqRdWhlAngV_1_Invalid";
VAL_ 222 IPltEPSRdWhlAngReqStsV 0 "PltEPSRdWhlAngReqStsV_0_Valid" 1 "PltEPSRdWhlAngReqStsV_1_Invalid";
VAL_ 222 IPltEPSRdWhlAngReqSts 0 "PltEPSRdWhlAngReqSts_0_Off" 1 "PltEPSRdWhlAngReqSts_1_Hands_On_Request_Ready" 2 "PltEPSRdWhlAngReqSts_2_Hands_On_Request_Active" 3 "PltEPSRdWhlAngReqSts_3_Hands_Free_Request_Ready" 4 "PltEPSRdWhlAngReqSts_4_Hands_Free_Request_Active" 5 "PltEPSRdWhlAngReqSts_5_Emergency_function";
SIG_GROUP_ 337 IIPD_20ms_Group60 1 : IALCSysFltSts IALCSysSts IAPASCSToqReqVal IAPAVehCrdnatAzmth IAPAVehCrdnatPosX IAPAVehCrdnatPosY IAutoLaneChngLLaneSts IAutoLaneChngRLaneSts IESSDirInd IESSDrvrTkovReq IESSSysFltSts IESSSysSts IIPD_20ms_Group60_CRC IIPD_20ms_Group60_RC IIPD_20ms_Group60_Reserved1 IIPD_20ms_Group60_Reserved10 IIPD_20ms_Group60_Reserved2 IIPD_20ms_Group60_Reserved3 IIPD_20ms_Group60_Reserved4 IIPD_20ms_Group60_Reserved5 IIPD_20ms_Group60_Reserved6 IIPD_20ms_Group60_Reserved7 IIPD_20ms_Group60_Reserved8 IIPD_20ms_Group60_Reserved9 INOPSysFltSts INOPSysSts_ZPD IParkngslottype IPilotTkovMsgReq IPrkgDstCtrlSwResp ISLIFSysFltSts;
SIG_GROUP_ 157 ILHZCU_10ms_Group01 1 : IDigKeyAuthReq IDigKeyPEValidReq IDrvrReqParkBtn IKeyAuthResp ILHZCU_10ms_Group01_CRC ILHZCU_10ms_Group01_RC ILHZCU_10ms_Group01_Reserved1 ILHZCU_10ms_Group01_Reserved2 ISCUAPAUnderCtrlActv ISCUDrvMd ISCUDrvrIntrvnActv ISCUExtdShiftrFlr ISCUFltLvlWarn ISCUParkLckReq ISCUParkLckReqEPMCU ISCUParkLckReqV ISCUParkLckReqVEPMCU ISCUShiftrLvrPosn ISCUShiftrLvrPosnLtchActv ISCUShiftrLvrRawPosn ISCUShiftrOpngRmndr ISCUShiftrPosnInvsn IScurtKeyInvd ISecuKeyVldSts;
SIG_GROUP_ 546 ILHZCU_50ms_Group07 1 : IHODDetnSts IHODSysSts IHODTchZone1Sts IHODTchZone1Val IHODTchZone2Sts IHODTchZone2Val IHODTchZone3Sts IHODTchZone3Val IHODdiagSts ILHZCU_50ms_Group07_CRC ILHZCU_50ms_Group07_RC ILHZCU_50ms_Group07_Reserved1 ILHZCU_50ms_Group07_Reserved2 ILHZCU_50ms_Group07_Reserved3 ILHZCU_50ms_Group07_Reserved4 ILHZCU_50ms_Group07_Reserved5 ILHZCU_50ms_Group07_Reserved6;
SIG_GROUP_ 247 IRZCU_10ms_Group22 1 : IEPTTrOtptShaftTotMaxAvlblToq IEPTTrOtptShaftTotMaxAvlblToqV IEPTTrOtptShaftTotMinAvlblToq IEPTTrOtptShaftTotMinAvlblToqV IEPTTrOtptShaftTotToq IEPTTrOtptShaftTotToqV IRZCU_10ms_Group22_CRC IRZCU_10ms_Group22_RC IRZCU_10ms_Group22_Reserved1 IRZCU_10ms_Group22_Reserved2 IRZCU_10ms_Group22_Reserved3 IRZCU_10ms_Group22_Reserved4 IRZCU_10ms_Group22_Reserved5 IRZCU_10ms_Group22_Reserved6 IRZCU_10ms_Group22_Reserved7;
SIG_GROUP_ 201 IRZCU_10ms_Group24 1 : IEPTAPARevrDrgReqResp IRZCU_10ms_Group24_CRC IRZCU_10ms_Group24_RC IRZCU_10ms_Group24_Reserved1 IRZCU_10ms_Group24_Reserved2 IRZCU_10ms_Group24_Reserved3 IRZCU_10ms_Group24_Reserved4 IRZCU_10ms_Group24_Reserved5 IRZCU_10ms_Group24_Reserved6 IVCUAPAFltRsn IVCUAPAUnderCtrlA;
SIG_GROUP_ 143 IRZCU_ZONE_10ms_Group64 1 : IAccelerationXsecinfo IAccelerationXsecinfoV IAccelerationYsecinfo IAccelerationYsecinfoV IAccelerationZsecinfo IAccelerationZsecinfoV IAngularRateXsecinfo IAngularRateXsecinfoV IAngularRateYsecinfo IAngularRateYsecinfoV IAngularRateZsecinfo IAngularRateZsecinfoV IIMUTmp IIMUseq IRZCU_ZONE_10ms_Group64_CRC IRZCU_ZONE_10ms_Group64_RC IRZCU_ZONE_10ms_Group64_Reserved0 IRZCU_ZONE_10ms_Group64_Reserved1 IRZCU_ZONE_10ms_Group64_Reserved2 IRZCU_ZONE_10ms_Group64_Reserved3 IRZCU_ZONE_10ms_Group64_Reserved4 IRZCU_ZONE_10ms_Group64_Reserved5 IRZCU_ZONE_10ms_Group64_Reserved6 ITireBlowoutPos ITireBlowoutStabCtrlSts;
SIG_GROUP_ 308 IZXD_20ms_Group07 1 : IAIPkgAPASCSAcclReqVal IAPAEPBOPReq IAPAEPBOPReqV IAPASCSAcclReqSts IAutodDrvngSysFlrSts IAutodDrvngSysFlrStsV IAutodDrvngSysMdReq IAutodDrvngSysMdReqV IAutodDrvngSysSCSDrvOffReq IAutodDrvngSysSCSDrvOffReqV IAutodDrvngSysSCSSdslReq IAutodDrvngSysSCSSdslReqV IZXD_20ms_Group07_CRC IZXD_20ms_Group07_RC IZXD_20ms_Group07_Reserved1 IZXD_20ms_Group07_Reserved2 IZXD_20ms_Group07_Reserved3 IZXD_20ms_Group07_Reserved4 IZXD_20ms_Group07_Reserved5 IZXD_20ms_Group07_Reserved6;
SIG_GROUP_ 429 EPS_010ms_PDU03 1 : IEPS_010ms_Group03_CRC IEPS_010ms_Group03_RC IEPSAESReqResp IEPSAESStsInh IEPSAESReqTorResp IEPS_010ms_Group03_Reserved1 IEPSVMCAngRespSts IEPSAESReqTorRespV IEPSVMCRespStsInh IEPS_010ms_Group03_Reserved2 IEPSVMCCodrivingSts IEPS_010ms_Group03_Reserved3;
SIG_GROUP_ 429 EPS_10ms_PDU01 2 : IEPS_10ms_Group01_CRC IEPS_10ms_Group01_RC IActuRoadWhlAngV IADASStrgDlvrdToqV IEPSDrvngMdCtrlInh IDrvrStrgDlvrdToqV IActuPnonAng IActuRoadWhlAng IStrgCustSetngDspCmd IEPSPriyChnlFlrSts IEPSFlrSts IEPSCurntDrvMd IActuPnonAngV IEPSToqValAldMaxV IEPSLimMotToqV IEPSActRetMotToqV IEPS_10ms_Group01_Reserved1 IChLKAAngReqResp IEPS_10ms_Group01_Reserved2 IEPSToqValAldMinV ICHLKAHptResp IEPS_10ms_Group01_Reserved3 IADASStrgDlvrdToq IEPS_10ms_Group01_Reserved4 IChLKAToqReqResp IEPSToqValAldMax IEPSCoDrivingSts IEPS_10ms_Group01_Reserved5 IEPSToqValAldMin IEPS_10ms_Group01_Reserved6 IEPSActRetMotToq IEPS_10ms_Group01_Reserved9 IDrvrStrgDlvrdToq IEPS_10ms_Group01_Reserved10 IEPS_10ms_Group01_Reserved11 IEPSLimMotToq;
SIG_GROUP_ 429 EPS_10ms_PDU02 3 : IEPS_10ms_Group02_CRC IEPS_10ms_Group02_RC IEPSAIPkgAngReqResp IEPSAIPkgAngReqRespInh IEPSAIPltAngRespStsInh IEPS_10ms_Group02_Reserved1 IEPSAIPltAvlLvl IEPSAIPltAngRespSts IActuRoadWhlAngGrdV IEPS_10ms_Group02_Reserved2 IEPSAIPltCtrlChannel IActuRoadWhlAngGrd;
SIG_GROUP_ 173 EPS_10ms_PDU05 1 : IEPS_10ms_Group05_CRC IEPS_10ms_Group05_RC IStrgWhlAngSnsrFlt IStrgWhlAngV IStrgWhlAngSnsrMultCapb IStrgWhlAngSnsrInid IStrgWhlAng IStrgWhlAngGrd IEPS_10ms_Group05_Reserved1 IStrgWhlAngSnsrCalSts IEPS_10ms_Group05_Reserved2 IEPS_10ms_Group05_Reserved3;
SIG_GROUP_ 184 IBS_10ms_PDU04 1 : IIBS_10ms_Group04_CRC IIBS_10ms_Group04_RC IIBS_10ms_Group04_Reserved1 IBrkPdlPos IIBS_10ms_Group04_Reserved2 IBrkSysBrkLghtsReqd IBrkPdlPosV IIBS_10ms_Group04_Reserved3 IIBS_10ms_Group04_Reserved4 IIBS_10ms_Group04_Reserved5 IIBS_10ms_Group04_Reserved6;
SIG_GROUP_ 184 IBS_10ms_PDU05 2 : IActuOtptRodTrvlSts IActuOtptRodTrvl;
SIG_GROUP_ 394 IBS_20ms_PDU10 1 : IIBS_20ms_Group10_CRC IIBS_20ms_Group10_RC IBrkPdlDrvrAppdPrsV IBrkPdlDrvrAppdPrsDetV IBrkPdlDrvrAppdPrsDet IBrkDiscTemSts IBrkPdlDrvrAppdPrs IBrkPdlMdlSts IDrvrReqOtptRodTrvlSts IBrkPdlSimltdPrsV IBrkPdlAppd IBrkPdlAppdV IBrkPdlSimltdPrs IBrkFludLvlLowV IBrkFludLvlLow IBrkPdlMdlActSts IIBS_20ms_Group10_Reserved1 IDrvrReqOtptRodTrvl IIBS_20ms_Group10_Reserved2;
SIG_GROUP_ 394 IBS_20ms_PDU13 2 : IIBS_20ms_Group13_CRC IIBS_20ms_Group13_RC IACCBrkngA IChAEBDclReqResp IChACCReqFlrSts IChACCAccReqResp IChAEBPrflReqResp IAutodDrvngSysMdReqRespV IAutodDrvngSysMdReqResp IChAEBHydBrkAstReqResp IChAEBBrkJerkReqResp ISCSAutodDrvngSysSts ISCSAPAAcclAV ISCSAPAAcclA IExtnlBrkPrioV IExtnlBrkPrio IEmgcBrkReqdByIECUSts ITCSDrvrItnt IMultColBrkAvlblySts IChRCTBDclReqResp ISCSVehHoldAV ISCSVehHoldA ISCSAutodDrvngSysStsV IVehSdslStsV IChRCTBPrflReqResp IWhlBrkPrsSts IBrkSysRddySysSts IVehSdslSts IIBS_20ms_Group13_Reserved1 IIBSAPASysFltSts;
SIG_GROUP_ 222 ICBAD_10ms_PDU01 1 : IICBAD_10ms_Group01_CRC IICBAD_10ms_Group01_RC IICBAD_10ms_Group01_Reserved1 IAIPltEPSReqRdWhlAngV IPltEPSRdWhlAngReqStsV IPltEPSRdWhlAngReqSts IICBAD_10ms_Group01_Reserved2 IICBAD_10ms_Group01_Reserved3 IICBAD_10ms_Group01_Reserved4 IAIPltEPSReqRdWhlAng IICBAD_10ms_Group01_Reserved5 IEPSToqAppdCoefnt;
